VERSION "ZCU_CANFD2"

NS_ :

BS_ :

BU_ :  ETC IHU ZCUD ZCUP

BO_ 293 DhuZCUCANFD2Fr21 : 64 IHU
 SG_ DrvModReqForChampnMod : 7|3@0+ (1,0) [0|7] "" ZCUD
 SG_ DrvModReqForChampnMod_UB : 4|1@0+ (1,0) [0|1] "" ZCUD
 SG_ MusicInfoSeg11_UB : 0|1@0+ (1,0) [0|1] "" ZCUP
 SG_ MusicInfoSeg11SegFftLiShow1 : 15|4@0+ (1.0,0.0) [0.0|15.0] "Unitless" ZCUP
 SG_ MusicInfoSeg11SegFftLiShow10 : 43|4@0+ (1.0,0.0) [0.0|15.0] "Unitless" ZCUP
 SG_ MusicInfoSeg11SegFftLiShow11 : 55|4@0+ (1.0,0.0) [0.0|15.0] "Unitless" ZCUP
 SG_ MusicInfoSeg11SegFftLiShow12 : 51|4@0+ (1.0,0.0) [0.0|15.0] "Unitless" ZCUP
 SG_ MusicInfoSeg11SegFftLiShow13 : 63|4@0+ (1.0,0.0) [0.0|15.0] "Unitless" ZCUP
 SG_ MusicInfoSeg11SegFftLiShow14 : 59|4@0+ (1.0,0.0) [0.0|15.0] "Unitless" ZCUP
 SG_ MusicInfoSeg11SegFftLiShow2 : 11|4@0+ (1.0,0.0) [0.0|15.0] "Unitless" ZCUP
 SG_ MusicInfoSeg11SegFftLiShow3 : 23|4@0+ (1.0,0.0) [0.0|15.0] "Unitless" ZCUP
 SG_ MusicInfoSeg11SegFftLiShow4 : 19|4@0+ (1.0,0.0) [0.0|15.0] "Unitless" ZCUP
 SG_ MusicInfoSeg11SegFftLiShow5 : 31|4@0+ (1.0,0.0) [0.0|15.0] "Unitless" ZCUP
 SG_ MusicInfoSeg11SegFftLiShow6 : 27|4@0+ (1.0,0.0) [0.0|15.0] "Unitless" ZCUP
 SG_ MusicInfoSeg11SegFftLiShow7 : 39|4@0+ (1.0,0.0) [0.0|15.0] "Unitless" ZCUP
 SG_ MusicInfoSeg11SegFftLiShow8 : 35|4@0+ (1.0,0.0) [0.0|15.0] "Unitless" ZCUP
 SG_ MusicInfoSeg11SegFftLiShow9 : 47|4@0+ (1.0,0.0) [0.0|15.0] "Unitless" ZCUP
 SG_ MusicInfoSeg11TimeFlagMessage : 71|4@0+ (1.0,0.0) [0.0|15.0] "Unitless" ZCUP
 SG_ MusicInfoSeg11TimeFlagMusicplay : 67|4@0+ (1.0,0.0) [0.0|15.0] "Unitless" ZCUP
 SG_ MusicInfoSeg12_UB : 1|1@0+ (1,0) [0|1] "" ZCUP
 SG_ MusicInfoSeg12SegFftLiShow15 : 79|4@0+ (1.0,0.0) [0.0|15.0] "Unitless" ZCUP
 SG_ MusicInfoSeg12SegFftLiShow16 : 75|4@0+ (1.0,0.0) [0.0|15.0] "Unitless" ZCUP
 SG_ MusicInfoSeg12SegFftLiShow17 : 87|4@0+ (1.0,0.0) [0.0|15.0] "Unitless" ZCUP
 SG_ MusicInfoSeg12SegFftLiShow18 : 83|4@0+ (1.0,0.0) [0.0|15.0] "Unitless" ZCUP
 SG_ MusicInfoSeg12SegFftLiShow19 : 95|4@0+ (1.0,0.0) [0.0|15.0] "Unitless" ZCUP
 SG_ MusicInfoSeg12SegFftLiShow20 : 91|4@0+ (1.0,0.0) [0.0|15.0] "Unitless" ZCUP
 SG_ MusicInfoSeg12SegFftLiShow21 : 103|4@0+ (1.0,0.0) [0.0|15.0] "Unitless" ZCUP
 SG_ MusicInfoSeg12SegFftLiShow22 : 99|4@0+ (1.0,0.0) [0.0|15.0] "Unitless" ZCUP
 SG_ MusicInfoSeg12SegFftLiShow23 : 111|4@0+ (1.0,0.0) [0.0|15.0] "Unitless" ZCUP
 SG_ MusicInfoSeg12SegFftLiShow24 : 107|4@0+ (1.0,0.0) [0.0|15.0] "Unitless" ZCUP
 SG_ MusicInfoSeg12SegFftLiShow25 : 119|4@0+ (1.0,0.0) [0.0|15.0] "Unitless" ZCUP
 SG_ MusicInfoSeg12SegFftLiShow26 : 115|4@0+ (1.0,0.0) [0.0|15.0] "Unitless" ZCUP
 SG_ MusicInfoSeg12SegFftLiShow27 : 127|4@0+ (1.0,0.0) [0.0|15.0] "Unitless" ZCUP
 SG_ MusicInfoSeg12SegFftLiShow28 : 123|4@0+ (1.0,0.0) [0.0|15.0] "Unitless" ZCUP
 SG_ MusicInfoSeg12TimeFlagMessage : 135|4@0+ (1.0,0.0) [0.0|15.0] "Unitless" ZCUP
 SG_ MusicInfoSeg12TimeFlagMusicplay : 131|4@0+ (1.0,0.0) [0.0|15.0] "Unitless" ZCUP
 SG_ MusicInfoSeg13_UB : 297|1@0+ (1,0) [0|1] "" ZCUP
 SG_ MusicInfoSeg13DownSamplingAmplitude : 271|4@0+ (1.0,0.0) [0.0|15.0] "Unitless" ZCUP
 SG_ MusicInfoSeg13MaxFFT100ms3kAmplitude : 267|4@0+ (1.0,0.0) [0.0|15.0] "Unitless" ZCUP
 SG_ MusicInfoSeg13MaxFFT100ms3kFrequency : 279|8@0+ (1.0,0.0) [0.0|255.0] "Unitless" ZCUP
 SG_ MusicInfoSeg13SegFftLiShow29 : 287|4@0+ (1.0,0.0) [0.0|15.0] "Unitless" ZCUP
 SG_ MusicInfoSeg13SegFftLiShow30 : 283|4@0+ (1.0,0.0) [0.0|15.0] "Unitless" ZCUP
 SG_ MusicInfoSeg13SegFftLiShow31 : 295|4@0+ (1.0,0.0) [0.0|15.0] "Unitless" ZCUP
 SG_ MusicInfoSeg13StateFlagMusicPlay : 299|1@0+ (1,0) [0|1] "" ZCUP
 SG_ MusicInfoSeg13StateFlagNewMusic : 298|1@0+ (1,0) [0|1] "" ZCUP
 SG_ MusicInfoSeg13TimeFlagMessage : 291|4@0+ (1.0,0.0) [0.0|15.0] "Unitless" ZCUP
 SG_ MusicInfoSeg13TimeFlagMusicplay : 303|4@0+ (1.0,0.0) [0.0|15.0] "Unitless" ZCUP
 SG_ MusicInfoSeg21_UB : 2|1@0+ (1,0) [0|1] "" ZCUP
 SG_ MusicInfoSeg21SegFftLiShow1 : 143|4@0+ (1.0,0.0) [0.0|15.0] "Unitless" ZCUP
 SG_ MusicInfoSeg21SegFftLiShow10 : 171|4@0+ (1.0,0.0) [0.0|15.0] "Unitless" ZCUP
 SG_ MusicInfoSeg21SegFftLiShow11 : 183|4@0+ (1.0,0.0) [0.0|15.0] "Unitless" ZCUP
 SG_ MusicInfoSeg21SegFftLiShow12 : 179|4@0+ (1.0,0.0) [0.0|15.0] "Unitless" ZCUP
 SG_ MusicInfoSeg21SegFftLiShow13 : 191|4@0+ (1.0,0.0) [0.0|15.0] "Unitless" ZCUP
 SG_ MusicInfoSeg21SegFftLiShow14 : 187|4@0+ (1.0,0.0) [0.0|15.0] "Unitless" ZCUP
 SG_ MusicInfoSeg21SegFftLiShow2 : 139|4@0+ (1.0,0.0) [0.0|15.0] "Unitless" ZCUP
 SG_ MusicInfoSeg21SegFftLiShow3 : 151|4@0+ (1.0,0.0) [0.0|15.0] "Unitless" ZCUP
 SG_ MusicInfoSeg21SegFftLiShow4 : 147|4@0+ (1.0,0.0) [0.0|15.0] "Unitless" ZCUP
 SG_ MusicInfoSeg21SegFftLiShow5 : 159|4@0+ (1.0,0.0) [0.0|15.0] "Unitless" ZCUP
 SG_ MusicInfoSeg21SegFftLiShow6 : 155|4@0+ (1.0,0.0) [0.0|15.0] "Unitless" ZCUP
 SG_ MusicInfoSeg21SegFftLiShow7 : 167|4@0+ (1.0,0.0) [0.0|15.0] "Unitless" ZCUP
 SG_ MusicInfoSeg21SegFftLiShow8 : 163|4@0+ (1.0,0.0) [0.0|15.0] "Unitless" ZCUP
 SG_ MusicInfoSeg21SegFftLiShow9 : 175|4@0+ (1.0,0.0) [0.0|15.0] "Unitless" ZCUP
 SG_ MusicInfoSeg21TimeFlagMessage : 199|4@0+ (1.0,0.0) [0.0|15.0] "Unitless" ZCUP
 SG_ MusicInfoSeg21TimeFlagMusicplay : 195|4@0+ (1.0,0.0) [0.0|15.0] "Unitless" ZCUP
 SG_ MusicInfoSeg22_UB : 3|1@0+ (1,0) [0|1] "" ZCUP
 SG_ MusicInfoSeg22SegFftLiShow15 : 207|4@0+ (1.0,0.0) [0.0|15.0] "Unitless" ZCUP
 SG_ MusicInfoSeg22SegFftLiShow16 : 203|4@0+ (1.0,0.0) [0.0|15.0] "Unitless" ZCUP
 SG_ MusicInfoSeg22SegFftLiShow17 : 215|4@0+ (1.0,0.0) [0.0|15.0] "Unitless" ZCUP
 SG_ MusicInfoSeg22SegFftLiShow18 : 211|4@0+ (1.0,0.0) [0.0|15.0] "Unitless" ZCUP
 SG_ MusicInfoSeg22SegFftLiShow19 : 223|4@0+ (1.0,0.0) [0.0|15.0] "Unitless" ZCUP
 SG_ MusicInfoSeg22SegFftLiShow20 : 219|4@0+ (1.0,0.0) [0.0|15.0] "Unitless" ZCUP
 SG_ MusicInfoSeg22SegFftLiShow21 : 231|4@0+ (1.0,0.0) [0.0|15.0] "Unitless" ZCUP
 SG_ MusicInfoSeg22SegFftLiShow22 : 227|4@0+ (1.0,0.0) [0.0|15.0] "Unitless" ZCUP
 SG_ MusicInfoSeg22SegFftLiShow23 : 239|4@0+ (1.0,0.0) [0.0|15.0] "Unitless" ZCUP
 SG_ MusicInfoSeg22SegFftLiShow24 : 235|4@0+ (1.0,0.0) [0.0|15.0] "Unitless" ZCUP
 SG_ MusicInfoSeg22SegFftLiShow25 : 247|4@0+ (1.0,0.0) [0.0|15.0] "Unitless" ZCUP
 SG_ MusicInfoSeg22SegFftLiShow26 : 243|4@0+ (1.0,0.0) [0.0|15.0] "Unitless" ZCUP
 SG_ MusicInfoSeg22SegFftLiShow27 : 255|4@0+ (1.0,0.0) [0.0|15.0] "Unitless" ZCUP
 SG_ MusicInfoSeg22SegFftLiShow28 : 251|4@0+ (1.0,0.0) [0.0|15.0] "Unitless" ZCUP
 SG_ MusicInfoSeg22TimeFlagMessage : 263|4@0+ (1.0,0.0) [0.0|15.0] "Unitless" ZCUP
 SG_ MusicInfoSeg22TimeFlagMusicplay : 259|4@0+ (1.0,0.0) [0.0|15.0] "Unitless" ZCUP
 SG_ MusicInfoSeg23_UB : 296|1@0+ (1,0) [0|1] "" ZCUP
 SG_ MusicInfoSeg23DownSamplingAmplitude : 311|4@0+ (1.0,0.0) [0.0|15.0] "Unitless" ZCUP
 SG_ MusicInfoSeg23MaxFFT100ms3kAmplitude : 307|4@0+ (1.0,0.0) [0.0|15.0] "Unitless" ZCUP
 SG_ MusicInfoSeg23MaxFFT100ms3kFrequency : 319|8@0+ (1.0,0.0) [0.0|255.0] "Unitless" ZCUP
 SG_ MusicInfoSeg23SegFftLiShow29 : 327|4@0+ (1.0,0.0) [0.0|15.0] "Unitless" ZCUP
 SG_ MusicInfoSeg23SegFftLiShow30 : 323|4@0+ (1.0,0.0) [0.0|15.0] "Unitless" ZCUP
 SG_ MusicInfoSeg23SegFftLiShow31 : 335|4@0+ (1.0,0.0) [0.0|15.0] "Unitless" ZCUP
 SG_ MusicInfoSeg23StateFlagMusicPlay : 339|1@0+ (1,0) [0|1] "" ZCUP
 SG_ MusicInfoSeg23StateFlagNewMusic : 338|1@0+ (1,0) [0|1] "" ZCUP
 SG_ MusicInfoSeg23TimeFlagMessage : 331|4@0+ (1.0,0.0) [0.0|15.0] "Unitless" ZCUP
 SG_ MusicInfoSeg23TimeFlagMusicplay : 343|4@0+ (1.0,0.0) [0.0|15.0] "Unitless" ZCUP
 SG_ PrkgLiShowSwt : 337|2@0+ (1,0) [0|3] "" ZCUD
 SG_ PrkgLiShowSwt_UB : 351|1@0+ (1,0) [0|1] "" ZCUD

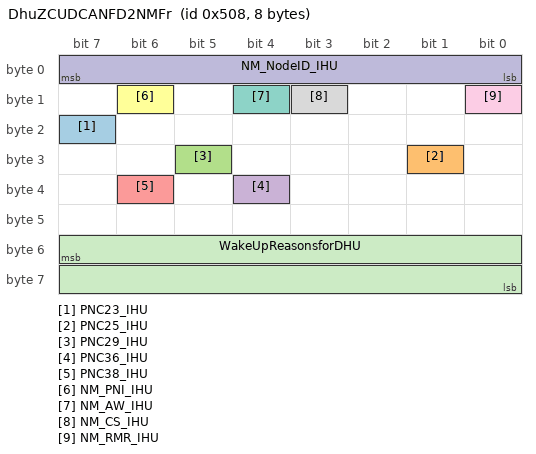
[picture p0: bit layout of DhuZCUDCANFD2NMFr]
BO_ 1288 DhuZCUDCANFD2NMFr : 8 IHU
 SG_ PNC23_IHU : 23|1@0+ (1,0) [0|0] "" Vector__XXX
 SG_ PNC25_IHU : 25|1@0+ (1,0) [0|0] "" Vector__XXX
 SG_ PNC29_IHU : 29|1@0+ (1,0) [0|0] "" Vector__XXX
 SG_ PNC36_IHU : 36|1@0+ (1,0) [0|0] "" Vector__XXX
 SG_ PNC38_IHU : 38|1@0+ (1,0) [0|0] "" Vector__XXX
 SG_ NM_PNI_IHU : 14|1@0+ (1,0) [0|0] "" Vector__XXX
 SG_ NM_AW_IHU : 12|1@0+ (1,0) [0|0] "" Vector__XXX
 SG_ NM_CS_IHU : 11|1@0+ (1,0) [0|0] "" Vector__XXX
 SG_ NM_RMR_IHU : 8|1@0+ (1,0) [0|0] "" Vector__XXX
 SG_ NM_NodeID_IHU : 7|8@0+ (1,0) [0|0] "" Vector__XXX

 SG_ WakeUpReasonsforDHU : 55|16@0+ (1,0) [0|65535] "" Vector__XXX

BO_ 1412 EtctoZcudXCPFr01 : 64 ETC

BO_ 1377 ETCZCUCANFD2DEVFr01 : 64 ETC
 SG_ ZCUDMdevelpsignalgroupReq_UB : 504|1@0+ (1,0) [0|1] "" ZCUD
 SG_ ZCUDMdevelpsignalgroupReqFunctiondevpsignalgroup1 : 7|8@0+ (1.0,0.0) [0.0|255.0] "Unitless" ZCUD
 SG_ ZCUDMdevelpsignalgroupReqFunctiondevpsignalgroup2 : 15|8@0+ (1.0,0.0) [0.0|255.0] "Unitless" ZCUD
 SG_ ZCUDMdevelpsignalgroupReqFunctiondevpsignalgroup3 : 23|8@0+ (1.0,0.0) [0.0|255.0] "Unitless" ZCUD
 SG_ ZCUDMdevelpsignalgroupReqFunctiondevpsignalgroup4 : 31|8@0+ (1.0,0.0) [0.0|255.0] "Unitless" ZCUD
 SG_ ZCUDMdevelpsignalgroupReqFunctiondevpsignalgroup5 : 39|8@0+ (1.0,0.0) [0.0|255.0] "Unitless" ZCUD
 SG_ ZCUDMdevelpsignalgroupReqFunctiondevpsignalgroup6 : 47|8@0+ (1.0,0.0) [0.0|255.0] "Unitless" ZCUD
 SG_ ZCUDMdevelpsignalgroupReqFunctiondevpsignalgroup7 : 55|8@0+ (1.0,0.0) [0.0|255.0] "Unitless" ZCUD
 SG_ ZCUDMdevelpsignalgroupReqFunctiondevpsignalgroup8 : 63|8@0+ (1.0,0.0) [0.0|255.0] "Unitless" ZCUD
 SG_ ZCUPdevelpsignalgroupReq_UB : 505|1@0+ (1,0) [0|1] "" ZCUP
 SG_ ZCUPdevelpsignalgroupReqFunctiondevpsignalgroup1 : 71|8@0+ (1.0,0.0) [0.0|255.0] "Unitless" ZCUP
 SG_ ZCUPdevelpsignalgroupReqFunctiondevpsignalgroup2 : 79|8@0+ (1.0,0.0) [0.0|255.0] "Unitless" ZCUP
 SG_ ZCUPdevelpsignalgroupReqFunctiondevpsignalgroup3 : 87|8@0+ (1.0,0.0) [0.0|255.0] "Unitless" ZCUP
 SG_ ZCUPdevelpsignalgroupReqFunctiondevpsignalgroup4 : 95|8@0+ (1.0,0.0) [0.0|255.0] "Unitless" ZCUP
 SG_ ZCUPdevelpsignalgroupReqFunctiondevpsignalgroup5 : 103|8@0+ (1.0,0.0) [0.0|255.0] "Unitless" ZCUP
 SG_ ZCUPdevelpsignalgroupReqFunctiondevpsignalgroup6 : 111|8@0+ (1.0,0.0) [0.0|255.0] "Unitless" ZCUP
 SG_ ZCUPdevelpsignalgroupReqFunctiondevpsignalgroup7 : 119|8@0+ (1.0,0.0) [0.0|255.0] "Unitless" ZCUP
 SG_ ZCUPdevelpsignalgroupReqFunctiondevpsignalgroup8 : 127|8@0+ (1.0,0.0) [0.0|255.0] "Unitless" ZCUP

BO_ 1715 ZcudHcmlToDhuZCUCANFD2DiagResFr : 64 ZCUD

BO_ 1716 ZcudHcmrToDhuZCUCANFD2DiagResFr : 64 ZCUD

BO_ 1557 ZcudPotToDhuZCUCANFD2DiagResFr : 64 ZCUD

BO_ 1552 ZcudRmlToDhuZCUCANFD2DiagResFr : 64 ZCUD

BO_ 1553 ZcudRmrToDhuZCUCANFD2DiagResFr : 64 ZCUD

BO_ 1585 ZcudSmblToDhuZCUCANFD2DiagResFr : 64 ZCUD

BO_ 1586 ZcudSmbrToDhuZCUCANFD2DiagResFr : 64 ZCUD

BO_ 1577 ZcudSmbToDhuZCUCANFD2DiagResFr : 64 ZCUD

BO_ 2041 ZcudSrsToDhuISO26021ZCUCanFD2ResFr : 8 ZCUD

BO_ 1593 ZcudSrsToDhuZCUCANFD2DiagResFr : 64 ZCUD

BO_ 1650 ZcudSwmToDhuZCUCANFD2DiagResFr : 64 ZCUD

BO_ 1537 ZcudToDhuZCUCANFD2DiagResFr : 64 ZCUD

BO_ 1408 ZcudtoETCXcpFr01 : 64 ZCUD

BO_ 1409 ZcudtoETCXcpFr02 : 64 ZCUD

BO_ 1410 ZcudtoETCXcpFr03 : 64 ZCUD

BO_ 1411 ZcudtoETCXcpFr04 : 64 ZCUD

BO_ 1378 ZCUDZCUCANFD2DEVFr01 : 64 ZCUD
 SG_ ZCUDMdevelpsignalgroupResp_UB : 504|1@0+ (1,0) [0|1] "" ETC
 SG_ ZCUDMdevelpsignalgroupRespFunctiondevpsignalgroup1 : 7|8@0+ (1.0,0.0) [0.0|255.0] "Unitless" ETC
 SG_ ZCUDMdevelpsignalgroupRespFunctiondevpsignalgroup2 : 15|8@0+ (1.0,0.0) [0.0|255.0] "Unitless" ETC
 SG_ ZCUDMdevelpsignalgroupRespFunctiondevpsignalgroup3 : 23|8@0+ (1.0,0.0) [0.0|255.0] "Unitless" ETC
 SG_ ZCUDMdevelpsignalgroupRespFunctiondevpsignalgroup4 : 31|8@0+ (1.0,0.0) [0.0|255.0] "Unitless" ETC
 SG_ ZCUDMdevelpsignalgroupRespFunctiondevpsignalgroup5 : 39|8@0+ (1.0,0.0) [0.0|255.0] "Unitless" ETC
 SG_ ZCUDMdevelpsignalgroupRespFunctiondevpsignalgroup6 : 47|8@0+ (1.0,0.0) [0.0|255.0] "Unitless" ETC
 SG_ ZCUDMdevelpsignalgroupRespFunctiondevpsignalgroup7 : 55|8@0+ (1.0,0.0) [0.0|255.0] "Unitless" ETC
 SG_ ZCUDMdevelpsignalgroupRespFunctiondevpsignalgroup8 : 63|8@0+ (1.0,0.0) [0.0|255.0] "Unitless" ETC
 SG_ ZCUDMDevpFrameForDebug_UB : 505|1@0+ (1,0) [0|1] "" ETC
 SG_ ZCUDMDevpFrameForDebugFunctiondevpsignalgroup1 : 71|8@0+ (1.0,0.0) [0.0|255.0] "Unitless" ETC
 SG_ ZCUDMDevpFrameForDebugFunctiondevpsignalgroup2 : 79|8@0+ (1.0,0.0) [0.0|255.0] "Unitless" ETC
 SG_ ZCUDMDevpFrameForDebugFunctiondevpsignalgroup3 : 87|8@0+ (1.0,0.0) [0.0|255.0] "Unitless" ETC
 SG_ ZCUDMDevpFrameForDebugFunctiondevpsignalgroup4 : 95|8@0+ (1.0,0.0) [0.0|255.0] "Unitless" ETC
 SG_ ZCUDMDevpFrameForDebugFunctiondevpsignalgroup5 : 103|8@0+ (1.0,0.0) [0.0|255.0] "Unitless" ETC
 SG_ ZCUDMDevpFrameForDebugFunctiondevpsignalgroup6 : 111|8@0+ (1.0,0.0) [0.0|255.0] "Unitless" ETC
 SG_ ZCUDMDevpFrameForDebugFunctiondevpsignalgroup7 : 119|8@0+ (1.0,0.0) [0.0|255.0] "Unitless" ETC
 SG_ ZCUDMDevpFrameForDebugFunctiondevpsignalgroup8 : 127|8@0+ (1.0,0.0) [0.0|255.0] "Unitless" ETC

BO_ 1169 ZCUDZCUCANFD2Fr01 : 64 ZCUD
 SG_ AccrpedlSts_UB : 13|1@0+ (1,0) [0|1] "" IHU
 SG_ AccrpedlStsChks : 23|8@0+ (1.0,0.0) [0.0|255.0] "Unitless" IHU
 SG_ AccrpedlStsCntr : 11|4@0+ (1.0,0.0) [0.0|15.0] "Unitless" IHU
 SG_ AccrpedlStsFltSts : 12|1@0+ (1,0) [0|1] "" IHU
 SG_ ActnOfLedHiBeam : 31|1@0+ (1,0) [0|1] "" IHU
 SG_ ActnOfLedHiBeam_UB : 30|1@0+ (1,0) [0|1] "" IHU
 SG_ ActnOfLedLoBeam_UB : 29|1@0+ (1,0) [0|1] "" IHU
 SG_ ActnOfLedLoBeamActnOfLedLoBeam : 28|1@0+ (1,0) [0|1] "" IHU
 SG_ ActnOfLedLoBeamChks : 39|8@0+ (1.0,0.0) [0.0|255.0] "Unitless" IHU
 SG_ ActnOfLedLoBeamCntr : 27|4@0+ (1.0,0.0) [0.0|15.0] "Unitless" IHU
 SG_ ActvnOfWiprRe : 63|1@0+ (1,0) [0|1] "" IHU
 SG_ ActvnOfWiprRe_UB : 62|1@0+ (1,0) [0|1] "" IHU
 SG_ AsySftyStandStillReq : 61|1@0+ (1,0) [0|1] "" IHU
 SG_ AsySftyStandStillReq_UB : 60|1@0+ (1,0) [0|1] "" IHU
 SG_ BattChrgnBalDurgDrvgRaw : 47|16@0+ (0.005,-100.0) [-100.0|100.0] "Ah" IHU
 SG_ BattChrgnBalDurgDrvgRaw_UB : 14|1@0+ (1,0) [0|1] "" IHU
 SG_ BattCircOpenU : 71|5@0+ (0.25,6.0) [6.0|13.75] "Volt" IHU
 SG_ BattCircOpenU_UB : 66|1@0+ (1,0) [0|1] "" IHU
 SG_ BattCpEstimdAtTNomRaw : 79|7@0+ (1.0,0.0) [0.0|100.0] "Ah" IHU
 SG_ BattCpEstimdAtTNomRaw_UB : 72|1@0+ (1,0) [0|1] "" IHU
 SG_ BattCpRel : 87|8@0+ (0.01,0.0) [0.0|2.5] "Cn" IHU
 SG_ BattCpRel_UB : 65|1@0+ (1,0) [0|1] "" IHU
 SG_ BattCycChrgCntrRaw : 95|14@0+ (0.05,0.0) [0.0|800.0] "Cn" IHU
 SG_ BattCycChrgCntrRaw_UB : 504|1@0+ (1,0) [0|1] "" IHU
 SG_ BattCycDchaCntrDurgConvceRaw : 111|14@0+ (0.05,0.0) [0.0|800.0] "Cn" IHU
 SG_ BattCycDchaCntrDurgConvceRaw_UB : 113|1@0+ (1,0) [0|1] "" IHU
 SG_ BattCycDchaCntrDurgDrvgRaw : 135|14@0+ (0.05,0.0) [0.0|800.0] "Cn" IHU
 SG_ BattCycDchaCntrDurgDrvgRaw_UB : 137|1@0+ (1,0) [0|1] "" IHU
 SG_ BattCycDchaCntrDurgQuiscPhaRaw : 159|14@0+ (0.015625,0.0) [0.0|255.0] "Cn" IHU
 SG_ BattCycDchaCntrDurgQuiscPhaRaw_UB : 161|1@0+ (1,0) [0|1] "" IHU
 SG_ BattIQuiscAvgRaw : 112|9@0+ (5.0,-2555.0) [-2500.0|0.0] "mA" IHU
 SG_ BattIQuiscAvgRaw_UB : 64|1@0+ (1,0) [0|1] "" IHU
 SG_ BattIQuiscFildLongRaw : 136|9@0+ (1.0,-511.0) [-511.0|0.0] "mA" IHU
 SG_ BattIQuiscFildLongRaw_UB : 97|1@0+ (1,0) [0|1] "" IHU
 SG_ BattIQuiscFildShoRaw : 160|9@0+ (1.0,-511.0) [-511.0|0.0] "mA" IHU
 SG_ BattIQuiscFildShoRaw_UB : 96|1@0+ (1,0) [0|1] "" IHU
 SG_ BattIRaw : 183|16@0+ (0.015625,-512.0) [-512.0|511.984375] "A" IHU
 SG_ BattIRaw_UB : 199|1@0+ (1,0) [0|1] "" IHU
 SG_ BattRAtTNomRaw : 207|8@0+ (0.1,0.0) [0.0|25.0] "mOhm" IHU
 SG_ BattRAtTNomRaw_UB : 198|1@0+ (1,0) [0|1] "" IHU
 SG_ BattRRaw : 215|8@0+ (0.1,0.0) [0.0|25.0] "mOhm" IHU
 SG_ BattRRaw_UB : 197|1@0+ (1,0) [0|1] "" IHU
 SG_ BattSnsrCalcnNotVldRaw : 59|1@0+ (1,0) [0|1] "" IHU
 SG_ BattSnsrCalcnNotVldRaw_UB : 58|1@0+ (1,0) [0|1] "" IHU
 SG_ BattSnsrHwFltRaw : 57|1@0+ (1,0) [0|1] "" IHU
 SG_ BattSnsrHwFltRaw_UB : 56|1@0+ (1,0) [0|1] "" IHU
 SG_ BattTiInSrvRaw : 223|12@0+ (1.0,0.0) [0.0|4095.0] "Days" IHU
 SG_ BattTiInSrvRaw_UB : 227|1@0+ (1,0) [0|1] "" IHU
 SG_ BattTRaw : 224|9@0+ (0.5,-128.0) [-70.0|125.0] "degC" IHU
 SG_ BattTRaw_UB : 226|1@0+ (1,0) [0|1] "" IHU
 SG_ CarModDispdWdDispd : 196|4@0+ (1,0) [0|15] "" IHU
 SG_ CarModDispdWdDispd_UB : 192|1@0+ (1,0) [0|1] "" IHU
 SG_ CarModDynoReq : 255|3@0+ (1,0) [0|7] "" IHU
 SG_ CarModDynoReq_UB : 241|1@0+ (1,0) [0|1] "" IHU
 SG_ CEMdevelpsignalgroupVMM1_UB : 240|1@0+ (1,0) [0|1] "" ETC,IHU
 SG_ CEMdevelpsignalgroupVMM1Functiondevpsignalgroup1 : 263|8@0+ (1.0,0.0) [0.0|255.0] "Unitless" ETC,IHU
 SG_ CEMdevelpsignalgroupVMM1Functiondevpsignalgroup2 : 271|8@0+ (1.0,0.0) [0.0|255.0] "Unitless" ETC,IHU
 SG_ CEMdevelpsignalgroupVMM1Functiondevpsignalgroup3 : 279|8@0+ (1.0,0.0) [0.0|255.0] "Unitless" ETC,IHU
 SG_ CEMdevelpsignalgroupVMM1Functiondevpsignalgroup4 : 287|8@0+ (1.0,0.0) [0.0|255.0] "Unitless" ETC,IHU
 SG_ CEMdevelpsignalgroupVMM1Functiondevpsignalgroup5 : 295|8@0+ (1.0,0.0) [0.0|255.0] "Unitless" ETC,IHU
 SG_ CEMdevelpsignalgroupVMM1Functiondevpsignalgroup6 : 303|8@0+ (1.0,0.0) [0.0|255.0] "Unitless" ETC,IHU
 SG_ CEMdevelpsignalgroupVMM1Functiondevpsignalgroup7 : 311|8@0+ (1.0,0.0) [0.0|255.0] "Unitless" ETC,IHU
 SG_ CEMdevelpsignalgroupVMM1Functiondevpsignalgroup8 : 319|8@0+ (1.0,0.0) [0.0|255.0] "Unitless" ETC,IHU
 SG_ CmptFrntWindDewT : 327|11@0+ (0.1,-40.0) [-40.0|164.70000000000002] "degC" IHU
 SG_ CmptFrntWindDewT_UB : 332|1@0+ (1,0) [0|1] "" IHU
 SG_ CmptFrntWindT : 330|11@0+ (0.1,-40.0) [-40.0|164.70000000000002] "degC" IHU
 SG_ CmptFrntWindT_UB : 331|1@0+ (1,0) [0|1] "" IHU
 SG_ CnvnAllwd : 351|1@0+ (1,0) [0|1] "" IHU
 SG_ CnvnAllwd_UB : 350|1@0+ (1,0) [0|1] "" IHU
 SG_ CnvnReq : 252|3@0+ (1,0) [0|7] "" IHU
 SG_ CnvnReq_UB : 349|1@0+ (1,0) [0|1] "" IHU
 SG_ DoorDrvrSwtIntrLockgReq : 249|2@0+ (1,0) [0|3] "" ETC,IHU
 SG_ DoorDrvrSwtIntrLockgReq_UB : 348|1@0+ (1,0) [0|1] "" ETC,IHU
 SG_ DrvrSteerWhlHldGroup_UB : 432|1@0+ (1,0) [0|1] "" IHU
 SG_ DrvrSteerWhlHldGroupDrvrSteerWhlHld : 435|2@0+ (1,0) [0|3] "" IHU
 SG_ DrvrSteerWhlHldGroupDrvrSteerWhlHldQly : 439|4@0+ (1.0,0.0) [0.0|15.0] "Unitless" IHU
 SG_ EgyLvlElecDrvInfo : 447|2@0+ (1.0,0.0) [0.0|3.0] "Unitless" IHU
 SG_ EgyLvlElecDrvInfo_UB : 445|1@0+ (1,0) [0|1] "" IHU
 SG_ EgyMeas : 444|13@0+ (0.01,0.0) [0.0|81.91] "Ah" IHU
 SG_ EgyMeas_UB : 503|1@0+ (1,0) [0|1] "" IHU
 SG_ EgyMeasIntl_UB : 502|1@0+ (1,0) [0|1] "" IHU
 SG_ EgyMeasIntlIntl1 : 463|8@0+ (1.0,0.0) [0.0|255.0] "Unitless" IHU
 SG_ EgyMeasIntlIntl2 : 471|8@0+ (1.0,0.0) [0.0|255.0] "Unitless" IHU
 SG_ EgyMeasIntlIntl3 : 479|8@0+ (1.0,0.0) [0.0|255.0] "Unitless" IHU
 SG_ EgyMeasIntlIntl4 : 487|8@0+ (1.0,0.0) [0.0|255.0] "Unitless" IHU
 SG_ EgyMeasSec : 495|8@0+ (0.5,0.0) [0.0|127.5] "Ah" IHU
 SG_ EgyMeasSec_UB : 501|1@0+ (1,0) [0|1] "" IHU
 SG_ ElecMot2ModReq : 499|4@0+ (1,0) [0|15] "" Vector__XXX
 SG_ ElecMot2ModReq_UB : 511|1@0+ (1,0) [0|1] "" Vector__XXX

BO_ 306 ZCUDZCUCANFD2Fr02 : 64 ZCUD
 SG_ ActnOfDaytiRunngLampPass : 7|1@0+ (1,0) [0|1] "" IHU,ZCUP
 SG_ ActnOfDaytiRunngLampPass_UB : 104|1@0+ (1,0) [0|1] "" IHU,ZCUP
 SG_ ActnOfDynRePos : 6|3@0+ (1.0,0.0) [0.0|7.0] "Unitless" IHU,ZCUP
 SG_ ActnOfDynRePos_UB : 105|1@0+ (1,0) [0|1] "" IHU,ZCUP
 SG_ ActnOfFrntFogLampPass : 3|1@0+ (1,0) [0|1] "" IHU,ZCUP
 SG_ ActnOfFrntFogLampPass_UB : 106|1@0+ (1,0) [0|1] "" IHU,ZCUP
 SG_ ActnOfFrntPosnLampPass : 2|1@0+ (1,0) [0|1] "" IHU,ZCUP
 SG_ ActnOfFrntPosnLampPass_UB : 107|1@0+ (1,0) [0|1] "" IHU,ZCUP
 SG_ ActnOfHiBeamPass : 1|1@0+ (1,0) [0|1] "" IHU,ZCUP
 SG_ ActnOfHiBeamPass_UB : 108|1@0+ (1,0) [0|1] "" IHU,ZCUP
 SG_ ActnOfLoBeamPass_UB : 208|1@0+ (1,0) [0|1] "" IHU,ZCUP
 SG_ ActnOfLoBeamPassChks : 239|8@0+ (1.0,0.0) [0.0|255.0] "Unitless" IHU,ZCUP
 SG_ ActnOfLoBeamPassCntr : 247|4@0+ (1.0,0.0) [0.0|15.0] "Unitless" IHU,ZCUP
 SG_ ActnOfLoBeamPassOnOff : 243|1@0+ (1,0) [0|1] "" IHU,ZCUP
 SG_ ActnOfReFogLampDrv : 15|1@0+ (1,0) [0|1] "" IHU,ZCUP
 SG_ ActnOfReFogLampDrv_UB : 110|1@0+ (1,0) [0|1] "" IHU,ZCUP
 SG_ ActnOfRePosnLampPass : 14|1@0+ (1,0) [0|1] "" IHU,ZCUP
 SG_ ActnOfRePosnLampPass_UB : 111|1@0+ (1,0) [0|1] "" IHU,ZCUP
 SG_ ActnOfReRegPlateLamp : 13|1@0+ (1,0) [0|1] "" IHU,ZCUP
 SG_ ActnOfReRegPlateLamp_UB : 112|1@0+ (1,0) [0|1] "" IHU,ZCUP
 SG_ ActnOfRvsgLampPass : 12|1@0+ (1,0) [0|1] "" IHU,ZCUP
 SG_ ActnOfRvsgLampPass_UB : 113|1@0+ (1,0) [0|1] "" IHU,ZCUP
 SG_ ActvnOfApproach : 11|1@0+ (1,0) [0|1] "" IHU,ZCUP
 SG_ ActvnOfApproach_UB : 114|1@0+ (1,0) [0|1] "" IHU,ZCUP
 SG_ ActvnOfCarLoctr : 10|1@0+ (1,0) [0|1] "" IHU,ZCUP
 SG_ ActvnOfCarLoctr_UB : 115|1@0+ (1,0) [0|1] "" IHU,ZCUP
 SG_ ActvnOfGoodByeLi : 9|1@0+ (1,0) [0|1] "" IHU,ZCUP
 SG_ ActvnOfGoodByeLi_UB : 116|1@0+ (1,0) [0|1] "" IHU,ZCUP
 SG_ ActvnOfHndlDoorLi1_UB : 117|1@0+ (1,0) [0|1] "" IHU,ZCUP
 SG_ ActvnOfHndlDoorLi1HndlDoorLiDrvr : 103|2@0+ (1,0) [0|3] "" IHU,ZCUP
 SG_ ActvnOfHndlDoorLi1HndlDoorLiDrvrRe : 101|2@0+ (1,0) [0|3] "" IHU,ZCUP
 SG_ ActvnOfHndlDoorLi1HndlDoorLiPass : 99|2@0+ (1,0) [0|3] "" IHU,ZCUP
 SG_ ActvnOfHndlDoorLi1HndlDoorLiPassRe : 97|2@0+ (1,0) [0|3] "" IHU,ZCUP
 SG_ ActvnOfHomeSafe : 8|1@0+ (1,0) [0|1] "" IHU,ZCUP
 SG_ ActvnOfHomeSafe_UB : 118|1@0+ (1,0) [0|1] "" IHU,ZCUP
 SG_ ActvnOfLiForComity : 23|1@0+ (1,0) [0|1] "" IHU,ZCUP
 SG_ ActvnOfLiForComity_UB : 119|1@0+ (1,0) [0|1] "" IHU,ZCUP
 SG_ ActvnOfLiForSpkr : 22|1@0+ (1,0) [0|1] "" IHU,ZCUP
 SG_ ActvnOfLiForSpkr_UB : 120|1@0+ (1,0) [0|1] "" IHU,ZCUP
 SG_ ActvnOfLiForWait : 21|1@0+ (1,0) [0|1] "" IHU,ZCUP
 SG_ ActvnOfLiForWait_UB : 121|1@0+ (1,0) [0|1] "" IHU,ZCUP
 SG_ ActvnOfPudLi : 20|1@0+ (1,0) [0|1] "" IHU,ZCUP
 SG_ ActvnOfPudLi_UB : 122|1@0+ (1,0) [0|1] "" IHU,ZCUP
 SG_ ActvnOfWaitMode : 19|1@0+ (1,0) [0|1] "" IHU,ZCUP
 SG_ ActvnOfWaitMode_UB : 123|1@0+ (1,0) [0|1] "" IHU,ZCUP
 SG_ BattFltStsPrim_UB : 402|1@0+ (1,0) [0|1] "" IHU,ZCUP
 SG_ BattFltStsPrimBattFltStsPrm : 415|4@0+ (1,0) [0|15] "" IHU,ZCUP
 SG_ BattFltStsPrimChks : 423|8@0+ (1.0,0.0) [0.0|255.0] "Unitless" IHU,ZCUP
 SG_ BattFltStsPrimCntr : 411|4@0+ (1.0,0.0) [0.0|15.0] "Unitless" IHU,ZCUP
 SG_ CarCfgInfoToWPC : 31|4@0+ (1.0,0.0) [0.0|15.0] "Unitless" IHU
 SG_ CarCfgInfoToWPC_UB : 125|1@0+ (1,0) [0|1] "" IHU
 SG_ ChdLockLeftSts : 215|2@0+ (1,0) [0|3] "" IHU
 SG_ ChdLockLeftSts_UB : 213|1@0+ (1,0) [0|1] "" IHU
 SG_ ChdLockRightStsToHmi : 202|2@0+ (1,0) [0|3] "" IHU
 SG_ ChdLockRightStsToHmi_UB : 200|1@0+ (1,0) [0|1] "" IHU
 SG_ ChdPrtnLeftStsToHmi : 212|2@0+ (1,0) [0|3] "" IHU
 SG_ ChdPrtnLeftStsToHmi_UB : 210|1@0+ (1,0) [0|1] "" IHU
 SG_ ChrgLidCombLockCmd : 27|3@0+ (1,0) [0|7] "" IHU,ZCUP
 SG_ ChrgLidCombLockCmd_UB : 126|1@0+ (1,0) [0|1] "" IHU,ZCUP
 SG_ ChrgnLtgSts : 143|2@0+ (1,0) [0|3] "" IHU
 SG_ ChrgnLtgSts_UB : 141|1@0+ (1,0) [0|1] "" IHU
 SG_ CinhDrvrReSts : 396|1@0+ (1,0) [0|1] "" ZCUP
 SG_ CinhDrvrReSts_UB : 395|1@0+ (1,0) [0|1] "" ZCUP
 SG_ CinhDrvrReSwt : 394|1@0+ (1,0) [0|1] "" ZCUP
 SG_ CinhDrvrReSwt_UB : 393|1@0+ (1,0) [0|1] "" ZCUP
 SG_ CinhDrvrSts : 407|1@0+ (1,0) [0|1] "" ZCUP
 SG_ CinhDrvrSts_UB : 392|1@0+ (1,0) [0|1] "" ZCUP
 SG_ CinhDrvrSwt : 406|1@0+ (1,0) [0|1] "" ZCUP
 SG_ CinhDrvrSwt_UB : 405|1@0+ (1,0) [0|1] "" ZCUP
 SG_ DchaChrgnTarValFb : 39|10@0+ (0.1,0.0) [0.0|100.0] "%" IHU
 SG_ DchaChrgnTarValFb_UB : 127|1@0+ (1,0) [0|1] "" IHU
 SG_ DigKeyPasEntryDiSts : 17|1@0+ (1,0) [0|1] "" IHU
 SG_ DigKeyPasEntryDiSts_UB : 128|1@0+ (1,0) [0|1] "" IHU
 SG_ DlyClsActv : 140|1@0+ (1,0) [0|1] "" IHU
 SG_ DlyClsActv_UB : 151|1@0+ (1,0) [0|1] "" IHU
 SG_ DoorLeReHndlCmd : 150|2@0+ (1,0) [0|3] "" ZCUP
 SG_ DoorLeReHndlCmd_UB : 148|1@0+ (1,0) [0|1] "" ZCUP
 SG_ DrvrGearLvrInfoIndcn : 158|3@0+ (1,0) [0|7] "" IHU
 SG_ DrvrGearLvrInfoIndcn_UB : 155|1@0+ (1,0) [0|1] "" IHU
 SG_ DrvrGearLvrLockIndcn : 45|4@0+ (1,0) [0|15] "" IHU
 SG_ DrvrGearLvrLockIndcn_UB : 129|1@0+ (1,0) [0|1] "" IHU
 SG_ DstTrvldFromSftyBkp : 255|21@0+ (1.0,0.0) [0.0|2000000.0] "km" IHU
 SG_ DstTrvldFromSftyBkp_UB : 240|1@0+ (1,0) [0|1] "" IHU
 SG_ DstTrvldVldFromSftyBkp : 242|1@0+ (1,0) [0|1] "" IHU
 SG_ DstTrvldVldFromSftyBkp_UB : 241|1@0+ (1,0) [0|1] "" IHU
 SG_ EmgyBrkLiIndcrTurn : 154|2@0+ (1,0) [0|3] "" IHU,ZCUP
 SG_ EmgyBrkLiIndcrTurn_UB : 152|1@0+ (1,0) [0|1] "" IHU,ZCUP
 SG_ ErsStrtApplSts : 41|2@0+ (1,0) [0|3] "" IHU
 SG_ ErsStrtApplSts_UB : 130|1@0+ (1,0) [0|1] "" IHU
 SG_ ExtrLiShowStoreStsFrntLe : 16|1@0+ (1,0) [0|1] "" IHU
 SG_ ExtrLiShowStoreStsFrntLe_UB : 131|1@0+ (1,0) [0|1] "" IHU
 SG_ ExtrLiShowStoreStsFrntRi : 24|1@0+ (1,0) [0|1] "" IHU
 SG_ ExtrLiShowStoreStsFrntRi_UB : 132|1@0+ (1,0) [0|1] "" IHU
 SG_ GlvBoxRelsReq : 55|1@0+ (1,0) [0|1] "" IHU,ZCUP
 SG_ GlvBoxRelsReq_UB : 133|1@0+ (1,0) [0|1] "" IHU,ZCUP
 SG_ HvBattHeatgReq : 54|2@0+ (1,0) [0|3] "" ZCUP
 SG_ HvBattHeatgReq_UB : 134|1@0+ (1,0) [0|1] "" ZCUP
 SG_ HvCooltWtrHeatrWtrTInIntk : 63|8@0+ (1.0,-40.0) [-40.0|215.0] "degC" IHU,ZCUP
 SG_ HvCooltWtrHeatrWtrTInIntk_UB : 135|1@0+ (1,0) [0|1] "" IHU,ZCUP
 SG_ HvCooltWtrHeatrWtrTInOutl : 71|8@0+ (1.0,-40.0) [-40.0|215.0] "degC" IHU,ZCUP
 SG_ HvCooltWtrHeatrWtrTInOutl_UB : 136|1@0+ (1,0) [0|1] "" IHU,ZCUP
 SG_ IndcrNoSeq : 167|1@0+ (1,0) [0|1] "" IHU,ZCUP
 SG_ IndcrNoSeq_UB : 166|1@0+ (1,0) [0|1] "" IHU,ZCUP
 SG_ KeyEnaSts_UB : 266|1@0+ (1,0) [0|1] "" IHU
 SG_ KeyEnaStsKey0 : 279|2@0+ (1,0) [0|3] "" IHU
 SG_ KeyEnaStsKey1 : 277|2@0+ (1,0) [0|3] "" IHU
 SG_ KeyEnaStsKey10 : 291|2@0+ (1,0) [0|3] "" IHU
 SG_ KeyEnaStsKey11 : 289|2@0+ (1,0) [0|3] "" IHU
 SG_ KeyEnaStsKey2 : 275|2@0+ (1,0) [0|3] "" IHU
 SG_ KeyEnaStsKey3 : 273|2@0+ (1,0) [0|3] "" IHU
 SG_ KeyEnaStsKey4 : 287|2@0+ (1,0) [0|3] "" IHU
 SG_ KeyEnaStsKey5 : 285|2@0+ (1,0) [0|3] "" IHU
 SG_ KeyEnaStsKey6 : 283|2@0+ (1,0) [0|3] "" IHU
 SG_ KeyEnaStsKey7 : 281|2@0+ (1,0) [0|3] "" IHU
 SG_ KeyEnaStsKey8 : 295|2@0+ (1,0) [0|3] "" IHU
 SG_ KeyEnaStsKey9 : 293|2@0+ (1,0) [0|3] "" IHU
 SG_ KeyScanActv : 404|1@0+ (1,0) [0|1] "" IHU
 SG_ KeyScanActv_UB : 403|1@0+ (1,0) [0|1] "" IHU
 SG_ MirrDefrstAtPassCmd : 52|1@0+ (1,0) [0|1] "" IHU,ZCUP
 SG_ MirrDefrstAtPassCmd_UB : 137|1@0+ (1,0) [0|1] "" IHU,ZCUP
 SG_ MirrDwnStsAtDrvr : 51|3@0+ (1,0) [0|7] "" IHU
 SG_ MirrDwnStsAtDrvr_UB : 138|1@0+ (1,0) [0|1] "" IHU
 SG_ MirrPosnAdjFromSetTarPosnPass_UB : 209|1@0+ (1,0) [0|1] "" ZCUP
 SG_ MirrPosnAdjFromSetTarPosnPassMirrPosnAdjCldLeRi : 223|8@0+ (1.0,0.0) [0.0|180.0] "Deg" ZCUP
 SG_ MirrPosnAdjFromSetTarPosnPassMirrPosnAdjCldUpDwn : 231|8@0+ (1.0,0.0) [0.0|180.0] "Deg" ZCUP
 SG_ PedProtnMsgReqForFlt : 79|2@0+ (1,0) [0|3] "" IHU
 SG_ PedProtnMsgReqForFlt_UB : 139|1@0+ (1,0) [0|1] "" IHU
 SG_ PedProtnMsgReqForImpct : 48|1@0+ (1,0) [0|1] "" IHU
 SG_ PedProtnMsgReqForImpct_UB : 88|1@0+ (1,0) [0|1] "" IHU
 SG_ PrpsnHvBattUsgOfChrgBlkd2 : 147|2@0+ (1,0) [0|3] "" Vector__XXX
 SG_ PrpsnHvBattUsgOfChrgBlkd2_UB : 145|1@0+ (1,0) [0|1] "" Vector__XXX
 SG_ PrpsnHvBattUsgOfHldBlkd2 : 353|2@0+ (1,0) [0|3] "" Vector__XXX
 SG_ PrpsnHvBattUsgOfHldBlkd2_UB : 354|1@0+ (1,0) [0|1] "" Vector__XXX
 SG_ RegenAutLvlNotAvlMsg : 77|1@0+ (1,0) [0|1] "" IHU
 SG_ RegenAutLvlNotAvlMsg_UB : 89|1@0+ (1,0) [0|1] "" IHU
 SG_ RestrntSysLampReq : 75|2@0+ (1,0) [0|3] "" IHU
 SG_ RestrntSysLampReq_UB : 90|1@0+ (1,0) [0|1] "" IHU
 SG_ RestrntSysMsgReq : 73|2@0+ (1,0) [0|3] "" IHU
 SG_ RestrntSysMsgReq_UB : 91|1@0+ (1,0) [0|1] "" IHU
 SG_ SeatHeatgLvlStsRowSecLe : 183|2@0+ (1,0) [0|3] "" IHU
 SG_ SeatHeatgLvlStsRowSecLe_UB : 191|1@0+ (1,0) [0|1] "" IHU
 SG_ SeatHeatgLvlStsRowSecRi : 181|2@0+ (1,0) [0|3] "" IHU
 SG_ SeatHeatgLvlStsRowSecRi_UB : 190|1@0+ (1,0) [0|1] "" IHU
 SG_ SeatHeatgLvlStsRowThrdLe : 367|2@0+ (1,0) [0|3] "" IHU
 SG_ SeatHeatgLvlStsRowThrdLe_UB : 375|1@0+ (1,0) [0|1] "" IHU
 SG_ SeatHeatgLvlStsRowThrdRi : 365|2@0+ (1,0) [0|3] "" IHU
 SG_ SeatHeatgLvlStsRowThrdRi_UB : 374|1@0+ (1,0) [0|1] "" IHU
 SG_ SeatRowSecLeSwtSts_UB : 264|1@0+ (1,0) [0|1] "" IHU
 SG_ SeatRowSecLeSwtStsPassSeatSwtAdjmtOfSpplFctHozlSts : 327|2@0+ (1,0) [0|3] "" IHU
 SG_ SeatRowSecLeSwtStsPassSeatSwtAdjmtOfSpplFctVerSts : 325|2@0+ (1,0) [0|3] "" IHU
 SG_ SeatRowSecLeSwtStsPassSeatSwtHdrstHozlSts : 323|2@0+ (1,0) [0|3] "" IHU
 SG_ SeatRowSecLeSwtStsPassSeatSwtHdrstVertSts : 321|2@0+ (1,0) [0|3] "" IHU
 SG_ SeatRowSecLeSwtStsPassSeatSwtHeiFrntSts : 335|2@0+ (1,0) [0|3] "" IHU
 SG_ SeatRowSecLeSwtStsPassSeatSwtHeiSts : 333|2@0+ (1,0) [0|3] "" IHU
 SG_ SeatRowSecLeSwtStsPassSeatSwtInclSts : 331|2@0+ (1,0) [0|3] "" IHU
 SG_ SeatRowSecLeSwtStsPassSeatSwtSelnOfSpplFctStsSts : 329|2@0+ (1,0) [0|3] "" IHU
 SG_ SeatRowSecLeSwtStsPassSeatSwtSldSts : 343|2@0+ (1,0) [0|3] "" IHU
 SG_ SeatRowSecRiSwtSts_UB : 355|1@0+ (1,0) [0|1] "" IHU
 SG_ SeatRowSecRiSwtStsPassSeatSwtAdjmtOfSpplFctHozlSts : 341|2@0+ (1,0) [0|3] "" IHU
 SG_ SeatRowSecRiSwtStsPassSeatSwtAdjmtOfSpplFctVerSts : 339|2@0+ (1,0) [0|3] "" IHU
 SG_ SeatRowSecRiSwtStsPassSeatSwtHdrstHozlSts : 337|2@0+ (1,0) [0|3] "" IHU
 SG_ SeatRowSecRiSwtStsPassSeatSwtHdrstVertSts : 351|2@0+ (1,0) [0|3] "" IHU
 SG_ SeatRowSecRiSwtStsPassSeatSwtHeiFrntSts : 349|2@0+ (1,0) [0|3] "" IHU
 SG_ SeatRowSecRiSwtStsPassSeatSwtHeiSts : 347|2@0+ (1,0) [0|3] "" IHU
 SG_ SeatRowSecRiSwtStsPassSeatSwtInclSts : 345|2@0+ (1,0) [0|3] "" IHU
 SG_ SeatRowSecRiSwtStsPassSeatSwtSelnOfSpplFctStsSts : 359|2@0+ (1,0) [0|3] "" IHU
 SG_ SeatRowSecRiSwtStsPassSeatSwtSldSts : 357|2@0+ (1,0) [0|3] "" IHU
 SG_ SeatRowThrdRiFoldRaiseWarn : 18|1@0+ (1,0) [0|1] "" IHU
 SG_ SeatRowThrdRiFoldRaiseWarn_UB : 124|1@0+ (1,0) [0|1] "" IHU
 SG_ SeatRowThrdRiFoldSts_UB : 383|1@0+ (1,0) [0|1] "" IHU
 SG_ SeatRowThrdRiFoldStsSeatFoldRaiseFlt : 368|1@0+ (1,0) [0|1] "" IHU
 SG_ SeatRowThrdRiFoldStsSeatFoldRaiseMovmt : 371|3@0+ (1,0) [0|7] "" IHU
 SG_ SeatVentnLvlStsRowSecLe : 179|2@0+ (1,0) [0|3] "" IHU
 SG_ SeatVentnLvlStsRowSecLe_UB : 189|1@0+ (1,0) [0|1] "" IHU
 SG_ SeatVentnLvlStsRowSecRi : 177|2@0+ (1,0) [0|3] "" IHU
 SG_ SeatVentnLvlStsRowSecRi_UB : 188|1@0+ (1,0) [0|1] "" IHU
 SG_ SeatVentnLvlStsRowThrdLe : 363|2@0+ (1,0) [0|3] "" IHU
 SG_ SeatVentnLvlStsRowThrdLe_UB : 373|1@0+ (1,0) [0|1] "" IHU
 SG_ SeatVentnLvlStsRowThrdRi : 361|2@0+ (1,0) [0|3] "" IHU
 SG_ SeatVentnLvlStsRowThrdRi_UB : 372|1@0+ (1,0) [0|1] "" IHU
 SG_ SecRowLeHeatgAutoSts : 382|2@0+ (1,0) [0|3] "" IHU
 SG_ SecRowLeHeatgAutoSts_UB : 380|1@0+ (1,0) [0|1] "" IHU
 SG_ SecRowLeVentnAutoSts : 389|2@0+ (1,0) [0|3] "" IHU
 SG_ SecRowLeVentnAutoSts_UB : 387|1@0+ (1,0) [0|1] "" IHU
 SG_ SecRowRiHeatgAutoSts : 391|2@0+ (1,0) [0|3] "" IHU
 SG_ SecRowRiHeatgAutoSts_UB : 376|1@0+ (1,0) [0|1] "" IHU
 SG_ SecRowRiVentnAutoSts : 379|2@0+ (1,0) [0|3] "" IHU
 SG_ SecRowRiVentnAutoSts_UB : 377|1@0+ (1,0) [0|1] "" IHU
 SG_ SnowFlg : 159|1@0+ (1,0) [0|1] "" IHU
 SG_ SnowFlg_UB : 144|1@0+ (1,0) [0|1] "" IHU
 SG_ SteerServoSts : 76|1@0+ (1,0) [0|1] "" IHU
 SG_ SteerServoSts_UB : 92|1@0+ (1,0) [0|1] "" IHU
 SG_ TCSTNowSts : 175|8@0+ (1.0,-50.0) [-50.0|205.0] "degC" Vector__XXX
 SG_ TCSTNowSts_UB : 162|1@0+ (1,0) [0|1] "" Vector__XXX
 SG_ ThrdRowLeHeatgAutoSts : 386|2@0+ (1,0) [0|3] "" IHU
 SG_ ThrdRowLeHeatgAutoSts_UB : 384|1@0+ (1,0) [0|1] "" IHU
 SG_ ThrdRowRiHeatgAutoSts : 399|2@0+ (1,0) [0|3] "" IHU
 SG_ ThrdRowRiHeatgAutoSts_UB : 397|1@0+ (1,0) [0|1] "" IHU
 SG_ TopPosHmiFeedBack : 186|3@0+ (1,0) [0|7] "" IHU
 SG_ TopPosHmiFeedBack_UB : 187|1@0+ (1,0) [0|1] "" IHU
 SG_ TopPosHmiFeedBack2 : 199|7@0+ (1.0,0.0) [0.0|101.0] "%" IHU
 SG_ TopPosHmiFeedBack2_UB : 192|1@0+ (1,0) [0|1] "" IHU
 SG_ TrOpenerSts : 207|4@0+ (1,0) [0|15] "" IHU
 SG_ TrOpenerSts_UB : 203|1@0+ (1,0) [0|1] "" IHU
 SG_ TrOpenPosn : 87|7@0+ (1.0,0.0) [0.0|101.0] "%" IHU
 SG_ TrOpenPosn_UB : 80|1@0+ (1,0) [0|1] "" IHU
 SG_ VehActvMsgToDrvr : 95|2@0+ (1,0) [0|3] "" IHU
 SG_ VehActvMsgToDrvr_UB : 93|1@0+ (1,0) [0|1] "" IHU
 SG_ VehEgyCoornDataReq : 161|1@0+ (1,0) [0|1] "" IHU
 SG_ VehEgyCoornDataReq_UB : 160|1@0+ (1,0) [0|1] "" IHU

BO_ 369 ZCUDZCUCANFD2Fr03 : 64 ZCUD
 SG_ AcEgyDistbn : 7|10@0+ (20.0,0.0) [0.0|20460.0] "W" IHU
 SG_ AcEgyDistbn_UB : 323|1@0+ (1,0) [0|1] "" IHU
 SG_ AudWarn : 11|1@0+ (1,0) [0|1] "" IHU
 SG_ AudWarn_UB : 381|1@0+ (1,0) [0|1] "" IHU
 SG_ AutoShowModPrpsnEna : 31|1@0+ (1,0) [0|1] "" IHU
 SG_ AutoShowModPrpsnEna_UB : 380|1@0+ (1,0) [0|1] "" IHU
 SG_ BltLockStAtPassMid_UB : 52|1@0+ (1,0) [0|1] "" IHU
 SG_ BltLockStAtPassMidBltLockEquid : 55|1@0+ (1,0) [0|1] "" IHU
 SG_ BltLockStAtPassMidBltLockSt1 : 54|1@0+ (1,0) [0|1] "" IHU
 SG_ BltLockStAtPassMidBltLockSts : 53|1@0+ (1,0) [0|1] "" IHU
 SG_ BltLockStAtRowFrthLe_UB : 48|1@0+ (1,0) [0|1] "" IHU
 SG_ BltLockStAtRowFrthLeBltLockEquid : 51|1@0+ (1,0) [0|1] "" IHU
 SG_ BltLockStAtRowFrthLeBltLockSt1 : 50|1@0+ (1,0) [0|1] "" IHU
 SG_ BltLockStAtRowFrthLeBltLockSts : 49|1@0+ (1,0) [0|1] "" IHU
 SG_ BltLockStAtRowFrthMid_UB : 60|1@0+ (1,0) [0|1] "" IHU
 SG_ BltLockStAtRowFrthMidBltLockEquid : 63|1@0+ (1,0) [0|1] "" IHU
 SG_ BltLockStAtRowFrthMidBltLockSt1 : 62|1@0+ (1,0) [0|1] "" IHU
 SG_ BltLockStAtRowFrthMidBltLockSts : 61|1@0+ (1,0) [0|1] "" IHU
 SG_ BltLockStAtRowFrthRi_UB : 56|1@0+ (1,0) [0|1] "" IHU
 SG_ BltLockStAtRowFrthRiBltLockEquid : 59|1@0+ (1,0) [0|1] "" IHU
 SG_ BltLockStAtRowFrthRiBltLockSt1 : 58|1@0+ (1,0) [0|1] "" IHU
 SG_ BltLockStAtRowFrthRiBltLockSts : 57|1@0+ (1,0) [0|1] "" IHU
 SG_ BltLockStAtRowThrdMid_UB : 414|1@0+ (1,0) [0|1] "" IHU
 SG_ BltLockStAtRowThrdMidBltLockEquid : 407|1@0+ (1,0) [0|1] "" IHU
 SG_ BltLockStAtRowThrdMidBltLockSt1 : 406|1@0+ (1,0) [0|1] "" IHU
 SG_ BltLockStAtRowThrdMidBltLockSts : 405|1@0+ (1,0) [0|1] "" IHU
 SG_ BtnLockStsAndKeyId_UB : 115|1@0+ (1,0) [0|1] "" ETC
 SG_ BtnLockStsAndKeyIdBtnSts : 164|1@0+ (1,0) [0|1] "" ETC
 SG_ BtnLockStsAndKeyIdKeyId : 163|4@0+ (1,0) [0|15] "" ETC
 SG_ BtnUnlckStsAndKeyId_UB : 117|1@0+ (1,0) [0|1] "" ETC
 SG_ BtnUnlckStsAndKeyIdBtnSts : 446|1@0+ (1,0) [0|1] "" ETC
 SG_ BtnUnlckStsAndKeyIdKeyId : 445|4@0+ (1,0) [0|15] "" ETC
 SG_ CchForFuEco_UB : 379|1@0+ (1,0) [0|1] "" IHU
 SG_ CchForFuEcoBarForFuEco : 247|10@0+ (0.1,0.0) [0.0|102.30000000000001] "%" IHU
 SG_ CchForFuEcoGrdForFuEco : 249|10@0+ (0.1,0.0) [0.0|102.30000000000001] "Unitless" IHU
 SG_ CchForPwrEco_UB : 378|1@0+ (1,0) [0|1] "" IHU
 SG_ CchForPwrEcoBarForPwrEco : 271|10@0+ (0.1,0.0) [0.0|102.30000000000001] "%" IHU
 SG_ CchForPwrEcoGrdForPwrEco : 273|10@0+ (0.1,0.0) [0.0|102.30000000000001] "Unitless" IHU
 SG_ CmptmtFrntWindDewT : 10|11@0+ (0.1,-40.0) [-40.0|164.70000000000002] "degC" IHU,ZCUP
 SG_ CmptmtFrntWindDewT_UB : 400|1@0+ (1,0) [0|1] "" IHU,ZCUP
 SG_ CoolgLoadGroup_UB : 166|1@0+ (1,0) [0|1] "" IHU,ZCUP
 SG_ CoolgLoadGroupCoolgLimd : 159|1@0+ (1,0) [0|1] "" IHU,ZCUP
 SG_ CoolgLoadGroupCoolgLoad2 : 158|7@0+ (1.0,0.0) [0.0|100.0] "%" IHU,ZCUP
 SG_ DigKeyApproachReq_UB : 322|1@0+ (1,0) [0|1] "" ETC,IHU
 SG_ DigKeyApproachReqDigKeyApproaReq : 239|4@0+ (1,0) [0|15] "" ETC,IHU
 SG_ DigKeyApproachReqKeyId3 : 235|4@0+ (1,0) [0|15] "" ETC,IHU
 SG_ DoorHandleSensorSts : 47|8@0+ (1.0,0.0) [0.0|255.0] "Unitless" IHU,ZCUP
 SG_ DoorHandleSensorSts_UB : 401|1@0+ (1,0) [0|1] "" IHU,ZCUP
 SG_ DoorLockUnlockCmdNFC_UB : 447|1@0+ (1,0) [0|1] "" ETC
 SG_ DoorLockUnlockCmdNFCKeyId3 : 439|4@0+ (1,0) [0|15] "" ETC
 SG_ DoorLockUnlockCmdNFCKeyPrsntSts1 : 426|2@0+ (1,0) [0|3] "" ETC
 SG_ DoorLockUnlockCmdNFCPsdNotPsd : 424|1@0+ (1,0) [0|1] "" ETC
 SG_ DoorPassHndlCmd : 30|2@0+ (1,0) [0|3] "" IHU,ZCUP
 SG_ DoorPassHndlCmd_UB : 408|1@0+ (1,0) [0|1] "" IHU,ZCUP
 SG_ DoorRiReHndlCmd : 28|2@0+ (1,0) [0|3] "" IHU,ZCUP
 SG_ DoorRiReHndlCmd_UB : 409|1@0+ (1,0) [0|1] "" IHU,ZCUP
 SG_ DrvrSeatPosPerc_UB : 410|1@0+ (1,0) [0|1] "" IHU
 SG_ DrvrSeatPosPercSeatPosFrntHeiPerc : 295|10@0+ (0.1,0.0) [0.0|100.0] "%" IHU
 SG_ DrvrSeatPosPercSeatPosFrntHeiQF : 301|2@0+ (1,0) [0|3] "" IHU
 SG_ DrvrSeatPosPercSeatPosHeiPerc : 297|10@0+ (0.1,0.0) [0.0|100.0] "%" IHU
 SG_ DrvrSeatPosPercSeatPosHeiQF : 299|2@0+ (1,0) [0|3] "" IHU
 SG_ DrvrSeatPosPercSeatPosSldPerc : 319|10@0+ (0.1,0.0) [0.0|100.0] "%" IHU
 SG_ DrvrSeatPosPercSeatPosSldQF : 325|2@0+ (1,0) [0|3] "" IHU
 SG_ DstToEmptyIndcdDstToEmpty1 : 26|11@0+ (1.0,0.0) [0.0|2047.0] "KiloMtr" Vector__XXX
 SG_ DstToEmptyIndcdDstToEmpty1_UB : 411|1@0+ (1,0) [0|1] "" Vector__XXX
 SG_ EgyAvgCnsDstSg : 74|1@0+ (1,0) [0|1] "" IHU
 SG_ EgyAvgCnsDstSg_UB : 412|1@0+ (1,0) [0|1] "" IHU
 SG_ FuCnsAvgIndcdFuCnsIndcdVal1 : 71|13@0+ (0.1,0.0) [0.0|819.1] "LPer100kilometer_1" Vector__XXX
 SG_ FuCnsAvgIndcdFuCnsIndcdVal1_UB : 415|1@0+ (1,0) [0|1] "" Vector__XXX
 SG_ FuCnsAvgIndcdFuCnsIndcdVal2 : 95|13@0+ (0.1,0.0) [0.0|819.1] "LPer100kilometer_1" Vector__XXX
 SG_ FuCnsAvgIndcdFuCnsIndcdVal2_UB : 416|1@0+ (1,0) [0|1] "" Vector__XXX
 SG_ FuCnsAvgIndcdFuCnsIndcdVal3 : 140|13@0+ (0.1,0.0) [0.0|819.1] "LPer100kilometer_1" Vector__XXX
 SG_ FuCnsAvgIndcdFuCnsIndcdVal3_UB : 417|1@0+ (1,0) [0|1] "" Vector__XXX
 SG_ FuCnsIndcdVal1 : 471|13@0+ (0.1,0.0) [0.0|819.1] "LPer100kilometer_1" Vector__XXX
 SG_ FuCnsIndcdVal1_UB : 418|1@0+ (1,0) [0|1] "" Vector__XXX
 SG_ GearIndcnRec_UB : 419|1@0+ (1,0) [0|1] "" IHU
 SG_ GearIndcnRecGearIndcn : 335|4@0+ (1,0) [0|15] "" IHU
 SG_ GearIndcnRecGearShiftIndcn : 321|2@0+ (1,0) [0|3] "" IHU
 SG_ GearIndcnRecGearTarIndcn : 331|4@0+ (1,0) [0|15] "" IHU
 SG_ HvConvPwrAct : 73|10@0+ (20.0,0.0) [0.0|20460.0] "W" IHU
 SG_ HvConvPwrAct_UB : 420|1@0+ (1,0) [0|1] "" IHU
 SG_ ImobRemMgrChk_UB : 421|1@0+ (1,0) [0|1] "" IHU
 SG_ ImobRemMgrChkImobDataRemMgrChk0 : 343|8@0+ (1.0,0.0) [0.0|255.0] "Unitless" IHU
 SG_ ImobRemMgrChkImobDataRemMgrChk1 : 351|8@0+ (1.0,0.0) [0.0|255.0] "Unitless" IHU
 SG_ ImobRemMgrChkImobDataRemMgrChk2 : 359|8@0+ (1.0,0.0) [0.0|255.0] "Unitless" IHU
 SG_ ImobRemMgrChkImobDataRemMgrChk3 : 367|8@0+ (1.0,0.0) [0.0|255.0] "Unitless" IHU
 SG_ ImobRemMgrChkImobDataRemMgrChk4 : 375|8@0+ (1.0,0.0) [0.0|255.0] "Unitless" IHU
 SG_ ImobRemMgrChkSts : 383|2@0+ (1,0) [0|3] "" IHU
 SG_ ImobVehRemMgrSts1_UB : 422|1@0+ (1,0) [0|1] "" IHU
 SG_ ImobVehRemMgrSts1ImobVehRemMgrSts : 377|2@0+ (1,0) [0|3] "" IHU
 SG_ ImobVehRemMgrSts1SpdLimRemMgrSts : 391|8@0+ (1.0,0.0) [0.0|255.0] "Unitless" IHU
 SG_ LnchModIndcnMsg : 395|4@0+ (1,0) [0|15] "" IHU
 SG_ LnchModIndcnMsg_UB : 413|1@0+ (1,0) [0|1] "" IHU
 SG_ LockgFbAcoustReq : 474|3@0+ (1,0) [0|7] "" ETC
 SG_ LockgFbAcoustReq_UB : 456|1@0+ (1,0) [0|1] "" ETC
 SG_ LockgFbToExtLi : 404|3@0+ (1,0) [0|7] "" ETC
 SG_ LockgFbToExtLi_UB : 441|1@0+ (1,0) [0|1] "" ETC
 SG_ MobDevVentReq : 167|1@0+ (1,0) [0|1] "" IHU,ZCUP
 SG_ MobDevVentReq_UB : 423|1@0+ (1,0) [0|1] "" IHU,ZCUP
 SG_ OpenClsCmftReq_UB : 440|1@0+ (1,0) [0|1] "" ETC,IHU
 SG_ OpenClsCmftReqOpenClsCmftReq : 399|2@0+ (1,0) [0|3] "" ETC,IHU
 SG_ OpenClsCmftReqOpenClsCmftTrigSrc : 397|2@0+ (1,0) [0|3] "" ETC,IHU
 SG_ PassMidSeatSts : 459|2@0+ (1,0) [0|3] "" IHU
 SG_ PassMidSeatSts_UB : 457|1@0+ (1,0) [0|1] "" IHU
 SG_ PwrCnsAvgIndcdPwrCns1 : 97|11@0+ (0.1,-102.3) [-102.3|102.30000000000003] "Unitless" IHU
 SG_ PwrCnsAvgIndcdPwrCns1_UB : 427|1@0+ (1,0) [0|1] "" IHU
 SG_ PwrCnsAvgIndcdPwrCns2 : 135|11@0+ (0.1,-102.3) [-102.3|102.30000000000003] "Unitless" IHU
 SG_ PwrCnsAvgIndcdPwrCns2_UB : 428|1@0+ (1,0) [0|1] "" IHU
 SG_ PwrCnsAvgIndcdPwrCns3 : 114|11@0+ (0.1,-102.3) [-102.3|102.30000000000003] "Unitless" IHU
 SG_ PwrCnsAvgIndcdPwrCns3_UB : 429|1@0+ (1,0) [0|1] "" IHU
 SG_ PwrCnsIndcdPwrCnsIn1 : 215|11@0+ (0.1,-100.0) [-100.0|100.0] "KwHper100Kilometer_1" IHU
 SG_ PwrCnsIndcdPwrCnsIn1_UB : 430|1@0+ (1,0) [0|1] "" IHU
 SG_ RainDetected : 98|1@0+ (1,0) [0|1] "" IHU,ZCUP
 SG_ RainDetected_UB : 431|1@0+ (1,0) [0|1] "" IHU,ZCUP
 SG_ RemAllowStrt : 118|1@0+ (1,0) [0|1] "" IHU
 SG_ RemAllowStrt_UB : 432|1@0+ (1,0) [0|1] "" IHU
 SG_ SeatOccptAtRowFrthLe : 455|2@0+ (1,0) [0|3] "" IHU
 SG_ SeatOccptAtRowFrthLe_UB : 463|1@0+ (1,0) [0|1] "" IHU
 SG_ SeatOccptAtRowFrthMid : 453|2@0+ (1,0) [0|3] "" IHU
 SG_ SeatOccptAtRowFrthMid_UB : 462|1@0+ (1,0) [0|1] "" IHU
 SG_ SeatOccptAtRowFrthRi : 451|2@0+ (1,0) [0|3] "" IHU
 SG_ SeatOccptAtRowFrthRi_UB : 461|1@0+ (1,0) [0|1] "" IHU
 SG_ SeatOccptAtRowThrdMid : 449|2@0+ (1,0) [0|3] "" IHU
 SG_ SeatOccptAtRowThrdMid_UB : 460|1@0+ (1,0) [0|1] "" IHU
 SG_ ShortDropWinLeReDoor2 : 169|2@0+ (1,0) [0|3] "" ZCUP
 SG_ ShortDropWinLeReDoor2_UB : 116|1@0+ (1,0) [0|1] "" ZCUP
 SG_ ShortDropWinPassDoor2 : 183|2@0+ (1,0) [0|3] "" ZCUP
 SG_ ShortDropWinPassDoor2_UB : 181|1@0+ (1,0) [0|1] "" ZCUP
 SG_ ShortDropWinRiReDoor2 : 180|2@0+ (1,0) [0|3] "" ZCUP
 SG_ ShortDropWinRiReDoor2_UB : 178|1@0+ (1,0) [0|1] "" ZCUP
 SG_ SunCurtPosnSts : 175|5@0+ (1,0) [0|31] "" IHU,ZCUP
 SG_ SunCurtPosnSts_UB : 170|1@0+ (1,0) [0|1] "" IHU,ZCUP
 SG_ TankFlapLockgCmd : 220|3@0+ (1,0) [0|7] "" IHU,ZCUP
 SG_ TankFlapLockgCmd_UB : 433|1@0+ (1,0) [0|1] "" IHU,ZCUP
 SG_ ThmEgyDistbn : 217|10@0+ (20.0,0.0) [0.0|20460.0] "W" IHU
 SG_ ThmEgyDistbn_UB : 434|1@0+ (1,0) [0|1] "" IHU
 SG_ TotDrvPwrAct : 199|11@0+ (1.0,-1000.0) [-1000.0|1047.0] "kW" IHU
 SG_ TotDrvPwrAct_UB : 165|1@0+ (1,0) [0|1] "" IHU
 SG_ TrHndlOutdOpenSts : 13|1@0+ (1,0) [0|1] "" ETC
 SG_ TrHndlOutdOpenSts_UB : 12|1@0+ (1,0) [0|1] "" ETC
 SG_ TrsmFltIndcn : 204|5@0+ (1,0) [0|31] "" IHU
 SG_ TrsmFltIndcn_UB : 435|1@0+ (1,0) [0|1] "" IHU

BO_ 666 ZCUDZCUCANFD2Fr04 : 64 ZCUD
 SG_ AcHiSideP : 7|13@0+ (1.0,0.0) [0.0|5000.0] "KiloPa" Vector__XXX
 SG_ AcHiSideP_UB : 488|1@0+ (1,0) [0|1] "" Vector__XXX
 SG_ ActvnOfWshrFrntSafe : 10|2@0+ (1,0) [0|3] "" IHU,ZCUP
 SG_ ActvnOfWshrFrntSafe_UB : 482|1@0+ (1,0) [0|1] "" IHU,ZCUP
 SG_ ActvOfHorn : 8|1@0+ (1,0) [0|1] "" IHU
 SG_ ActvOfHorn_UB : 487|1@0+ (1,0) [0|1] "" IHU
 SG_ AirPtcPCBTempActl : 23|8@0+ (1.0,-40.0) [-40.0|215.0] "degC" IHU
 SG_ AirPtcPCBTempActl_UB : 486|1@0+ (1,0) [0|1] "" IHU
 SG_ AirTFromHeatgEstimd : 31|13@0- (0.1,0.0) [-256.0|255.9] "degC" IHU,ZCUP
 SG_ AirTFromHeatgEstimd_UB : 485|1@0+ (1,0) [0|1] "" IHU,ZCUP
 SG_ BattCpEstimdRaw : 47|7@0+ (1.0,0.0) [0.0|100.0] "Ah" IHU
 SG_ BattCpEstimdRaw_UB : 484|1@0+ (1,0) [0|1] "" IHU
 SG_ ChrgEquipIDc : 438|15@0+ (0.1,-1638.0) [-1638.0|1638.7000000000003] "A" IHU
 SG_ ChrgEquipIDc_UB : 439|1@0+ (1,0) [0|1] "" IHU
 SG_ CmprReqCmprSpdReq : 391|8@0+ (50.0,0.0) [0.0|12700.0] "rpm" IHU
 SG_ CmprReqCmprSpdReq_UB : 393|1@0+ (1,0) [0|1] "" IHU
 SG_ CooltFlowInCmptmtCirc : 57|10@0+ (0.05,0.0) [0.0|51.150000000000006] "L / min" IHU,ZCUP
 SG_ CooltFlowInCmptmtCirc_UB : 473|1@0+ (1,0) [0|1] "" IHU,ZCUP
 SG_ CooltHeatrTIntk : 79|8@0+ (1.0,-40.0) [-40.0|210.0] "degC" IHU,ZCUP
 SG_ CooltHeatrTIntk_UB : 474|1@0+ (1,0) [0|1] "" IHU,ZCUP
 SG_ CooltHeatrTOutl : 87|8@0+ (1.0,-40.0) [-40.0|210.0] "degC" IHU,ZCUP
 SG_ CooltHeatrTOutl_UB : 475|1@0+ (1,0) [0|1] "" IHU,ZCUP
 SG_ DCDCConsDyvCyc : 95|32@0+ (0.1,0.0) [0.0|800000.0] "Kilojoule_1" IHU
 SG_ DCDCConsDyvCyc_UB : 476|1@0+ (1,0) [0|1] "" IHU
 SG_ DChrgStrtEngRes : 149|4@0+ (1,0) [0|15] "" IHU
 SG_ DChrgStrtEngRes_UB : 477|1@0+ (1,0) [0|1] "" IHU
 SG_ DispIdlChrgPwr : 143|10@0+ (0.5,0.0) [0.0|511.0] "kW" Vector__XXX
 SG_ DispIdlChrgPwr_UB : 480|1@0+ (1,0) [0|1] "" Vector__XXX
 SG_ EcmRoilgCntr : 455|8@0+ (1.0,0.0) [0.0|255.0] "Unitless" IHU,ZCUP
 SG_ EcmRoilgCntr_UB : 491|1@0+ (1,0) [0|1] "" IHU,ZCUP
 SG_ EldtPmpPwrCns : 407|12@0+ (1.0,0.0) [0.0|4095.0] "W" IHU
 SG_ EldtPmpPwrCns_UB : 472|1@0+ (1,0) [0|1] "" IHU
 SG_ EngCooltInhbFlow : 479|1@0+ (1,0) [0|1] "" IHU,ZCUP
 SG_ EngCooltInhbFlow_UB : 478|1@0+ (1,0) [0|1] "" IHU,ZCUP
 SG_ EngCooltLoFlowReq : 469|6@0+ (0.5,0.0) [0.0|20.0] "L / min" IHU,ZCUP
 SG_ EngCooltLoFlowReq_UB : 492|1@0+ (1,0) [0|1] "" IHU,ZCUP
 SG_ EngCooltPmpPwrCns : 127|11@0+ (1.0,0.0) [0.0|2047.0] "W" IHU
 SG_ EngCooltPmpPwrCns_UB : 381|1@0+ (1,0) [0|1] "" IHU
 SG_ FanPwrCns : 55|11@0+ (1.0,0.0) [0.0|2047.0] "W" IHU
 SG_ FanPwrCns_UB : 129|1@0+ (1,0) [0|1] "" IHU
 SG_ FuelConsDrvCyc : 145|10@0+ (0.1,0.0) [0.0|102.30000000000001] "Litre" Vector__XXX
 SG_ FuelConsDrvCyc_UB : 483|1@0+ (1,0) [0|1] "" Vector__XXX
 SG_ HvahFltIndcnReq : 505|1@0+ (1,0) [0|1] "" IHU,ZCUP
 SG_ HvahFltIndcnReq_UB : 504|1@0+ (1,0) [0|1] "" IHU,ZCUP
 SG_ HvEgyCnsAllwdForClima : 167|8@0+ (50.0,0.0) [0.0|12750.0] "Wh" IHU,ZCUP
 SG_ HvEgyCnsAllwdForClima_UB : 379|1@0+ (1,0) [0|1] "" IHU,ZCUP
 SG_ HvEgyLoadFctReq : 495|1@0+ (1,0) [0|1] "" IHU
 SG_ HvEgyLoadFctReq_UB : 494|1@0+ (1,0) [0|1] "" IHU
 SG_ HvPwrAvlForClimaEstimd : 375|10@0+ (20.0,0.0) [0.0|20460.0] "W" IHU,ZCUP
 SG_ HvPwrAvlForClimaEstimd_UB : 380|1@0+ (1,0) [0|1] "" IHU,ZCUP
 SG_ HvPwrEgyPrio : 60|3@0+ (1,0) [0|7] "" IHU,ZCUP
 SG_ HvPwrEgyPrio_UB : 40|1@0+ (1,0) [0|1] "" IHU,ZCUP
 SG_ HvWtrHeatrPwrCnsAllwd : 463|8@0+ (40.0,0.0) [0.0|10200.0] "W" IHU
 SG_ HvWtrHeatrPwrCnsAllwd_UB : 128|1@0+ (1,0) [0|1] "" IHU
 SG_ HwRowRearLeLegRstHeiMotCtrl : 207|2@0+ (1,0) [0|3] "" IHU
 SG_ HwRowRearLeLegRstHeiMotCtrl_UB : 215|1@0+ (1,0) [0|1] "" IHU
 SG_ HwRowRearLeLegRstLenMotCtrl : 205|2@0+ (1,0) [0|3] "" IHU
 SG_ HwRowRearLeLegRstLenMotCtrl_UB : 214|1@0+ (1,0) [0|1] "" IHU
 SG_ HwRowRearRiLegRstHeiMotCtrl : 203|2@0+ (1,0) [0|3] "" IHU
 SG_ HwRowRearRiLegRstHeiMotCtrl_UB : 213|1@0+ (1,0) [0|1] "" IHU
 SG_ HwRowRearRiLegRstLenMotCtrl : 201|2@0+ (1,0) [0|3] "" IHU
 SG_ HwRowRearRiLegRstLenMotCtrl_UB : 212|1@0+ (1,0) [0|1] "" IHU
 SG_ HwRowSecLeInclMotCtrl : 223|2@0+ (1,0) [0|3] "" IHU
 SG_ HwRowSecLeInclMotCtrl_UB : 211|1@0+ (1,0) [0|1] "" IHU
 SG_ HwRowSecLeSldMotCtrl : 221|2@0+ (1,0) [0|3] "" IHU
 SG_ HwRowSecLeSldMotCtrl_UB : 210|1@0+ (1,0) [0|1] "" IHU
 SG_ HwRowSecRiInclMotCtrl : 219|2@0+ (1,0) [0|3] "" IHU
 SG_ HwRowSecRiInclMotCtrl_UB : 209|1@0+ (1,0) [0|1] "" IHU
 SG_ HwRowSecRiSldMotCtrl : 217|2@0+ (1,0) [0|3] "" IHU
 SG_ HwRowSecRiSldMotCtrl_UB : 208|1@0+ (1,0) [0|1] "" IHU
 SG_ HwRowThrdLeInclMotCtrl : 231|2@0+ (1,0) [0|3] "" IHU
 SG_ HwRowThrdLeInclMotCtrl_UB : 229|1@0+ (1,0) [0|1] "" IHU
 SG_ HwRowThrdRiInclMotCtrl : 227|2@0+ (1,0) [0|3] "" IHU
 SG_ HwRowThrdRiInclMotCtrl_UB : 228|1@0+ (1,0) [0|1] "" IHU
 SG_ MirrActvBtn : 225|1@0+ (1,0) [0|1] "" IHU
 SG_ MirrActvBtn_UB : 224|1@0+ (1,0) [0|1] "" IHU
 SG_ MirrCmdAtDrvr_UB : 232|1@0+ (1,0) [0|1] "" IHU
 SG_ MirrCmdAtDrvrMirrDwnCmd : 239|2@0+ (1,0) [0|3] "" IHU
 SG_ MirrCmdAtDrvrMirrFoldCmd : 237|2@0+ (1,0) [0|3] "" IHU
 SG_ MirrCmdAtDrvrMirrPosAdjCmd : 235|3@0+ (1,0) [0|7] "" IHU
 SG_ MirrDefrstAtDrvSts : 377|1@0+ (1,0) [0|1] "" IHU
 SG_ MirrDefrstAtDrvSts_UB : 376|1@0+ (1,0) [0|1] "" IHU
 SG_ MirrDirReq : 259|3@0+ (1,0) [0|7] "" IHU
 SG_ MirrDirReq_UB : 256|1@0+ (1,0) [0|1] "" IHU
 SG_ MirrPosnAdjFromSetTarPosnDrvr_UB : 263|1@0+ (1,0) [0|1] "" IHU
 SG_ MirrPosnAdjFromSetTarPosnDrvrMirrPosnAdjCldLeRi : 247|8@0+ (1.0,0.0) [0.0|180.0] "Deg" IHU
 SG_ MirrPosnAdjFromSetTarPosnDrvrMirrPosnAdjCldUpDwn : 255|8@0+ (1.0,0.0) [0.0|180.0] "Deg" IHU
 SG_ MirrSelnReq : 261|2@0+ (1,0) [0|3] "" IHU
 SG_ MirrSelnReq_UB : 262|1@0+ (1,0) [0|1] "" IHU
 SG_ MotGenDrvCyc : 175|32@0+ (0.1,0.0) [0.0|800000.0] "Kilojoule_1" IHU
 SG_ MotGenDrvCyc_UB : 378|1@0+ (1,0) [0|1] "" IHU
 SG_ RngExtd : 503|14@0+ (0.1,0.0) [0.0|1638.3000000000002] "km" IHU
 SG_ RngExtd_UB : 489|1@0+ (1,0) [0|1] "" IHU
 SG_ RoadSlopeInst : 335|15@0+ (0.01,-100.0) [-100.0|100.0] "%" Vector__XXX
 SG_ RoadSlopeInst_UB : 336|1@0+ (1,0) [0|1] "" Vector__XXX
 SG_ TOCCooltFlowReq : 353|10@0+ (0.02,0.0) [0.0|20.46] "L / min" Vector__XXX
 SG_ TOCCooltFlowReq_UB : 356|1@0+ (1,0) [0|1] "" Vector__XXX
 SG_ TrlrModPrpsnSts : 471|2@0+ (1,0) [0|3] "" IHU
 SG_ TrlrModPrpsnSts_UB : 493|1@0+ (1,0) [0|1] "" IHU

BO_ 336 ZCUDZCUCANFD2Fr05 : 64 ZCUD
 SG_ ActvnOfHzrd : 7|8@0+ (1.0,0.0) [0.0|100.0] "%" IHU
 SG_ ActvnOfHzrd_UB : 25|1@0+ (1,0) [0|1] "" IHU
 SG_ BookChrgnTarValFb : 63|10@0+ (0.1,0.0) [0.0|100.0] "%" IHU
 SG_ BookChrgnTarValFb_UB : 69|1@0+ (1,0) [0|1] "" IHU
 SG_ ChrgLidRearLockCmd : 23|3@0+ (1,0) [0|7] "" IHU,ZCUP
 SG_ ChrgLidRearLockCmd_UB : 36|1@0+ (1,0) [0|1] "" IHU,ZCUP
 SG_ ChrgnOrDisChrgnStsFb : 55|5@0+ (1,0) [0|31] "" IHU
 SG_ ChrgnOrDisChrgnStsFb_UB : 24|1@0+ (1,0) [0|1] "" IHU
 SG_ DispOfPrpsnMod : 11|4@0+ (1,0) [0|15] "" IHU
 SG_ DispOfPrpsnMod_UB : 35|1@0+ (1,0) [0|1] "" IHU
 SG_ DstEstimdToEmptyForDrvgElec : 79|10@0+ (1.0,0.0) [0.0|1023.0] "KiloMtr" IHU
 SG_ DstEstimdToEmptyForDrvgElec_UB : 14|1@0+ (1,0) [0|1] "" IHU
 SG_ DstFromDestinationFb : 31|3@0+ (1,0) [0|7] "" IHU
 SG_ DstFromDestinationFb_UB : 33|1@0+ (1,0) [0|1] "" IHU
 SG_ DstToEmptyIndcdDstToEmpty2 : 82|11@0+ (1.0,0.0) [0.0|2047.0] "KiloMtr" IHU
 SG_ DstToEmptyIndcdDstToEmpty2_UB : 83|1@0+ (1,0) [0|1] "" IHU
 SG_ KeyLostWarnIndcn : 13|2@0+ (1,0) [0|3] "" IHU
 SG_ KeyLostWarnIndcn_UB : 32|1@0+ (1,0) [0|1] "" IHU
 SG_ KeyRmnIndcn : 17|1@0+ (1,0) [0|1] "" IHU
 SG_ KeyRmnIndcn_UB : 47|1@0+ (1,0) [0|1] "" IHU
 SG_ LockgFbAudioReq : 28|3@0+ (1,0) [0|7] "" IHU
 SG_ LockgFbAudioReq_UB : 46|1@0+ (1,0) [0|1] "" IHU
 SG_ MemBtnPsd_UB : 84|1@0+ (1,0) [0|1] "" IHU
 SG_ MemBtnPsdMemBtn1 : 43|1@0+ (1,0) [0|1] "" IHU
 SG_ MemBtnPsdMemBtn2 : 42|1@0+ (1,0) [0|1] "" IHU
 SG_ MemBtnPsdMemBtn3 : 41|1@0+ (1,0) [0|1] "" IHU
 SG_ MemBtnPsdMemButM : 40|1@0+ (1,0) [0|1] "" IHU
 SG_ RowSecLeSeatInAutMovmt : 20|1@0+ (1,0) [0|1] "" IHU
 SG_ RowSecLeSeatInAutMovmt_UB : 19|1@0+ (1,0) [0|1] "" IHU
 SG_ RowSecRiSeatInAutMovmt : 18|1@0+ (1,0) [0|1] "" IHU
 SG_ RowSecRiSeatInAutMovmt_UB : 15|1@0+ (1,0) [0|1] "" IHU
 SG_ SecRowSeatHeatgActlPwrCnsLe : 103|8@0+ (1.0,0.0) [0.0|255.0] "Unitless" ZCUP
 SG_ SecRowSeatHeatgActlPwrCnsLe_UB : 231|1@0+ (1,0) [0|1] "" ZCUP
 SG_ SecRowSeatHeatgActlPwrCnsRi : 111|8@0+ (1.0,0.0) [0.0|255.0] "Unitless" ZCUP
 SG_ SecRowSeatHeatgActlPwrCnsRi_UB : 230|1@0+ (1,0) [0|1] "" ZCUP
 SG_ SecRowSeatHeatgDesPwrCnsLe : 135|8@0+ (1.0,0.0) [0.0|255.0] "Unitless" ZCUP
 SG_ SecRowSeatHeatgDesPwrCnsLe_UB : 229|1@0+ (1,0) [0|1] "" ZCUP
 SG_ SecRowSeatHeatgDesPwrCnsRi : 143|8@0+ (1.0,0.0) [0.0|255.0] "Unitless" ZCUP
 SG_ SecRowSeatHeatgDesPwrCnsRi_UB : 228|1@0+ (1,0) [0|1] "" ZCUP
 SG_ SecRowSeatVentnActlPwrCnsLe : 119|8@0+ (1.0,0.0) [0.0|255.0] "Unitless" ZCUP
 SG_ SecRowSeatVentnActlPwrCnsLe_UB : 227|1@0+ (1,0) [0|1] "" ZCUP
 SG_ SecRowSeatVentnActlPwrCnsRi : 127|8@0+ (1.0,0.0) [0.0|255.0] "Unitless" ZCUP
 SG_ SecRowSeatVentnActlPwrCnsRi_UB : 226|1@0+ (1,0) [0|1] "" ZCUP
 SG_ SecRowSeatVentnDesPwrCnsLe : 151|8@0+ (1.0,0.0) [0.0|255.0] "Unitless" ZCUP
 SG_ SecRowSeatVentnDesPwrCnsLe_UB : 225|1@0+ (1,0) [0|1] "" ZCUP
 SG_ SecRowSeatVentnDesPwrCnsRi : 159|8@0+ (1.0,0.0) [0.0|255.0] "Unitless" ZCUP
 SG_ SecRowSeatVentnDesPwrCnsRi_UB : 224|1@0+ (1,0) [0|1] "" ZCUP
 SG_ ThrdRowSeatHeatgActlPwrCnsLe : 167|8@0+ (1.0,0.0) [0.0|255.0] "Unitless" ZCUP
 SG_ ThrdRowSeatHeatgActlPwrCnsLe_UB : 239|1@0+ (1,0) [0|1] "" ZCUP
 SG_ ThrdRowSeatHeatgActlPwrCnsRi : 175|8@0+ (1.0,0.0) [0.0|255.0] "Unitless" ZCUP
 SG_ ThrdRowSeatHeatgActlPwrCnsRi_UB : 238|1@0+ (1,0) [0|1] "" ZCUP
 SG_ ThrdRowSeatHeatgDesPwrCnsLe : 183|8@0+ (1.0,0.0) [0.0|255.0] "Unitless" ZCUP
 SG_ ThrdRowSeatHeatgDesPwrCnsLe_UB : 237|1@0+ (1,0) [0|1] "" ZCUP
 SG_ ThrdRowSeatHeatgDesPwrCnsRi : 191|8@0+ (1.0,0.0) [0.0|255.0] "Unitless" ZCUP
 SG_ ThrdRowSeatHeatgDesPwrCnsRi_UB : 236|1@0+ (1,0) [0|1] "" ZCUP
 SG_ ThrdRowSeatVentnActlPwrCnsLe : 199|8@0+ (1.0,0.0) [0.0|255.0] "Unitless" ZCUP
 SG_ ThrdRowSeatVentnActlPwrCnsLe_UB : 235|1@0+ (1,0) [0|1] "" ZCUP
 SG_ ThrdRowSeatVentnActlPwrCnsRi : 207|8@0+ (1.0,0.0) [0.0|255.0] "Unitless" ZCUP
 SG_ ThrdRowSeatVentnActlPwrCnsRi_UB : 234|1@0+ (1,0) [0|1] "" ZCUP
 SG_ ThrdRowSeatVentnDesPwrCnsLe : 215|8@0+ (1.0,0.0) [0.0|255.0] "Unitless" ZCUP
 SG_ ThrdRowSeatVentnDesPwrCnsLe_UB : 233|1@0+ (1,0) [0|1] "" ZCUP
 SG_ ThrdRowSeatVentnDesPwrCnsRi : 223|8@0+ (1.0,0.0) [0.0|255.0] "Unitless" ZCUP
 SG_ ThrdRowSeatVentnDesPwrCnsRi_UB : 232|1@0+ (1,0) [0|1] "" ZCUP
 SG_ WadeProtnIndcn : 39|3@0+ (1,0) [0|7] "" Vector__XXX
 SG_ WadeProtnIndcn_UB : 44|1@0+ (1,0) [0|1] "" Vector__XXX

CM_ SG_ 293 DrvModReqForChampnMod "Drive Mode for champion mode";
CM_ SG_ 293 MusicInfoSeg11SegFftLiShow1 "amplitude-frequency results of 1st segment";
CM_ SG_ 293 MusicInfoSeg11SegFftLiShow10 "amplitude-frequency results of 11st segment";
CM_ SG_ 293 MusicInfoSeg11SegFftLiShow11 "amplitude-frequency results of 11st segment";
CM_ SG_ 293 MusicInfoSeg11SegFftLiShow12 "amplitude-frequency results of 12st segment";
CM_ SG_ 293 MusicInfoSeg11SegFftLiShow13 "amplitude-frequency results of 13st segment";
CM_ SG_ 293 MusicInfoSeg11SegFftLiShow14 "amplitude-frequency results of 14st segment";
CM_ SG_ 293 MusicInfoSeg11SegFftLiShow2 "amplitude-frequency results of 2st segment";
CM_ SG_ 293 MusicInfoSeg11SegFftLiShow3 "amplitude-frequency results of 3st segment";
CM_ SG_ 293 MusicInfoSeg11SegFftLiShow4 "amplitude-frequency results of 4st segment";
CM_ SG_ 293 MusicInfoSeg11SegFftLiShow5 "amplitude-frequency results of 5st segment";
CM_ SG_ 293 MusicInfoSeg11SegFftLiShow6 "amplitude-frequency results of 6st segment";
CM_ SG_ 293 MusicInfoSeg11SegFftLiShow7 "amplitude-frequency results of 7st segment";
CM_ SG_ 293 MusicInfoSeg11SegFftLiShow8 "amplitude-frequency results of 8st segment";
CM_ SG_ 293 MusicInfoSeg11SegFftLiShow9 "amplitude-frequency results of 9st segment";
CM_ SG_ 293 MusicInfoSeg11TimeFlagMessage "data transmission time stamp";
CM_ SG_ 293 MusicInfoSeg11TimeFlagMusicplay "current music playback time stamp";
CM_ SG_ 293 MusicInfoSeg12SegFftLiShow15 "amplitude-frequency results of 15th segment";
CM_ SG_ 293 MusicInfoSeg12SegFftLiShow16 "amplitude-frequency results of 16th segment";
CM_ SG_ 293 MusicInfoSeg12SegFftLiShow17 "amplitude-frequency results of 17th segment";
CM_ SG_ 293 MusicInfoSeg12SegFftLiShow18 "amplitude-frequency results of 18th segment";
CM_ SG_ 293 MusicInfoSeg12SegFftLiShow19 "amplitude-frequency results of 19th segment";
CM_ SG_ 293 MusicInfoSeg12SegFftLiShow20 "amplitude-frequency results of 20th segment";
CM_ SG_ 293 MusicInfoSeg12SegFftLiShow21 "amplitude-frequency results of 21th segment";
CM_ SG_ 293 MusicInfoSeg12SegFftLiShow22 "amplitude-frequency results of 22th segment";
CM_ SG_ 293 MusicInfoSeg12SegFftLiShow23 "amplitude-frequency results of 23th segment";
CM_ SG_ 293 MusicInfoSeg12SegFftLiShow24 "amplitude-frequency results of 24th segment";
CM_ SG_ 293 MusicInfoSeg12SegFftLiShow25 "amplitude-frequency results of 25th segment";
CM_ SG_ 293 MusicInfoSeg12SegFftLiShow26 "amplitude-frequency results of 26th segment";
CM_ SG_ 293 MusicInfoSeg12SegFftLiShow27 "amplitude-frequency results of 27th segment";
CM_ SG_ 293 MusicInfoSeg12SegFftLiShow28 "amplitude-frequency results of 28th segment";
CM_ SG_ 293 MusicInfoSeg12TimeFlagMessage "data transmission time stamp";
CM_ SG_ 293 MusicInfoSeg12TimeFlagMusicplay "current music playback time stamp";
CM_ SG_ 293 MusicInfoSeg13DownSamplingAmplitude "The down-sampling amplitude data ";
CM_ SG_ 293 MusicInfoSeg13MaxFFT100ms3kAmplitude "The amplitude of max amplitude-frequency point among
100Hz-2.65kHz";
CM_ SG_ 293 MusicInfoSeg13MaxFFT100ms3kFrequency "The frequency of max amplitude-frequency point among
100Hz-2.65kHz";
CM_ SG_ 293 MusicInfoSeg13SegFftLiShow29 "amplitude-frequency results of 29th segment";
CM_ SG_ 293 MusicInfoSeg13SegFftLiShow30 "amplitude-frequency results of 30th segment";
CM_ SG_ 293 MusicInfoSeg13SegFftLiShow31 "amplitude-frequency results of 31th segment";
CM_ SG_ 293 MusicInfoSeg13StateFlagMusicPlay "Music Play Flag";
CM_ SG_ 293 MusicInfoSeg13StateFlagNewMusic "New Music Flag";
CM_ SG_ 293 MusicInfoSeg13TimeFlagMessage "data transmission time stamp";
CM_ SG_ 293 MusicInfoSeg13TimeFlagMusicplay "current music playback time stamp";
CM_ SG_ 293 MusicInfoSeg21SegFftLiShow1 "amplitude-frequency results of 1th segment";
CM_ SG_ 293 MusicInfoSeg21SegFftLiShow10 "amplitude-frequency results of 10th segment";
CM_ SG_ 293 MusicInfoSeg21SegFftLiShow11 "amplitude-frequency results of 11th segment";
CM_ SG_ 293 MusicInfoSeg21SegFftLiShow12 "amplitude-frequency results of 12th segment";
CM_ SG_ 293 MusicInfoSeg21SegFftLiShow13 "amplitude-frequency results of 13th segment";
CM_ SG_ 293 MusicInfoSeg21SegFftLiShow14 "amplitude-frequency results of 14th segment";
CM_ SG_ 293 MusicInfoSeg21SegFftLiShow2 "amplitude-frequency results of 2th segment";
CM_ SG_ 293 MusicInfoSeg21SegFftLiShow3 "amplitude-frequency results of 3th segment";
CM_ SG_ 293 MusicInfoSeg21SegFftLiShow4 "amplitude-frequency results of 4th segment";
CM_ SG_ 293 MusicInfoSeg21SegFftLiShow5 "amplitude-frequency results of 5th segment";
CM_ SG_ 293 MusicInfoSeg21SegFftLiShow6 "amplitude-frequency results of 6th segment";
CM_ SG_ 293 MusicInfoSeg21SegFftLiShow7 "amplitude-frequency results of 7th segment";
CM_ SG_ 293 MusicInfoSeg21SegFftLiShow8 "amplitude-frequency results of 8th segment";
CM_ SG_ 293 MusicInfoSeg21SegFftLiShow9 "amplitude-frequency results of 9th segment";
CM_ SG_ 293 MusicInfoSeg21TimeFlagMessage "data transmission time stamp";
CM_ SG_ 293 MusicInfoSeg21TimeFlagMusicplay "current music playback time stamp";
CM_ SG_ 293 MusicInfoSeg22SegFftLiShow15 "amplitude-frequency results of 15th segment";
CM_ SG_ 293 MusicInfoSeg22SegFftLiShow16 "amplitude-frequency results of 16th segment";
CM_ SG_ 293 MusicInfoSeg22SegFftLiShow17 "amplitude-frequency results of 17th segment";
CM_ SG_ 293 MusicInfoSeg22SegFftLiShow18 "amplitude-frequency results of 18th segment";
CM_ SG_ 293 MusicInfoSeg22SegFftLiShow19 "amplitude-frequency results of 19th segment";
CM_ SG_ 293 MusicInfoSeg22SegFftLiShow20 "amplitude-frequency results of 20th segment";
CM_ SG_ 293 MusicInfoSeg22SegFftLiShow21 "amplitude-frequency results of 21th segment";
CM_ SG_ 293 MusicInfoSeg22SegFftLiShow22 "amplitude-frequency results of 22th segment";
CM_ SG_ 293 MusicInfoSeg22SegFftLiShow23 "amplitude-frequency results of 23th segment";
CM_ SG_ 293 MusicInfoSeg22SegFftLiShow24 "amplitude-frequency results of 24th segment";
CM_ SG_ 293 MusicInfoSeg22SegFftLiShow25 "amplitude-frequency results of 25th segment";
CM_ SG_ 293 MusicInfoSeg22SegFftLiShow26 "amplitude-frequency results of 26th segment";
CM_ SG_ 293 MusicInfoSeg22SegFftLiShow27 "amplitude-frequency results of 27th segment";
CM_ SG_ 293 MusicInfoSeg22SegFftLiShow28 "amplitude-frequency results of 28th segment";
CM_ SG_ 293 MusicInfoSeg22TimeFlagMessage "data transmission time stamp";
CM_ SG_ 293 MusicInfoSeg22TimeFlagMusicplay "current music playback time stamp";
CM_ SG_ 293 MusicInfoSeg23DownSamplingAmplitude "The down-sampling amplitude data ";
CM_ SG_ 293 MusicInfoSeg23MaxFFT100ms3kAmplitude "The amplitude of max amplitude-frequency point among
100Hz-2.65kHz";
CM_ SG_ 293 MusicInfoSeg23MaxFFT100ms3kFrequency "The frequency of max amplitude-frequency point among
100Hz-2.65kHz";
CM_ SG_ 293 MusicInfoSeg23SegFftLiShow29 "amplitude-frequency results of 29th segment";
CM_ SG_ 293 MusicInfoSeg23SegFftLiShow30 "amplitude-frequency results of 30th segment";
CM_ SG_ 293 MusicInfoSeg23SegFftLiShow31 "amplitude-frequency results of 31th segment";
CM_ SG_ 293 MusicInfoSeg23StateFlagMusicPlay "Music Play Flag";
CM_ SG_ 293 MusicInfoSeg23StateFlagNewMusic "New Music Flag";
CM_ SG_ 293 MusicInfoSeg23TimeFlagMessage "data transmission time stamp";
CM_ SG_ 293 MusicInfoSeg23TimeFlagMusicplay "current music playback time stamp";
CM_ SG_ 293 PrkgLiShowSwt "Parking light show switch";
CM_ SG_ 1288 WakeUpReasonsforDHU "WakeUpReasons";
CM_ SG_ 1377 ZCUDMdevelpsignalgroupReqFunctiondevpsignalgroup1 "develop signal group";
CM_ SG_ 1377 ZCUDMdevelpsignalgroupReqFunctiondevpsignalgroup2 "develop signal group";
CM_ SG_ 1377 ZCUDMdevelpsignalgroupReqFunctiondevpsignalgroup3 "develop signal group";
CM_ SG_ 1377 ZCUDMdevelpsignalgroupReqFunctiondevpsignalgroup4 "develop signal group";
CM_ SG_ 1377 ZCUDMdevelpsignalgroupReqFunctiondevpsignalgroup5 "develop signal group";
CM_ SG_ 1377 ZCUDMdevelpsignalgroupReqFunctiondevpsignalgroup6 "develop signal group";
CM_ SG_ 1377 ZCUDMdevelpsignalgroupReqFunctiondevpsignalgroup7 "develop signal group";
CM_ SG_ 1377 ZCUDMdevelpsignalgroupReqFunctiondevpsignalgroup8 "develop signal group";
CM_ SG_ 1377 ZCUPdevelpsignalgroupReqFunctiondevpsignalgroup1 "develop signal group";
CM_ SG_ 1377 ZCUPdevelpsignalgroupReqFunctiondevpsignalgroup2 "develop signal group";
CM_ SG_ 1377 ZCUPdevelpsignalgroupReqFunctiondevpsignalgroup3 "develop signal group";
CM_ SG_ 1377 ZCUPdevelpsignalgroupReqFunctiondevpsignalgroup4 "develop signal group";
CM_ SG_ 1377 ZCUPdevelpsignalgroupReqFunctiondevpsignalgroup5 "develop signal group";
CM_ SG_ 1377 ZCUPdevelpsignalgroupReqFunctiondevpsignalgroup6 "develop signal group";
CM_ SG_ 1377 ZCUPdevelpsignalgroupReqFunctiondevpsignalgroup7 "develop signal group";
CM_ SG_ 1377 ZCUPdevelpsignalgroupReqFunctiondevpsignalgroup8 "develop signal group";
CM_ SG_ 1378 ZCUDMdevelpsignalgroupRespFunctiondevpsignalgroup1 "develop signal group";
CM_ SG_ 1378 ZCUDMdevelpsignalgroupRespFunctiondevpsignalgroup2 "develop signal group";
CM_ SG_ 1378 ZCUDMdevelpsignalgroupRespFunctiondevpsignalgroup3 "develop signal group";
CM_ SG_ 1378 ZCUDMdevelpsignalgroupRespFunctiondevpsignalgroup4 "develop signal group";
CM_ SG_ 1378 ZCUDMdevelpsignalgroupRespFunctiondevpsignalgroup5 "develop signal group";
CM_ SG_ 1378 ZCUDMdevelpsignalgroupRespFunctiondevpsignalgroup6 "develop signal group";
CM_ SG_ 1378 ZCUDMdevelpsignalgroupRespFunctiondevpsignalgroup7 "develop signal group";
CM_ SG_ 1378 ZCUDMdevelpsignalgroupRespFunctiondevpsignalgroup8 "develop signal group";
CM_ SG_ 1378 ZCUDMDevpFrameForDebugFunctiondevpsignalgroup1 "develop signal group";
CM_ SG_ 1378 ZCUDMDevpFrameForDebugFunctiondevpsignalgroup2 "develop signal group";
CM_ SG_ 1378 ZCUDMDevpFrameForDebugFunctiondevpsignalgroup3 "develop signal group";
CM_ SG_ 1378 ZCUDMDevpFrameForDebugFunctiondevpsignalgroup4 "develop signal group";
CM_ SG_ 1378 ZCUDMDevpFrameForDebugFunctiondevpsignalgroup5 "develop signal group";
CM_ SG_ 1378 ZCUDMDevpFrameForDebugFunctiondevpsignalgroup6 "develop signal group";
CM_ SG_ 1378 ZCUDMDevpFrameForDebugFunctiondevpsignalgroup7 "develop signal group";
CM_ SG_ 1378 ZCUDMDevpFrameForDebugFunctiondevpsignalgroup8 "develop signal group";
CM_ SG_ 1169 AccrpedlStsChks " It should provide acceleration pedal Status signal ( AccrpedlSts ) to predict whether the accelerator pedal  has fault or not.1-Fault; 0-NoFault";
CM_ SG_ 1169 AccrpedlStsCntr " It should provide acceleration pedal Status signal ( AccrpedlSts ) to predict whether the accelerator pedal  has fault or not.1-Fault; 0-NoFault";
CM_ SG_ 1169 AccrpedlStsFltSts " It should provide acceleration pedal Status signal ( AccrpedlSts ) to predict whether the accelerator pedal  has fault or not.1-Fault; 0-NoFault";
CM_ SG_ 1169 ActnOfLedHiBeam "Activate LED High Beam.";
CM_ SG_ 1169 ActnOfLedLoBeamActnOfLedLoBeam "Activation of Low Beam function to HCM";
CM_ SG_ 1169 ActnOfLedLoBeamChks "Low Beam Check Sum ASIL B";
CM_ SG_ 1169 ActnOfLedLoBeamCntr "Low Beam Counter ASIL B";
CM_ SG_ 1169 ActvnOfWiprRe "Activate rear wiper";
CM_ SG_ 1169 AsySftyStandStillReq "Let the relative subsystem to know, the vehicle is stopped by AEB, and now the vehicle need to keep standstill.";
CM_ SG_ 1169 BattChrgnBalDurgDrvgRaw "Accumulated battery charging during driving";
CM_ SG_ 1169 BattCircOpenU "Battery open circuit voltage";
CM_ SG_ 1169 BattCpEstimdAtTNomRaw "Estimated Battery Capacity At Nominal Temperature";
CM_ SG_ 1169 BattCpRel "Relative battery capacity";
CM_ SG_ 1169 BattCycChrgCntrRaw "Cumulative Battery Charge When Engine Running Normalized to capacity at nominal temperature";
CM_ SG_ 1169 BattCycDchaCntrDurgConvceRaw "Cumulative Battery Discharge During Engine Off Normalized to capacity at nominal temperature";
CM_ SG_ 1169 BattCycDchaCntrDurgDrvgRaw "Cumulative Battery Discharge During Engine On Normalized to capacity at nominal temperature";
CM_ SG_ 1169 BattCycDchaCntrDurgQuiscPhaRaw "Cumulative Battery Discharge During Ignition Off Normalized to capacity at nominal temperature";
CM_ SG_ 1169 BattIQuiscAvgRaw "Presents the average level of quiescent current in BattSnsrSt";
CM_ SG_ 1169 BattIQuiscFildLongRaw "Average Quiescent Current During Sleep Quick Indication 10h";
CM_ SG_ 1169 BattIQuiscFildShoRaw "Average Quiescent Current During Sleep Quick Indication 20 Minuters";
CM_ SG_ 1169 BattIRaw "Battery Current From BMS";
CM_ SG_ 1169 BattRAtTNomRaw "Internal resistance of battery at Nominal Temperature";
CM_ SG_ 1169 BattRRaw "Internal resistance of battery with consideration to Present Temperature and SOC";
CM_ SG_ 1169 BattSnsrCalcnNotVldRaw "BMS consistency fault";
CM_ SG_ 1169 BattSnsrHwFltRaw "Battery sensor HW fault";
CM_ SG_ 1169 BattTiInSrvRaw "Battery time in service from BMS";
CM_ SG_ 1169 BattTRaw "Battery temperature from BMS";
CM_ SG_ 1169 CarModDispdWdDispd "Enum that specifies what CarMode is to be displayed in DIM.";
CM_ SG_ 1169 CarModDynoReq "Initiates message display for entering CarMode Dyno";
CM_ SG_ 1169 CEMdevelpsignalgroupVMM1Functiondevpsignalgroup1 "VMM internal signal group1.";
CM_ SG_ 1169 CEMdevelpsignalgroupVMM1Functiondevpsignalgroup2 "VMM internal signal group2.";
CM_ SG_ 1169 CEMdevelpsignalgroupVMM1Functiondevpsignalgroup3 "VMM internal signal group3.";
CM_ SG_ 1169 CEMdevelpsignalgroupVMM1Functiondevpsignalgroup4 "VMM internal signal group4.";
CM_ SG_ 1169 CEMdevelpsignalgroupVMM1Functiondevpsignalgroup5 "VMM internal signal group5.";
CM_ SG_ 1169 CEMdevelpsignalgroupVMM1Functiondevpsignalgroup6 "VMM internal signal group6.";
CM_ SG_ 1169 CEMdevelpsignalgroupVMM1Functiondevpsignalgroup7 "VMM internal signal group7.";
CM_ SG_ 1169 CEMdevelpsignalgroupVMM1Functiondevpsignalgroup8 "VMM internal signal group8.";
CM_ SG_ 1169 CmptFrntWindDewT "compartment front windscreen dew temperature.";
CM_ SG_ 1169 CmptFrntWindT "compartment front windsreeen temperature signal.";
CM_ SG_ 1169 CnvnAllwd "Intelligent charging allow status. 0 = NOK Or 1 = OK";
CM_ SG_ 1169 CnvnReq "Intelligent charge request";
CM_ SG_ 1169 DoorDrvrSwtIntrLockgReq "DoorDrvrSwtIntrLockgReq - Driver Door Interior Locking Switch Request
Central locking-unlocking request from driver door interior central locking-unlocking switch
Idle - No Request
Unlck - Unlock request
Lock - Lock request";
CM_ SG_ 1169 DrvrSteerWhlHldGroupDrvrSteerWhlHld "Hands on steering wheel information. Signal indicating whether the driver has his hands on the steering wheel or not.";
CM_ SG_ 1169 DrvrSteerWhlHldGroupDrvrSteerWhlHldQly "Hands on steering wheel information. Confidence value for the DrvrSteerWhlHld estimation calculation, specifically indicating the confidence for the hands off state.";
CM_ SG_ 1169 EgyLvlElecDrvInfo "Trigger for displaying energy level related messages.";
CM_ SG_ 1169 EgyMeas "Accumulated battery energy";
CM_ SG_ 1169 EgyMeasIntlIntl1 "Intervals 0 to 50mA";
CM_ SG_ 1169 EgyMeasIntlIntl2 "Intervals 50 to 1500mA";
CM_ SG_ 1169 EgyMeasIntlIntl3 "Intervals 1500 to 4000mA";
CM_ SG_ 1169 EgyMeasIntlIntl4 "Intervals larger than 4000mA";
CM_ SG_ 1169 EgyMeasSec "Secondary accumulated battery energy";
CM_ SG_ 1169 ElecMot2ModReq "Generator motor operation mode request
1: standby
2: torque control
3: speed control
4: UDC control
5: Speed Control Dead Zone";
CM_ SG_ 306 ActnOfDaytiRunngLampPass "Activate DRL Lamp of passenger side";
CM_ SG_ 306 ActnOfDynRePos "different value for dynamic rear position";
CM_ SG_ 306 ActnOfFrntFogLampPass "Activate front fog Lamp of passenger side";
CM_ SG_ 306 ActnOfFrntPosnLampPass "Activate front position Lamp of passenger side";
CM_ SG_ 306 ActnOfHiBeamPass "Activate high beam of passenger side";
CM_ SG_ 306 ActnOfLoBeamPassChks "Low Beam Check Sum ASIL B";
CM_ SG_ 306 ActnOfLoBeamPassCntr "Low Beam Counter ASIL B";
CM_ SG_ 306 ActnOfLoBeamPassOnOff "Activation of Low Beam function";
CM_ SG_ 306 ActnOfReFogLampDrv "Activate rear fog Lamp of driver side";
CM_ SG_ 306 ActnOfRePosnLampPass "Activate rear position Lamp of passenger side";
CM_ SG_ 306 ActnOfReRegPlateLamp "Requests activation of registration plate light.";
CM_ SG_ 306 ActnOfRvsgLampPass "Activate reverse Lamp of passenger side";
CM_ SG_ 306 ActvnOfApproach "to indicate approach light function for dynmaic animation";
CM_ SG_ 306 ActvnOfCarLoctr "to indicate car locate function for dynmaic animation";
CM_ SG_ 306 ActvnOfGoodByeLi "Activation Request for Goodbye Light";
CM_ SG_ 306 ActvnOfHndlDoorLi1HndlDoorLiDrvr "ActvnOfHndlDoorLi1";
CM_ SG_ 306 ActvnOfHndlDoorLi1HndlDoorLiDrvrRe "ActvnOfHndlDoorLi1";
CM_ SG_ 306 ActvnOfHndlDoorLi1HndlDoorLiPass "ActvnOfHndlDoorLi1";
CM_ SG_ 306 ActvnOfHndlDoorLi1HndlDoorLiPassRe "ActvnOfHndlDoorLi1";
CM_ SG_ 306 ActvnOfHomeSafe "Activate home safe light function";
CM_ SG_ 306 ActvnOfLiForComity "signal send to actuator to activate dynamic light for comity function";
CM_ SG_ 306 ActvnOfLiForSpkr "signal send to actuator to activate dynamic light for showing speaker";
CM_ SG_ 306 ActvnOfLiForWait "signal send to actuator to activate dynamic light for wait function";
CM_ SG_ 306 ActvnOfPudLi "Activate Puddle light";
CM_ SG_ 306 ActvnOfWaitMode "Activate signal to actuator to implement wait mode animation";
CM_ SG_ 306 BattFltStsPrimBattFltStsPrm "Battery fault status primary.";
CM_ SG_ 306 BattFltStsPrimChks "CheckSum";
CM_ SG_ 306 BattFltStsPrimCntr "Counter";
CM_ SG_ 306 CarCfgInfoToWPC "inform WPC the car configuration informtion";
CM_ SG_ 306 ChdLockLeftSts "CdhLockgProtnStsAtLeRe - Child Lock Protection Status at Left Rear Door
Indicates child lock status for left rear door
On - Child lock is active
Off - Child lock is not active";
CM_ SG_ 306 ChdLockRightStsToHmi "Signal sent from the Driver door module to the Driver information module to inform if the electric child lock  is ative or not for right rear door";
CM_ SG_ 306 ChdPrtnLeftStsToHmi "Signal sent from the Driver door module to the Driver information module to inform if the electric child lock  is ative or not";
CM_ SG_ 306 ChrgLidCombLockCmd "Combo Charge Lid Lock Command";
CM_ SG_ 306 ChrgnLtgSts "AC/DC charging status";
CM_ SG_ 306 CinhDrvrReSts "Driver rear Door cinch Status";
CM_ SG_ 306 CinhDrvrReSwt "Driver rear door Cinch switch status";
CM_ SG_ 306 CinhDrvrSts "CinhDrvrSts - Driver Door cinch Status";
CM_ SG_ 306 CinhDrvrSwt "driver door Cinch switch status";
CM_ SG_ 306 DchaChrgnTarValFb "Feedback the corresponding signal when receivesDchaChrgnTarVal from TCAM";
CM_ SG_ 306 DigKeyPasEntryDiSts "Digital Key Passive entry disable status";
CM_ SG_ 306 DlyClsActv "Signal informing Remote Control that a Delay Close of the tailgate is active";
CM_ SG_ 306 DoorLeReHndlCmd "Shall send command to operate the deployable left rear door handle according to
DoorLeReHndlCmd
- Idle
- Deploy
- Retract";
CM_ SG_ 306 DrvrGearLvrInfoIndcn "Indicates to the driver why the gear lever information is change.";
CM_ SG_ 306 DrvrGearLvrLockIndcn "Indicates to the driver why the gear lever is locked. Valid for Shift By Wire systems. Does not include error information.";
CM_ SG_ 306 DstTrvldFromSftyBkp "Saved backupvalue";
CM_ SG_ 306 DstTrvldVldFromSftyBkp "Indication if the transmitted backupvalue is valid or not";
CM_ SG_ 306 EmgyBrkLiIndcrTurn "Activation of both rear direction indicators for EBL.";
CM_ SG_ 306 ErsStrtApplSts "The primary state of the ERS application";
CM_ SG_ 306 ExtrLiShowStoreStsFrntLe "ExtrLiShowStoreStsFrntLe";
CM_ SG_ 306 ExtrLiShowStoreStsFrntRi "ExtrLiShowStoreStsFrntRi";
CM_ SG_ 306 GlvBoxRelsReq "GlvBoxRelsReq - Glove Box Release Request

Request signal to release (open) glove box. Actuated by motor in glove box, hardwired to CEM.

On - Glove box release requested
Off - Glove box release not requested";
CM_ SG_ 306 HvBattHeatgReq "Hv Battery request level for heating.";
CM_ SG_ 306 HvCooltWtrHeatrWtrTInIntk "Coolant temperature in heater inlet.";
CM_ SG_ 306 HvCooltWtrHeatrWtrTInOutl "Coolant temperature in heater outlet.";
CM_ SG_ 306 IndcrNoSeq "to indicate if HWL or DI with sequence";
CM_ SG_ 306 KeyEnaStsKey0 "KeyEnaSts is a record with status for each of the possible keys (0-11)
Each key can be either: 
Idle (not connected to the vehicle)
Disabled (connected to vehicle but all functionality disabled)
Enabled (Connected and OK for all functionality)
Limited (Connected and OK but with restrictions - restricted/limited key)";
CM_ SG_ 306 KeyEnaStsKey1 "KeyEnaSts is a record with status for each of the possible keys (0-11)
Each key can be either: 
Idle (not connected to the vehicle)
Disabled (connected to vehicle but all functionality disabled)
Enabled (Connected and OK for all functionality)
Limited (Connected and OK but with restrictions - restricted/limited key)";
CM_ SG_ 306 KeyEnaStsKey10 "KeyEnaSts is a record with status for each of the possible keys (0-11)
Each key can be either: 
Idle (not connected to the vehicle)
Disabled (connected to vehicle but all functionality disabled)
Enabled (Connected and OK for all functionality)
Limited (Connected and OK but with restrictions - restricted/limited key)";
CM_ SG_ 306 KeyEnaStsKey11 "KeyEnaSts is a record with status for each of the possible keys (0-11)
Each key can be either: 
Idle (not connected to the vehicle)
Disabled (connected to vehicle but all functionality disabled)
Enabled (Connected and OK for all functionality)
Limited (Connected and OK but with restrictions - restricted/limited key)";
CM_ SG_ 306 KeyEnaStsKey2 "KeyEnaSts is a record with status for each of the possible keys (0-11)
Each key can be either: 
Idle (not connected to the vehicle)
Disabled (connected to vehicle but all functionality disabled)
Enabled (Connected and OK for all functionality)
Limited (Connected and OK but with restrictions - restricted/limited key)";
CM_ SG_ 306 KeyEnaStsKey3 "KeyEnaSts is a record with status for each of the possible keys (0-11)
Each key can be either: 
Idle (not connected to the vehicle)
Disabled (connected to vehicle but all functionality disabled)
Enabled (Connected and OK for all functionality)
Limited (Connected and OK but with restrictions - restricted/limited key)";
CM_ SG_ 306 KeyEnaStsKey4 "KeyEnaSts is a record with status for each of the possible keys (0-11)
Each key can be either: 
Idle (not connected to the vehicle)
Disabled (connected to vehicle but all functionality disabled)
Enabled (Connected and OK for all functionality)
Limited (Connected and OK but with restrictions - restricted/limited key)";
CM_ SG_ 306 KeyEnaStsKey5 "KeyEnaSts is a record with status for each of the possible keys (0-11)
Each key can be either: 
Idle (not connected to the vehicle)
Disabled (connected to vehicle but all functionality disabled)
Enabled (Connected and OK for all functionality)
Limited (Connected and OK but with restrictions - restricted/limited key)";
CM_ SG_ 306 KeyEnaStsKey6 "KeyEnaSts is a record with status for each of the possible keys (0-11)
Each key can be either: 
Idle (not connected to the vehicle)
Disabled (connected to vehicle but all functionality disabled)
Enabled (Connected and OK for all functionality)
Limited (Connected and OK but with restrictions - restricted/limited key)";
CM_ SG_ 306 KeyEnaStsKey7 "KeyEnaSts is a record with status for each of the possible keys (0-11)
Each key can be either: 
Idle (not connected to the vehicle)
Disabled (connected to vehicle but all functionality disabled)
Enabled (Connected and OK for all functionality)
Limited (Connected and OK but with restrictions - restricted/limited key)";
CM_ SG_ 306 KeyEnaStsKey8 "KeyEnaSts is a record with status for each of the possible keys (0-11)
Each key can be either: 
Idle (not connected to the vehicle)
Disabled (connected to vehicle but all functionality disabled)
Enabled (Connected and OK for all functionality)
Limited (Connected and OK but with restrictions - restricted/limited key)";
CM_ SG_ 306 KeyEnaStsKey9 "KeyEnaSts is a record with status for each of the possible keys (0-11)
Each key can be either: 
Idle (not connected to the vehicle)
Disabled (connected to vehicle but all functionality disabled)
Enabled (Connected and OK for all functionality)
Limited (Connected and OK but with restrictions - restricted/limited key)";
CM_ SG_ 306 KeyScanActv "Signal to inform about if a key search is in progress.
TRUE - Key search ongoing
FALSE - No key search";
CM_ SG_ 306 MirrDefrstAtPassCmd "Activation signal exterior rear view mirror electrical defroster passenger side.";
CM_ SG_ 306 MirrDwnStsAtDrvr "Reports the status of the mirror dipping mode. Driver side.";
CM_ SG_ 306 MirrPosnAdjFromSetTarPosnPassMirrPosnAdjCldLeRi "Passenger Mirror Position adjustment from Setting target postion Lef-Right.";
CM_ SG_ 306 MirrPosnAdjFromSetTarPosnPassMirrPosnAdjCldUpDwn "Passenger Mirror Position adjustment from Setting target postion Up-Down.";
CM_ SG_ 306 PedProtnMsgReqForFlt "Indication request for pedestrian protection faults.";
CM_ SG_ 306 PedProtnMsgReqForImpct "Text message request to inform about triggering of the pedestrian protection system.";
CM_ SG_ 306 PrpsnHvBattUsgOfChrgBlkd2 "Charge mode is blocked/unavailable";
CM_ SG_ 306 PrpsnHvBattUsgOfHldBlkd2 "Hold mode is blocked/unavailable";
CM_ SG_ 306 RegenAutLvlNotAvlMsg "Regeneration level Auto not avaliable indication";
CM_ SG_ 306 RestrntSysLampReq "Indication request for SRS faults.";
CM_ SG_ 306 RestrntSysMsgReq "Text message request for SRS faults.";
CM_ SG_ 306 SeatHeatgLvlStsRowSecLe "Seat heating level for second row left seat.";
CM_ SG_ 306 SeatHeatgLvlStsRowSecRi "Seat heating level for second row left seat.";
CM_ SG_ 306 SeatHeatgLvlStsRowThrdLe "Seat heating level for third row left seat.";
CM_ SG_ 306 SeatHeatgLvlStsRowThrdRi "Seat heating level for third row left seat.";
CM_ SG_ 306 SeatRowSecLeSwtStsPassSeatSwtAdjmtOfSpplFctHozlSts "Multifunction Horizontal Switch Status";
CM_ SG_ 306 SeatRowSecLeSwtStsPassSeatSwtAdjmtOfSpplFctVerSts "Multifunction Vertical Switch Status";
CM_ SG_ 306 SeatRowSecLeSwtStsPassSeatSwtHdrstHozlSts "Headrest Horizontal Switch Status";
CM_ SG_ 306 SeatRowSecLeSwtStsPassSeatSwtHdrstVertSts "Headrest Vertical Switch Status";
CM_ SG_ 306 SeatRowSecLeSwtStsPassSeatSwtHeiFrntSts "Tilt Switch Status";
CM_ SG_ 306 SeatRowSecLeSwtStsPassSeatSwtHeiSts "Height Switch Status";
CM_ SG_ 306 SeatRowSecLeSwtStsPassSeatSwtInclSts "Backrest Switch Status";
CM_ SG_ 306 SeatRowSecLeSwtStsPassSeatSwtSelnOfSpplFctStsSts "Multifunction Selector Switch Status";
CM_ SG_ 306 SeatRowSecLeSwtStsPassSeatSwtSldSts "Slide Switch Status";
CM_ SG_ 306 SeatRowSecRiSwtStsPassSeatSwtAdjmtOfSpplFctHozlSts "Multifunction Horizontal Switch Status";
CM_ SG_ 306 SeatRowSecRiSwtStsPassSeatSwtAdjmtOfSpplFctVerSts "Multifunction Vertical Switch Status";
CM_ SG_ 306 SeatRowSecRiSwtStsPassSeatSwtHdrstHozlSts "Headrest Horizontal Switch Status";
CM_ SG_ 306 SeatRowSecRiSwtStsPassSeatSwtHdrstVertSts "Headrest Vertical Switch Status";
CM_ SG_ 306 SeatRowSecRiSwtStsPassSeatSwtHeiFrntSts "Tilt Switch Status";
CM_ SG_ 306 SeatRowSecRiSwtStsPassSeatSwtHeiSts "Height Switch Status";
CM_ SG_ 306 SeatRowSecRiSwtStsPassSeatSwtInclSts "Backrest Switch Status";
CM_ SG_ 306 SeatRowSecRiSwtStsPassSeatSwtSelnOfSpplFctStsSts "Multifunction Selector Switch Status";
CM_ SG_ 306 SeatRowSecRiSwtStsPassSeatSwtSldSts "Slide Switch Status";
CM_ SG_ 306 SeatRowThrdRiFoldRaiseWarn "Warning signal for the Third Row Right Seat Fold or Raise";
CM_ SG_ 306 SeatRowThrdRiFoldStsSeatFoldRaiseFlt "Fault Status for the Third Row Right Seat Fold or Raise movement";
CM_ SG_ 306 SeatRowThrdRiFoldStsSeatFoldRaiseMovmt "Status for the Third Row Right Seat Fold or Raise movement";
CM_ SG_ 306 SeatVentnLvlStsRowSecLe "Seat ventilation level for second row left seat.";
CM_ SG_ 306 SeatVentnLvlStsRowSecRi "Seat ventilation level for second row right seat.";
CM_ SG_ 306 SeatVentnLvlStsRowThrdLe "Seat ventilation level for third row left seat.";
CM_ SG_ 306 SeatVentnLvlStsRowThrdRi "Seat ventilation level for third row right seat.";
CM_ SG_ 306 SecRowLeHeatgAutoSts "Automatic status feedback signal for seats heating of second row left.";
CM_ SG_ 306 SecRowLeVentnAutoSts "Automatic status feedback signal for seats ventilation of second row left.";
CM_ SG_ 306 SecRowRiHeatgAutoSts "Automatic status feedback signal for seats heating of second row right.";
CM_ SG_ 306 SecRowRiVentnAutoSts "Automatic status feedback signal for seats ventilation of second row right.";
CM_ SG_ 306 SnowFlg "0x0=off
0x1=on";
CM_ SG_ 306 SteerServoSts "Status of lateral control request";
CM_ SG_ 306 TCSTNowSts "TCSTNowSts";
CM_ SG_ 306 ThrdRowLeHeatgAutoSts "Automatic status feedback signal for seats heating of third row left.";
CM_ SG_ 306 ThrdRowRiHeatgAutoSts "Automatic status feedback signal for seats heating of third row right.";
CM_ SG_ 306 TopPosHmiFeedBack "The signal is uded to inform about the latest successful top position set according: 0(unknown), 1(fail), 2(0 to 20perc), 3(21 to 40 perc), 4(41 to 60perc), 5(61 to 80perc), 6(81 to 100perc)";
CM_ SG_ 306 TopPosHmiFeedBack2 " used to inform about the last successful top position set ";
CM_ SG_ 306 TrOpenerSts "To inform about POT status. moving, opened, closed...";
CM_ SG_ 306 TrOpenPosn "Indicates the actual open state of the tailgate:";
CM_ SG_ 306 VehActvMsgToDrvr "Containing messages to inform the driver that the vehicle is active.";
CM_ SG_ 306 VehEgyCoornDataReq "Req the ADAS Map to sent the horizon data";
CM_ SG_ 369 AcEgyDistbn "Actual AC energy distribution";
CM_ SG_ 369 AudWarn "specifies if there should audio warning when Driver attempts to leave the car when gear not in P";
CM_ SG_ 369 AutoShowModPrpsnEna "show car mode propultion enable conditon";
CM_ SG_ 369 BltLockStAtPassMidBltLockEquid "Belt lock state at 1st row middle passenger seat position. Signal gives out if the belt lock sensor is equipped or not.";
CM_ SG_ 369 BltLockStAtPassMidBltLockSt1 "Belt lock state at 1st row middle passenger seat position. Signal gives out if the belt lock is locked or unlocked. ";
CM_ SG_ 369 BltLockStAtPassMidBltLockSts "Belt lock state at 1st row middle passenger seat position. Signal gives out if the belt lock is faulty or not.";
CM_ SG_ 369 BltLockStAtRowFrthLeBltLockEquid "Signal gives out if belt lock detection sensor is equipped at the 4th row outer left seat.";
CM_ SG_ 369 BltLockStAtRowFrthLeBltLockSt1 "Belt lock state at 4th row outer left seat posiiton. Signal gives out if the belt lock is locked or unlocked. ";
CM_ SG_ 369 BltLockStAtRowFrthLeBltLockSts "Belt lock fault status at the 4th row outer left seat. Signal gives out if belt lock is faulty or not.";
CM_ SG_ 369 BltLockStAtRowFrthMidBltLockEquid "Signal gives out if belt lock detection sensor is equipped at the 4th row middle seat.";
CM_ SG_ 369 BltLockStAtRowFrthMidBltLockSt1 "Belt lock state at 4th row middle seat posiiton. Signal gives out if the belt lock is locked or unlocked.";
CM_ SG_ 369 BltLockStAtRowFrthMidBltLockSts "Belt lock fault status at the 4th row  middle seat. Signal gives out if belt lock is faulty or not.";
CM_ SG_ 369 BltLockStAtRowFrthRiBltLockEquid "Signal gives out if belt lock detection sensor is equipped at the 4th row outer right seat.";
CM_ SG_ 369 BltLockStAtRowFrthRiBltLockSt1 "Belt lock state at 4th row outer right seat posiiton. Signal gives out if the belt lock is locked or unlocked.";
CM_ SG_ 369 BltLockStAtRowFrthRiBltLockSts "Belt lock fault status at the 4th row outer right seat. Signal gives out if belt lock is faulty or not.";
CM_ SG_ 369 BltLockStAtRowThrdMidBltLockEquid "State of belt lock at seating position at middle third row If the belt lock is equipped";
CM_ SG_ 369 BltLockStAtRowThrdMidBltLockSt1 "State of belt lock at seating position at middle third row Belt lock state,  locked/unlocked";
CM_ SG_ 369 BltLockStAtRowThrdMidBltLockSts "State of belt lock at seating position at middle third row Belt lock status, OK/NOK";
CM_ SG_ 369 BtnLockStsAndKeyIdBtnSts "Lock button on the remote (pressed - not pressed) together with information about KeyID of the key used";
CM_ SG_ 369 BtnLockStsAndKeyIdKeyId "Lock button on the remote (pressed - not pressed) together with information about KeyID of the key used";
CM_ SG_ 369 BtnUnlckStsAndKeyIdBtnSts "Unlock button on the remote (pressed - not pressed) together with information about KeyID of the key used";
CM_ SG_ 369 BtnUnlckStsAndKeyIdKeyId "Unlock button on the remote (pressed - not pressed) together with information about KeyID of the key used";
CM_ SG_ 369 CchForFuEcoBarForFuEco "Eco Coach data, both calculated instantaneous and grade eco coach data.";
CM_ SG_ 369 CchForFuEcoGrdForFuEco "Eco Coach data, both calculated instantaneous and grade eco coach data.";
CM_ SG_ 369 CchForPwrEcoBarForPwrEco "Eco Coach data, both calculated instantaneous and grade eco coach data.";
CM_ SG_ 369 CchForPwrEcoGrdForPwrEco "Eco Coach data, both calculated instantaneous and grade eco coach data.";
CM_ SG_ 369 CmptmtFrntWindDewT "compartment front windsreen dew temperature value for climate control.";
CM_ SG_ 369 CoolgLoadGroupCoolgLimd "Reduced or limited capacity";
CM_ SG_ 369 CoolgLoadGroupCoolgLoad2 " Present cooling load";
CM_ SG_ 369 DigKeyApproachReqDigKeyApproaReq "approach request";
CM_ SG_ 369 DigKeyApproachReqKeyId3 "key id";
CM_ SG_ 369 DoorHandleSensorSts "Door handle sensor status";
CM_ SG_ 369 DoorLockUnlockCmdNFCKeyId3 "key id";
CM_ SG_ 369 DoorLockUnlockCmdNFCKeyPrsntSts1 "key present status";
CM_ SG_ 369 DoorLockUnlockCmdNFCPsdNotPsd "NFC status";
CM_ SG_ 369 DoorPassHndlCmd "Shall send command to operate the deployable passenger door handle according to
DoorPassHndlCmd
- Idle
- Deploy
- Retract";
CM_ SG_ 369 DoorRiReHndlCmd "Shall send command to operate the deployable right rear door handle according to
DoorRiReHndlCmd
- Idle
- Deploy
- Retract";
CM_ SG_ 369 DrvrSeatPosPercSeatPosFrntHeiPerc "Front Height Position Percentage";
CM_ SG_ 369 DrvrSeatPosPercSeatPosFrntHeiQF "Front Height Position Quality Factor";
CM_ SG_ 369 DrvrSeatPosPercSeatPosHeiPerc "Height Position Percentage";
CM_ SG_ 369 DrvrSeatPosPercSeatPosHeiQF "Height Position Quality Factor";
CM_ SG_ 369 DrvrSeatPosPercSeatPosSldPerc "Length Position Percentage";
CM_ SG_ 369 DrvrSeatPosPercSeatPosSldQF "Length Position Quality Factor";
CM_ SG_ 369 DstToEmptyIndcdDstToEmpty1 "Indicated distance to Empty (D.T.E.) with indicated unit Distance To Empty";
CM_ SG_ 369 EgyAvgCnsDstSg "average energy consumption of distance single";
CM_ SG_ 369 FuCnsAvgIndcdFuCnsIndcdVal1 "Average Fuel Consumption signal1";
CM_ SG_ 369 FuCnsAvgIndcdFuCnsIndcdVal2 "Average Fuel Consumption signal2";
CM_ SG_ 369 FuCnsAvgIndcdFuCnsIndcdVal3 "Average Fuel Consumption signa for Trip Statistics";
CM_ SG_ 369 FuCnsIndcdVal1 "Instantaneous Fuel Consumption (IFC) with indicated unit IFC value";
CM_ SG_ 369 GearIndcnRecGearIndcn "Record contains two signals. 1. Actual gear displayed for the driver 2. Recommended shift up or down to obtain maximal fuel economy and driveability.";
CM_ SG_ 369 GearIndcnRecGearShiftIndcn "Record contains two signals. 1. Actual gear displayed for the driver 2. Recommended shift up or down to obtain maximal fuel economy and driveability.";
CM_ SG_ 369 GearIndcnRecGearTarIndcn "Record contains two signals. 1. Actual gear displayed for the driver 2. Recommended shift up or down to obtain maximal fuel economy and driveability.";
CM_ SG_ 369 HvConvPwrAct "Actual power consumption of the low-voltage system";
CM_ SG_ 369 ImobRemMgrChkImobDataRemMgrChk0 "Flag to TEM that RVI challenge is available and 5 bytes challenge Challenge byte 0";
CM_ SG_ 369 ImobRemMgrChkImobDataRemMgrChk1 "Flag to TEM that RVI challenge is available and 5 bytes challenge Challenge Byte 1";
CM_ SG_ 369 ImobRemMgrChkImobDataRemMgrChk2 "Flag to TEM that RVI challenge is available and 5 bytes challenge Challenge byte 2";
CM_ SG_ 369 ImobRemMgrChkImobDataRemMgrChk3 "Flag to TEM that RVI challenge is available and 5 bytes challenge Challenge byte 3";
CM_ SG_ 369 ImobRemMgrChkImobDataRemMgrChk4 "Flag to TEM that RVI challenge is available and 5 bytes challenge Challenge byte 4";
CM_ SG_ 369 ImobRemMgrChkSts "Flag to TEM that RVI challenge is available and 5 bytes challenge Challenge available";
CM_ SG_ 369 ImobVehRemMgrSts1ImobVehRemMgrSts "RVI status from CEM to TEM Status for RVI manager";
CM_ SG_ 369 ImobVehRemMgrSts1SpdLimRemMgrSts "RVI status from CEM to TEM Remote vehicle slow down";
CM_ SG_ 369 LnchModIndcnMsg "Indication message to HMI when there has some faults which inhibite active launch mode";
CM_ SG_ 369 LockgFbAcoustReq "LockgFbAcoustReq - Locking Feedback Acoustic Request.

Request from central locking to perform audible locking feedback.

LockActvnLock - Audible locking feedback request
Any other value - No request.";
CM_ SG_ 369 LockgFbToExtLi "LockgFbToExtLi - Lockging Feedback to Exterior Light

Request signal from central locking to exterior light, to perform flashing of turn indicators as locking or unlocking customer feedback.

LockActvnUnlck - Unlocking feedback request
LockActvnLock - Locking feedback request
Any other value - No request";
CM_ SG_ 369 MobDevVentReq "Ventilation Request by Mobile Device";
CM_ SG_ 369 OpenClsCmftReqOpenClsCmftReq "OpenClsCmftReqAndTrigSrc - Comfort Open Close Request and Trig Source.

Request from central locking to perform comfort open and close (and stop), i.e. opening and closing of side door windows and sun roof etc. Contains type of request and trig source:

Type of Request:
NoCmftReq - No Request
OpenCmft - Comfort Open request
ClsCmfg - Comfort Close request
StopCmft - Stop ongoing open/close.

Trig Source:
NoTrigSrc - No Trig Source
SwtInt - Interior central locking switches
KeyRem - Remote key
Keyls - Keyless (capacitive door handles)";
CM_ SG_ 369 OpenClsCmftReqOpenClsCmftTrigSrc "OpenClsCmftReqAndTrigSrc - Comfort Open Close Request and Trig Source.

Request from central locking to perform comfort open and close (and stop), i.e. opening and closing of side door windows and sun roof etc. Contains type of request and trig source:

Type of Request:
NoCmftReq - No Request
OpenCmft - Comfort Open request
ClsCmfg - Comfort Close request
StopCmft - Stop ongoing open/close.

Trig Source:
NoTrigSrc - No Trig Source
SwtInt - Interior central locking switches
KeyRem - Remote key
Keyls - Keyless (capacitive door handles)";
CM_ SG_ 369 PassMidSeatSts "Occupation status based on occupant detection sensor at front row middle seat. ";
CM_ SG_ 369 PwrCnsAvgIndcdPwrCns1 "The average power consumption of Trip1";
CM_ SG_ 369 PwrCnsAvgIndcdPwrCns2 "The average power consumption of Trip2";
CM_ SG_ 369 PwrCnsAvgIndcdPwrCns3 "The average power consumption per unit distance on the energy consumption curve";
CM_ SG_ 369 PwrCnsIndcdPwrCnsIn1 "Instantaneous Electrical Consumption";
CM_ SG_ 369 RainDetected "Informs the system if rain is detected.";
CM_ SG_ 369 RemAllowStrt "Signal indicate validity of remote allow start";
CM_ SG_ 369 SeatOccptAtRowFrthLe "Occupation status based on occupant detection sensor at the 4th row outer left seat. ";
CM_ SG_ 369 SeatOccptAtRowFrthMid "Occupation status based on occupant detection sensor at the 4th middle seat. ";
CM_ SG_ 369 SeatOccptAtRowFrthRi "Occupation status based on occupant detection sensor at the 4th row outer right seat. ";
CM_ SG_ 369 SeatOccptAtRowThrdMid "Occupant presence status at 3rd row ,  right position.";
CM_ SG_ 369 ShortDropWinLeReDoor2 "Left Rear window short drop2 request to open/close frameless doors";
CM_ SG_ 369 ShortDropWinPassDoor2 "Passenger window short drop request to open/close frameless doors";
CM_ SG_ 369 ShortDropWinRiReDoor2 "Right rear window short drop2 request to open/close frameless doors";
CM_ SG_ 369 SunCurtPosnSts "Interface Reporting Sun Curtain Position Status.";
CM_ SG_ 369 TankFlapLockgCmd "TankFlapLockgCmd - Tank Flap Lock Command

Locking command for tank flap lock actuator.

LockActvnOff - Idle Command
LockActvnUnlck - Unlock tank flap
LockActvnLock - Lock tank flap
LockActvnSafe - No command
LockActvnUnlckByCrash - No command";
CM_ SG_ 369 ThmEgyDistbn "Actual  thermal distribution";
CM_ SG_ 369 TotDrvPwrAct "Actual total driving power of power source";
CM_ SG_ 369 TrHndlOutdOpenSts "TrHndlOutOpenSts - Tailgate/Bootlid outer door handle open switch status

Status signal for the tailgate/bootlid outer door handle soft touch switch.

Psd - Pressed
NotPsd - Not Pressed";
CM_ SG_ 369 TrsmFltIndcn "TCM uses signal Transmission Fault Indication to request text message ilumination to driver. Signal is transmitted to both ECM and DIM.Signal consits of 32 slots. One slot is one unique text message. Default value is 0 (No request)";
CM_ SG_ 666 AcHiSideP "Ac pressure in high side measured by sensors.";
CM_ SG_ 666 ActvnOfWshrFrntSafe "Activate front washer";
CM_ SG_ 666 ActvOfHorn "Activate and deactive the Vehicle Horn";
CM_ SG_ 666 AirPtcPCBTempActl "Air PTC actual PCB temperature.";
CM_ SG_ 666 AirTFromHeatgEstimd "Estimated air temperature from heater.";
CM_ SG_ 666 BattCpEstimdRaw "Estimated battery capacity";
CM_ SG_ 666 ChrgEquipIDc "The actual output current from DC charging equipment .";
CM_ SG_ 666 CmprReqCmprSpdReq "AC compressor rotational speed request.";
CM_ SG_ 666 CooltFlowInCmptmtCirc "Informs of coolant flow in the heat exchange. Created for the short coolant circuit in hybrid cars.";
CM_ SG_ 666 CooltHeatrTIntk "Coolant temperature at  intake of heater.";
CM_ SG_ 666 CooltHeatrTOutl "Coolant temperature at outlet of heater.";
CM_ SG_ 666 DCDCConsDyvCyc "Accumulated energy consumption of DCDC at the high voltage end during the driving cycle";
CM_ SG_ 666 DChrgStrtEngRes "Status of the Discharge Start of engine";
CM_ SG_ 666 DispIdlChrgPwr "Charging power idle charging";
CM_ SG_ 666 EcmRoilgCntr "Reserved roiling counter for ECM.";
CM_ SG_ 666 EldtPmpPwrCns "Coolant pump power consumption in ELDT cooling circuit.";
CM_ SG_ 666 EngCooltInhbFlow "Inhibitation of non-crucial coolant flow requests. Sent out to inform that the eninge is in heat up phase and that all additional coolant flow will postphone the time when the engine has reached normal operating temperature.";
CM_ SG_ 666 EngCooltLoFlowReq "Coolant flow request to the auxillary waterpump. (l/min)";
CM_ SG_ 666 EngCooltPmpPwrCns "Actual electrical power consumed by engine water pump.";
CM_ SG_ 666 FanPwrCns "Actual electrical power consumed by the engine cooling fan.";
CM_ SG_ 666 FuelConsDrvCyc "Cumulative fuel consumption during PEM activation";
CM_ SG_ 666 HvahFltIndcnReq "HVAH high voltage fault indication request.";
CM_ SG_ 666 HvEgyCnsAllwdForClima "How much available energy is available for compartment climatisation. Estimated available energy from wall socket or Hv battery.";
CM_ SG_ 666 HvEgyLoadFctReq "Information that Hv system is active. Usage mode state shall not be abandoned.";
CM_ SG_ 666 HvPwrAvlForClimaEstimd "An estimation of how much HV-power that is available for climatization.";
CM_ SG_ 666 HvPwrEgyPrio "Information about which session is prioritized (charging, cooling, climatization etc).";
CM_ SG_ 666 HvWtrHeatrPwrCnsAllwd "Power consumption allowed for HVCH";
CM_ SG_ 666 HwRowRearLeLegRstHeiMotCtrl "Signal to control rear row left leg rest height adjustment motor, in a system with only one rear row.";
CM_ SG_ 666 HwRowRearLeLegRstLenMotCtrl "Signal to control rear row left leg rest motor, in a system with only one rear row.";
CM_ SG_ 666 HwRowRearRiLegRstHeiMotCtrl "Signal to control rear row right leg rest heigth adjustment motor, in a system with only one rear row.";
CM_ SG_ 666 HwRowRearRiLegRstLenMotCtrl "Signal to control rear row right leg rest motor, in a system with only one rear row.";
CM_ SG_ 666 HwRowSecLeInclMotCtrl "control second row left inclination motor";
CM_ SG_ 666 HwRowSecLeSldMotCtrl "control second row left slide motor";
CM_ SG_ 666 HwRowSecRiInclMotCtrl "control second row right inclination motor";
CM_ SG_ 666 HwRowSecRiSldMotCtrl "control second row right slide motor";
CM_ SG_ 666 HwRowThrdLeInclMotCtrl "control third row left inclination motor";
CM_ SG_ 666 HwRowThrdRiInclMotCtrl "control third row right inclination motor";
CM_ SG_ 666 MirrActvBtn "The button to active mirror adjustment function on DIM";
CM_ SG_ 666 MirrCmdAtDrvrMirrDwnCmd "Mirror Down/Dip Command";
CM_ SG_ 666 MirrCmdAtDrvrMirrFoldCmd "Mirror Fold Command";
CM_ SG_ 666 MirrCmdAtDrvrMirrPosAdjCmd "Mirror Position Adjust Command";
CM_ SG_ 666 MirrDefrstAtDrvSts "Status signal exterior rear view mirror electrical defroster driver side.";
CM_ SG_ 666 MirrDirReq "Signal from the Driver door switchpack to the Driver Door module containing information of the position of the  mirror manoeuvring joystick
";
CM_ SG_ 666 MirrPosnAdjFromSetTarPosnDrvrMirrPosnAdjCldLeRi "Driver Mirror Position adjustment from Setting target postion Lef-Right.";
CM_ SG_ 666 MirrPosnAdjFromSetTarPosnDrvrMirrPosnAdjCldUpDwn "Driver Mirror Position adjustment from Setting target postion Up-Down.";
CM_ SG_ 666 MirrSelnReq "Signal indicating what wing mirror has been selected to be adjusted (none, left, right or both)";
CM_ SG_ 666 MotGenDrvCyc "Cumulative energy generation of all motors in this driving cycle";
CM_ SG_ 666 RngExtd "Extended range, km";
CM_ SG_ 666 RoadSlopeInst "Real-time road slope information";
CM_ SG_ 666 TOCCooltFlowReq "coolant flow requirement for TOC";
CM_ SG_ 666 TrlrModPrpsnSts "Trailer mode status signal TrlrModPrpsnSts.
";
CM_ SG_ 336 ActvnOfHzrd "CEM internal signal. PWM signal to control Hazard button symbol illumination.";
CM_ SG_ 336 BookChrgnTarValFb "Feedback the corresponding signal when receives BookChrgnTarVal from TCAM";
CM_ SG_ 336 ChrgLidRearLockCmd "ChrgLidRearLockCmd - Rear Charge Lid Lock Command

Locking command for tank flap lock actuator.

LockActvnOff - Idle Command
LockActvnUnlck - Unlock tank flap
LockActvnLock - Lock tank flap
LockActvnSafe - No command
LockActvnUnlckByCrash - No command";
CM_ SG_ 336 ChrgnOrDisChrgnStsFb "Propulsion subsystem feedback charging and discharging status";
CM_ SG_ 336 DispOfPrpsnMod "Description: Actual powertrain propulsion mode of the hybrid propulsion system. Usage: For hybrid power flow status display in HMI.";
CM_ SG_ 336 DstEstimdToEmptyForDrvgElec "Estimated remaining driving range in electric only driving for current HV battery energy content.";
CM_ SG_ 336 DstFromDestinationFb "Feedback the corresponding signal when receives DstFromDestination from HMI subsystem";
CM_ SG_ 336 DstToEmptyIndcdDstToEmpty2 "Indicates the standard fuel range of the vehicle";
CM_ SG_ 336 KeyLostWarnIndcn "Key lost warning indication for DIM to show a message and for IHU to play a sound.";
CM_ SG_ 336 KeyRmnIndcn "Key reminder indication for IHU to play a sound.";
CM_ SG_ 336 LockgFbAudioReq "Locking feedback to Audio ";
CM_ SG_ 336 MemBtnPsdMemBtn1 "Driver Memory Button 2";
CM_ SG_ 336 MemBtnPsdMemBtn2 "Driver Memory Button 2";
CM_ SG_ 336 MemBtnPsdMemBtn3 "Driver Memory Button 3";
CM_ SG_ 336 MemBtnPsdMemButM "Driver Memory Button";
CM_ SG_ 336 RowSecLeSeatInAutMovmt "Row Second Left Seat In Automatic Movement";
CM_ SG_ 336 RowSecRiSeatInAutMovmt "Row Second Right Seat In Automatic Movement";
CM_ SG_ 336 SecRowSeatHeatgActlPwrCnsLe "Actual power consumption for second row left seat heating.";
CM_ SG_ 336 SecRowSeatHeatgActlPwrCnsRi "Actual power consumption for second row right seat heating.";
CM_ SG_ 336 SecRowSeatHeatgDesPwrCnsLe "Desired power consumption for second row left seat heating.";
CM_ SG_ 336 SecRowSeatHeatgDesPwrCnsRi "Desired power consumption for second row right seat heating.";
CM_ SG_ 336 SecRowSeatVentnActlPwrCnsLe "Second row left seat ventilation actual power consumption.";
CM_ SG_ 336 SecRowSeatVentnActlPwrCnsRi "Second row right seat ventilation actual power consumption.";
CM_ SG_ 336 SecRowSeatVentnDesPwrCnsLe "Second row left ventilation desired power consumption.";
CM_ SG_ 336 SecRowSeatVentnDesPwrCnsRi "Second row right ventilation desired power consumption.";
CM_ SG_ 336 ThrdRowSeatHeatgActlPwrCnsLe "Actual power consumption for third row left seat heating.";
CM_ SG_ 336 ThrdRowSeatHeatgActlPwrCnsRi "Actual power consumption for third row right seat heating.";
CM_ SG_ 336 ThrdRowSeatHeatgDesPwrCnsLe "Desired power consumption for third row left seat heating.";
CM_ SG_ 336 ThrdRowSeatHeatgDesPwrCnsRi "Desired power consumption for third row right seat heating.";
CM_ SG_ 336 ThrdRowSeatVentnActlPwrCnsLe "Third row left seat ventilation actual power consumption.";
CM_ SG_ 336 ThrdRowSeatVentnActlPwrCnsRi "Third row right seat ventilation actual power consumption.";
CM_ SG_ 336 ThrdRowSeatVentnDesPwrCnsLe "Third row left ventilation desired power consumption.";
CM_ SG_ 336 ThrdRowSeatVentnDesPwrCnsRi "Third row right ventilation desired power consumption.";
CM_ SG_ 336 WadeProtnIndcn "Wade Protection Indication";
BA_DEF_ BO_ "CANFD_BRS" ENUM "0","1";
BA_DEF_ BO_ "GenMsgCycleTime" INT 0 65536;
BA_DEF_ BO_ "GenMsgDelayTime" INT 0 65536;
BA_DEF_ BO_ "GenMsgSendType" ENUM "cyclic", "spontaneous", "not-used", "not-used", "not-used", "cyclicAndSpontaneous", "not-used", "cyclicIfActive", "NoMsgSendType";
BA_DEF_ BO_ "GenMsgStartDelayTime" INT 0 65536;
BA_DEF_ BO_ "VFrameFormat" ENUM "StandardCAN","ExtendedCAN","reserved","J1939PG","reserved","reserved","reserved","reserved","reserved","reserved","reserved","reserved","reserved","reserved","StandardCAN_FD","ExtendedCAN_FD";
BA_DEF_ SG_ "GenSigSendType" ENUM "Cyclic","OnWrite","OnWriteWithRepetition","OnChange","OnChangeWithRepetition","IfActive","IfActiveWithRepetition","NoSigSendType";
BA_DEF_ SG_ "GenSigStartValue" HEX 0 80000000;
BA_DEF_ BO_ "GenMsgILSupport" ENUM "No","Yes";
BA_DEF_ BO_ "NmAsrMessage" ENUM "No","Yes";
BA_DEF_ SG_ "GenSigFuncType" ENUM "NoFunction","n/a","n/a","n/a","n/a","n/a","n/a","n/a","n/a","n/a","n/a","n/a","n/a","n/a","n/a","CHK","CNTR","n/a","n/a","n/a","CNTR_AR_01","CRC_AR_01_BOTH","CRC_AR_01_ALT","CRC_AR_01_LOW","CRC_AR_01_NIBBLE","CNTR_AR_04","CRC_AR_04A","CNTR_AR_05","CRC_AR_05";
BA_DEF_ SG_ "GenSigDataID" STRING;
BA_DEF_DEF_ "CANFD_BRS" "1";
BA_DEF_DEF_ "GenSigStartValue" 0;
BA_DEF_DEF_ "VFrameFormat" "J1939PG";
BA_DEF_DEF_ "GenSigSendType" "NoSigSendType";
BA_DEF_DEF_ "GenMsgCycleTime" 0;
BA_DEF_DEF_ "GenMsgDelayTime" 0;
BA_DEF_DEF_ "GenMsgStartDelayTime" 0;
BA_DEF_DEF_ "GenMsgSendType" "NoMsgSendType";
BA_DEF_DEF_ "GenMsgILSupport" "Yes";
BA_DEF_DEF_ "NmAsrMessage" "No";
BA_DEF_DEF_ "GenSigFuncType" "NoFunction";
BA_DEF_DEF_ "GenSigDataID" "";

BA_ "GenMsgCycleTime" BO_ 293 40.000;
BA_ "GenMsgSendType" BO_ 293 0;
BA_ "VFrameFormat" BO_ 293 14;

BA_ "GenMsgDelayTime" BO_ 1288 20.000;
BA_ "GenMsgSendType" BO_ 1288 1;
BA_ "VFrameFormat" BO_ 1288 0;

BA_ "GenMsgDelayTime" BO_ 1377 90.000;
BA_ "GenMsgSendType" BO_ 1377 1;
BA_ "VFrameFormat" BO_ 1377 14;

BA_ "GenMsgDelayTime" BO_ 1412 50.000;
BA_ "GenMsgSendType" BO_ 1412 1;
BA_ "VFrameFormat" BO_ 1412 14;

BA_ "GenMsgDelayTime" BO_ 1378 100.000;
BA_ "GenMsgSendType" BO_ 1378 1;
BA_ "VFrameFormat" BO_ 1378 14;

BA_ "GenMsgCycleTime" BO_ 1169 1000.000;
BA_ "GenMsgSendType" BO_ 1169 0;
BA_ "VFrameFormat" BO_ 1169 14;

BA_ "GenMsgCycleTime" BO_ 306 50.000;
BA_ "GenMsgSendType" BO_ 306 0;
BA_ "VFrameFormat" BO_ 306 14;

BA_ "GenMsgCycleTime" BO_ 369 80.000;
BA_ "GenMsgSendType" BO_ 369 0;
BA_ "VFrameFormat" BO_ 369 14;

BA_ "GenMsgCycleTime" BO_ 666 400.000;
BA_ "GenMsgSendType" BO_ 666 0;
BA_ "VFrameFormat" BO_ 666 14;

BA_ "GenMsgCycleTime" BO_ 336 60.000;
BA_ "GenMsgSendType" BO_ 336 0;
BA_ "VFrameFormat" BO_ 336 14;

BA_ "GenMsgDelayTime" BO_ 1715 5.000;
BA_ "GenMsgSendType" BO_ 1715 1;
BA_ "VFrameFormat" BO_ 1715 14;

BA_ "GenMsgDelayTime" BO_ 1716 5.000;
BA_ "GenMsgSendType" BO_ 1716 1;
BA_ "VFrameFormat" BO_ 1716 14;

BA_ "GenMsgDelayTime" BO_ 1557 5.000;
BA_ "GenMsgSendType" BO_ 1557 1;
BA_ "VFrameFormat" BO_ 1557 14;

BA_ "GenMsgDelayTime" BO_ 1552 5.000;
BA_ "GenMsgSendType" BO_ 1552 1;
BA_ "VFrameFormat" BO_ 1552 14;

BA_ "GenMsgDelayTime" BO_ 1553 5.000;
BA_ "GenMsgSendType" BO_ 1553 1;
BA_ "VFrameFormat" BO_ 1553 14;

BA_ "GenMsgDelayTime" BO_ 1577 5.000;
BA_ "GenMsgSendType" BO_ 1577 1;
BA_ "VFrameFormat" BO_ 1577 14;

BA_ "GenMsgDelayTime" BO_ 1585 5.000;
BA_ "GenMsgSendType" BO_ 1585 1;
BA_ "VFrameFormat" BO_ 1585 14;

BA_ "GenMsgDelayTime" BO_ 1586 5.000;
BA_ "GenMsgSendType" BO_ 1586 1;
BA_ "VFrameFormat" BO_ 1586 14;

BA_ "GenMsgDelayTime" BO_ 2041 5.000;
BA_ "GenMsgSendType" BO_ 2041 1;
BA_ "VFrameFormat" BO_ 2041 0;

BA_ "GenMsgDelayTime" BO_ 1593 5.000;
BA_ "GenMsgSendType" BO_ 1593 1;
BA_ "VFrameFormat" BO_ 1593 14;

BA_ "GenMsgDelayTime" BO_ 1650 5.000;
BA_ "GenMsgSendType" BO_ 1650 1;
BA_ "VFrameFormat" BO_ 1650 14;

BA_ "GenMsgDelayTime" BO_ 1537 5.000;
BA_ "GenMsgSendType" BO_ 1537 1;
BA_ "VFrameFormat" BO_ 1537 14;

BA_ "GenMsgDelayTime" BO_ 1408 50.000;
BA_ "GenMsgSendType" BO_ 1408 1;
BA_ "VFrameFormat" BO_ 1408 14;

BA_ "GenMsgDelayTime" BO_ 1409 50.000;
BA_ "GenMsgSendType" BO_ 1409 1;
BA_ "VFrameFormat" BO_ 1409 14;

BA_ "GenMsgDelayTime" BO_ 1410 50.000;
BA_ "GenMsgSendType" BO_ 1410 1;
BA_ "VFrameFormat" BO_ 1410 14;

BA_ "GenMsgDelayTime" BO_ 1411 50.000;
BA_ "GenMsgSendType" BO_ 1411 1;
BA_ "VFrameFormat" BO_ 1411 14;
BA_ "GenMsgILSupport" BO_ 1288 0;
BA_ "NmAsrMessage" BO_ 1288 1;
BA_ "GenSigSendType" SG_ 369 AcEgyDistbn 0;
BA_ "GenSigSendType" SG_ 1169 AccrpedlStsChks 0;
BA_ "GenSigSendType" SG_ 1169 AccrpedlStsCntr 0;
BA_ "GenSigSendType" SG_ 1169 AccrpedlStsFltSts 0;
BA_ "GenSigSendType" SG_ 306 ActnOfDaytiRunngLampPass 0;
BA_ "GenSigSendType" SG_ 306 ActnOfDynRePos 0;
BA_ "GenSigSendType" SG_ 306 ActnOfFrntFogLampPass 0;
BA_ "GenSigSendType" SG_ 306 ActnOfFrntPosnLampPass 0;
BA_ "GenSigSendType" SG_ 306 ActnOfHiBeamPass 0;
BA_ "GenSigSendType" SG_ 1169 ActnOfLedHiBeam 0;
BA_ "GenSigSendType" SG_ 1169 ActnOfLedLoBeamActnOfLedLoBeam 0;
BA_ "GenSigDataID" SG_ 1169 ActnOfLedLoBeamChks "0x441";
BA_ "GenSigFuncType" SG_ 1169 ActnOfLedLoBeamChks 15;
BA_ "GenSigSendType" SG_ 1169 ActnOfLedLoBeamChks 0;
BA_ "GenSigFuncType" SG_ 1169 ActnOfLedLoBeamCntr 16;
BA_ "GenSigSendType" SG_ 1169 ActnOfLedLoBeamCntr 0;
BA_ "GenSigDataID" SG_ 306 ActnOfLoBeamPassChks "0x1FA2";
BA_ "GenSigFuncType" SG_ 306 ActnOfLoBeamPassChks 15;
BA_ "GenSigSendType" SG_ 306 ActnOfLoBeamPassChks 0;
BA_ "GenSigFuncType" SG_ 306 ActnOfLoBeamPassCntr 16;
BA_ "GenSigSendType" SG_ 306 ActnOfLoBeamPassCntr 0;
BA_ "GenSigSendType" SG_ 306 ActnOfLoBeamPassOnOff 0;
BA_ "GenSigSendType" SG_ 306 ActnOfReFogLampDrv 0;
BA_ "GenSigSendType" SG_ 306 ActnOfRePosnLampPass 0;
BA_ "GenSigSendType" SG_ 306 ActnOfReRegPlateLamp 0;
BA_ "GenSigSendType" SG_ 306 ActnOfRvsgLampPass 0;
BA_ "GenSigSendType" SG_ 666 ActvOfHorn 0;
BA_ "GenSigSendType" SG_ 306 ActvnOfApproach 0;
BA_ "GenSigSendType" SG_ 306 ActvnOfCarLoctr 0;
BA_ "GenSigSendType" SG_ 306 ActvnOfGoodByeLi 0;
BA_ "GenSigSendType" SG_ 306 ActvnOfHndlDoorLi1HndlDoorLiDrvr 0;
BA_ "GenSigSendType" SG_ 306 ActvnOfHndlDoorLi1HndlDoorLiDrvrRe 0;
BA_ "GenSigSendType" SG_ 306 ActvnOfHndlDoorLi1HndlDoorLiPass 0;
BA_ "GenSigSendType" SG_ 306 ActvnOfHndlDoorLi1HndlDoorLiPassRe 0;
BA_ "GenSigSendType" SG_ 306 ActvnOfHomeSafe 0;
BA_ "GenSigSendType" SG_ 336 ActvnOfHzrd 0;
BA_ "GenSigSendType" SG_ 306 ActvnOfLiForComity 0;
BA_ "GenSigSendType" SG_ 306 ActvnOfLiForSpkr 0;
BA_ "GenSigSendType" SG_ 306 ActvnOfLiForWait 0;
BA_ "GenSigSendType" SG_ 306 ActvnOfPudLi 0;
BA_ "GenSigSendType" SG_ 306 ActvnOfWaitMode 0;
BA_ "GenSigSendType" SG_ 1169 ActvnOfWiprRe 0;
BA_ "GenSigSendType" SG_ 666 ActvnOfWshrFrntSafe 0;
BA_ "GenSigStartValue" SG_ 666 AirPtcPCBTempActl 40;
BA_ "GenSigSendType" SG_ 666 AirTFromHeatgEstimd 0;
BA_ "GenSigSendType" SG_ 1169 AsySftyStandStillReq 0;
BA_ "GenSigSendType" SG_ 369 AudWarn 0;
BA_ "GenSigSendType" SG_ 369 AutoShowModPrpsnEna 0;
BA_ "GenSigSendType" SG_ 1169 BattChrgnBalDurgDrvgRaw 0;
BA_ "GenSigStartValue" SG_ 1169 BattChrgnBalDurgDrvgRaw 20000;
BA_ "GenSigSendType" SG_ 1169 BattCircOpenU 0;
BA_ "GenSigSendType" SG_ 1169 BattCpEstimdAtTNomRaw 0;
BA_ "GenSigSendType" SG_ 666 BattCpEstimdRaw 0;
BA_ "GenSigStartValue" SG_ 666 BattCpEstimdRaw 80;
BA_ "GenSigSendType" SG_ 1169 BattCpRel 0;
BA_ "GenSigSendType" SG_ 1169 BattCycChrgCntrRaw 0;
BA_ "GenSigSendType" SG_ 1169 BattCycDchaCntrDurgConvceRaw 0;
BA_ "GenSigSendType" SG_ 1169 BattCycDchaCntrDurgDrvgRaw 0;
BA_ "GenSigSendType" SG_ 1169 BattCycDchaCntrDurgQuiscPhaRaw 0;
BA_ "GenSigSendType" SG_ 306 BattFltStsPrimBattFltStsPrm 0;
BA_ "GenSigDataID" SG_ 306 BattFltStsPrimChks "0x1784";
BA_ "GenSigFuncType" SG_ 306 BattFltStsPrimChks 15;
BA_ "GenSigSendType" SG_ 306 BattFltStsPrimChks 0;
BA_ "GenSigFuncType" SG_ 306 BattFltStsPrimCntr 16;
BA_ "GenSigSendType" SG_ 306 BattFltStsPrimCntr 0;
BA_ "GenSigSendType" SG_ 1169 BattIQuiscAvgRaw 0;
BA_ "GenSigStartValue" SG_ 1169 BattIQuiscAvgRaw 511;
BA_ "GenSigSendType" SG_ 1169 BattIQuiscFildLongRaw 0;
BA_ "GenSigStartValue" SG_ 1169 BattIQuiscFildLongRaw 511;
BA_ "GenSigSendType" SG_ 1169 BattIQuiscFildShoRaw 0;
BA_ "GenSigStartValue" SG_ 1169 BattIQuiscFildShoRaw 511;
BA_ "GenSigSendType" SG_ 1169 BattIRaw 0;
BA_ "GenSigStartValue" SG_ 1169 BattIRaw 32768;
BA_ "GenSigSendType" SG_ 1169 BattRAtTNomRaw 0;
BA_ "GenSigSendType" SG_ 1169 BattRRaw 0;
BA_ "GenSigSendType" SG_ 1169 BattSnsrCalcnNotVldRaw 0;
BA_ "GenSigSendType" SG_ 1169 BattSnsrHwFltRaw 0;
BA_ "GenSigSendType" SG_ 1169 BattTRaw 0;
BA_ "GenSigStartValue" SG_ 1169 BattTRaw 256;
BA_ "GenSigSendType" SG_ 1169 BattTiInSrvRaw 0;
BA_ "GenSigSendType" SG_ 369 BltLockStAtPassMidBltLockEquid 0;
BA_ "GenSigStartValue" SG_ 369 BltLockStAtPassMidBltLockEquid 1;
BA_ "GenSigSendType" SG_ 369 BltLockStAtPassMidBltLockSt1 0;
BA_ "GenSigSendType" SG_ 369 BltLockStAtPassMidBltLockSts 0;
BA_ "GenSigStartValue" SG_ 369 BltLockStAtPassMidBltLockSts 1;
BA_ "GenSigSendType" SG_ 369 BltLockStAtRowFrthLeBltLockEquid 0;
BA_ "GenSigStartValue" SG_ 369 BltLockStAtRowFrthLeBltLockEquid 1;
BA_ "GenSigSendType" SG_ 369 BltLockStAtRowFrthLeBltLockSt1 0;
BA_ "GenSigSendType" SG_ 369 BltLockStAtRowFrthLeBltLockSts 0;
BA_ "GenSigStartValue" SG_ 369 BltLockStAtRowFrthLeBltLockSts 1;
BA_ "GenSigSendType" SG_ 369 BltLockStAtRowFrthMidBltLockEquid 0;
BA_ "GenSigStartValue" SG_ 369 BltLockStAtRowFrthMidBltLockEquid 1;
BA_ "GenSigSendType" SG_ 369 BltLockStAtRowFrthMidBltLockSt1 0;
BA_ "GenSigSendType" SG_ 369 BltLockStAtRowFrthMidBltLockSts 0;
BA_ "GenSigStartValue" SG_ 369 BltLockStAtRowFrthMidBltLockSts 1;
BA_ "GenSigSendType" SG_ 369 BltLockStAtRowFrthRiBltLockEquid 0;
BA_ "GenSigStartValue" SG_ 369 BltLockStAtRowFrthRiBltLockEquid 1;
BA_ "GenSigSendType" SG_ 369 BltLockStAtRowFrthRiBltLockSt1 0;
BA_ "GenSigSendType" SG_ 369 BltLockStAtRowFrthRiBltLockSts 0;
BA_ "GenSigStartValue" SG_ 369 BltLockStAtRowFrthRiBltLockSts 1;
BA_ "GenSigSendType" SG_ 369 BltLockStAtRowThrdMidBltLockEquid 0;
BA_ "GenSigStartValue" SG_ 369 BltLockStAtRowThrdMidBltLockEquid 1;
BA_ "GenSigSendType" SG_ 369 BltLockStAtRowThrdMidBltLockSt1 0;
BA_ "GenSigSendType" SG_ 369 BltLockStAtRowThrdMidBltLockSts 0;
BA_ "GenSigStartValue" SG_ 369 BltLockStAtRowThrdMidBltLockSts 1;
BA_ "GenSigSendType" SG_ 336 BookChrgnTarValFb 0;
BA_ "GenSigStartValue" SG_ 336 BookChrgnTarValFb 1000;
BA_ "GenSigSendType" SG_ 369 BtnLockStsAndKeyIdBtnSts 0;
BA_ "GenSigSendType" SG_ 369 BtnLockStsAndKeyIdKeyId 0;
BA_ "GenSigSendType" SG_ 369 BtnUnlckStsAndKeyIdBtnSts 0;
BA_ "GenSigSendType" SG_ 369 BtnUnlckStsAndKeyIdKeyId 0;
BA_ "GenSigSendType" SG_ 1169 CEMdevelpsignalgroupVMM1Functiondevpsignalgroup1 0;
BA_ "GenSigSendType" SG_ 1169 CEMdevelpsignalgroupVMM1Functiondevpsignalgroup2 0;
BA_ "GenSigSendType" SG_ 1169 CEMdevelpsignalgroupVMM1Functiondevpsignalgroup3 0;
BA_ "GenSigSendType" SG_ 1169 CEMdevelpsignalgroupVMM1Functiondevpsignalgroup4 0;
BA_ "GenSigSendType" SG_ 1169 CEMdevelpsignalgroupVMM1Functiondevpsignalgroup5 0;
BA_ "GenSigSendType" SG_ 1169 CEMdevelpsignalgroupVMM1Functiondevpsignalgroup6 0;
BA_ "GenSigSendType" SG_ 1169 CEMdevelpsignalgroupVMM1Functiondevpsignalgroup7 0;
BA_ "GenSigSendType" SG_ 1169 CEMdevelpsignalgroupVMM1Functiondevpsignalgroup8 0;
BA_ "GenSigSendType" SG_ 306 CarCfgInfoToWPC 0;
BA_ "GenSigSendType" SG_ 1169 CarModDispdWdDispd 0;
BA_ "GenSigSendType" SG_ 1169 CarModDynoReq 0;
BA_ "GenSigStartValue" SG_ 1169 CarModDynoReq 4;
BA_ "GenSigSendType" SG_ 306 ChdLockLeftSts 0;
BA_ "GenSigSendType" SG_ 306 ChdLockRightStsToHmi 0;
BA_ "GenSigSendType" SG_ 306 ChdPrtnLeftStsToHmi 0;
BA_ "GenSigSendType" SG_ 666 ChrgEquipIDc 0;
BA_ "GenSigStartValue" SG_ 666 ChrgEquipIDc 16380;
BA_ "GenSigSendType" SG_ 306 ChrgLidCombLockCmd 0;
BA_ "GenSigSendType" SG_ 336 ChrgLidRearLockCmd 0;
BA_ "GenSigSendType" SG_ 306 ChrgnLtgSts 0;
BA_ "GenSigSendType" SG_ 336 ChrgnOrDisChrgnStsFb 0;
BA_ "GenSigSendType" SG_ 306 CinhDrvrReSts 0;
BA_ "GenSigSendType" SG_ 306 CinhDrvrReSwt 0;
BA_ "GenSigSendType" SG_ 306 CinhDrvrSts 0;
BA_ "GenSigSendType" SG_ 306 CinhDrvrSwt 0;
BA_ "GenSigSendType" SG_ 666 CmprReqCmprSpdReq 0;
BA_ "GenSigSendType" SG_ 1169 CmptFrntWindDewT 0;
BA_ "GenSigStartValue" SG_ 1169 CmptFrntWindDewT 600;
BA_ "GenSigSendType" SG_ 1169 CmptFrntWindT 0;
BA_ "GenSigStartValue" SG_ 1169 CmptFrntWindT 650;
BA_ "GenSigSendType" SG_ 369 CmptmtFrntWindDewT 0;
BA_ "GenSigStartValue" SG_ 369 CmptmtFrntWindDewT 600;
BA_ "GenSigSendType" SG_ 1169 CnvnAllwd 0;
BA_ "GenSigSendType" SG_ 1169 CnvnReq 0;
BA_ "GenSigSendType" SG_ 369 CoolgLoadGroupCoolgLimd 0;
BA_ "GenSigSendType" SG_ 369 CoolgLoadGroupCoolgLoad2 0;
BA_ "GenSigSendType" SG_ 666 CooltFlowInCmptmtCirc 0;
BA_ "GenSigSendType" SG_ 666 CooltHeatrTIntk 0;
BA_ "GenSigStartValue" SG_ 666 CooltHeatrTIntk 40;
BA_ "GenSigSendType" SG_ 666 CooltHeatrTOutl 0;
BA_ "GenSigStartValue" SG_ 666 CooltHeatrTOutl 40;
BA_ "GenSigSendType" SG_ 666 DCDCConsDyvCyc 0;
BA_ "GenSigSendType" SG_ 666 DChrgStrtEngRes 0;
BA_ "GenSigSendType" SG_ 306 DchaChrgnTarValFb 0;
BA_ "GenSigStartValue" SG_ 306 DchaChrgnTarValFb 200;
BA_ "GenSigSendType" SG_ 369 DigKeyApproachReqDigKeyApproaReq 0;
BA_ "GenSigSendType" SG_ 369 DigKeyApproachReqKeyId3 0;
BA_ "GenSigSendType" SG_ 306 DigKeyPasEntryDiSts 0;
BA_ "GenSigSendType" SG_ 306 DlyClsActv 0;
BA_ "GenSigSendType" SG_ 1169 DoorDrvrSwtIntrLockgReq 0;
BA_ "GenSigSendType" SG_ 369 DoorHandleSensorSts 0;
BA_ "GenSigSendType" SG_ 306 DoorLeReHndlCmd 0;
BA_ "GenSigSendType" SG_ 369 DoorLockUnlockCmdNFCKeyId3 0;
BA_ "GenSigSendType" SG_ 369 DoorLockUnlockCmdNFCKeyPrsntSts1 0;
BA_ "GenSigSendType" SG_ 369 DoorLockUnlockCmdNFCPsdNotPsd 0;
BA_ "GenSigSendType" SG_ 369 DoorPassHndlCmd 0;
BA_ "GenSigSendType" SG_ 369 DoorRiReHndlCmd 0;
BA_ "GenSigSendType" SG_ 293 DrvModReqForChampnMod 0;
BA_ "GenSigSendType" SG_ 306 DrvrGearLvrInfoIndcn 0;
BA_ "GenSigSendType" SG_ 306 DrvrGearLvrLockIndcn 0;
BA_ "GenSigSendType" SG_ 369 DrvrSeatPosPercSeatPosFrntHeiPerc 0;
BA_ "GenSigStartValue" SG_ 369 DrvrSeatPosPercSeatPosFrntHeiPerc 1000;
BA_ "GenSigSendType" SG_ 369 DrvrSeatPosPercSeatPosFrntHeiQF 0;
BA_ "GenSigStartValue" SG_ 369 DrvrSeatPosPercSeatPosFrntHeiQF 1;
BA_ "GenSigSendType" SG_ 369 DrvrSeatPosPercSeatPosHeiPerc 0;
BA_ "GenSigStartValue" SG_ 369 DrvrSeatPosPercSeatPosHeiPerc 1000;
BA_ "GenSigSendType" SG_ 369 DrvrSeatPosPercSeatPosHeiQF 0;
BA_ "GenSigStartValue" SG_ 369 DrvrSeatPosPercSeatPosHeiQF 1;
BA_ "GenSigSendType" SG_ 369 DrvrSeatPosPercSeatPosSldPerc 0;
BA_ "GenSigStartValue" SG_ 369 DrvrSeatPosPercSeatPosSldPerc 1000;
BA_ "GenSigSendType" SG_ 369 DrvrSeatPosPercSeatPosSldQF 0;
BA_ "GenSigStartValue" SG_ 369 DrvrSeatPosPercSeatPosSldQF 1;
BA_ "GenSigSendType" SG_ 1169 DrvrSteerWhlHldGroupDrvrSteerWhlHld 0;
BA_ "GenSigSendType" SG_ 1169 DrvrSteerWhlHldGroupDrvrSteerWhlHldQly 0;
BA_ "GenSigSendType" SG_ 336 DstEstimdToEmptyForDrvgElec 0;
BA_ "GenSigSendType" SG_ 336 DstFromDestinationFb 0;
BA_ "GenSigSendType" SG_ 336 DstToEmptyIndcdDstToEmpty2 0;
BA_ "GenSigSendType" SG_ 306 DstTrvldFromSftyBkp 0;
BA_ "GenSigSendType" SG_ 306 DstTrvldVldFromSftyBkp 0;
BA_ "GenSigSendType" SG_ 666 EcmRoilgCntr 0;
BA_ "GenSigSendType" SG_ 369 EgyAvgCnsDstSg 0;
BA_ "GenSigSendType" SG_ 1169 EgyLvlElecDrvInfo 0;
BA_ "GenSigSendType" SG_ 1169 EgyMeas 0;
BA_ "GenSigSendType" SG_ 1169 EgyMeasIntlIntl1 0;
BA_ "GenSigSendType" SG_ 1169 EgyMeasIntlIntl2 0;
BA_ "GenSigSendType" SG_ 1169 EgyMeasIntlIntl3 0;
BA_ "GenSigSendType" SG_ 1169 EgyMeasIntlIntl4 0;
BA_ "GenSigSendType" SG_ 1169 EgyMeasSec 0;
BA_ "GenSigSendType" SG_ 666 EldtPmpPwrCns 0;
BA_ "GenSigSendType" SG_ 306 EmgyBrkLiIndcrTurn 0;
BA_ "GenSigStartValue" SG_ 306 EmgyBrkLiIndcrTurn 1;
BA_ "GenSigSendType" SG_ 306 ErsStrtApplSts 0;
BA_ "GenSigSendType" SG_ 666 FanPwrCns 0;
BA_ "GenSigSendType" SG_ 306 GlvBoxRelsReq 0;
BA_ "GenSigSendType" SG_ 306 HvBattHeatgReq 0;
BA_ "GenSigSendType" SG_ 369 HvConvPwrAct 0;
BA_ "GenSigSendType" SG_ 306 HvCooltWtrHeatrWtrTInIntk 0;
BA_ "GenSigStartValue" SG_ 306 HvCooltWtrHeatrWtrTInIntk 40;
BA_ "GenSigSendType" SG_ 306 HvCooltWtrHeatrWtrTInOutl 0;
BA_ "GenSigStartValue" SG_ 306 HvCooltWtrHeatrWtrTInOutl 40;
BA_ "GenSigSendType" SG_ 666 HvEgyCnsAllwdForClima 0;
BA_ "GenSigSendType" SG_ 666 HvEgyLoadFctReq 0;
BA_ "GenSigSendType" SG_ 666 HvPwrAvlForClimaEstimd 0;
BA_ "GenSigSendType" SG_ 666 HvPwrEgyPrio 0;
BA_ "GenSigSendType" SG_ 666 HvWtrHeatrPwrCnsAllwd 0;
BA_ "GenSigSendType" SG_ 666 HvahFltIndcnReq 0;
BA_ "GenSigSendType" SG_ 369 ImobRemMgrChkImobDataRemMgrChk0 0;
BA_ "GenSigSendType" SG_ 369 ImobRemMgrChkImobDataRemMgrChk1 0;
BA_ "GenSigSendType" SG_ 369 ImobRemMgrChkImobDataRemMgrChk2 0;
BA_ "GenSigSendType" SG_ 369 ImobRemMgrChkImobDataRemMgrChk3 0;
BA_ "GenSigSendType" SG_ 369 ImobRemMgrChkImobDataRemMgrChk4 0;
BA_ "GenSigSendType" SG_ 369 ImobRemMgrChkSts 0;
BA_ "GenSigSendType" SG_ 369 ImobVehRemMgrSts1ImobVehRemMgrSts 0;
BA_ "GenSigSendType" SG_ 369 ImobVehRemMgrSts1SpdLimRemMgrSts 0;
BA_ "GenSigSendType" SG_ 306 IndcrNoSeq 0;
BA_ "GenSigSendType" SG_ 306 KeyEnaStsKey0 0;
BA_ "GenSigSendType" SG_ 306 KeyEnaStsKey1 0;
BA_ "GenSigSendType" SG_ 306 KeyEnaStsKey10 0;
BA_ "GenSigSendType" SG_ 306 KeyEnaStsKey11 0;
BA_ "GenSigSendType" SG_ 306 KeyEnaStsKey2 0;
BA_ "GenSigSendType" SG_ 306 KeyEnaStsKey3 0;
BA_ "GenSigSendType" SG_ 306 KeyEnaStsKey4 0;
BA_ "GenSigSendType" SG_ 306 KeyEnaStsKey5 0;
BA_ "GenSigSendType" SG_ 306 KeyEnaStsKey6 0;
BA_ "GenSigSendType" SG_ 306 KeyEnaStsKey7 0;
BA_ "GenSigSendType" SG_ 306 KeyEnaStsKey8 0;
BA_ "GenSigSendType" SG_ 306 KeyEnaStsKey9 0;
BA_ "GenSigSendType" SG_ 336 KeyLostWarnIndcn 0;
BA_ "GenSigSendType" SG_ 336 KeyRmnIndcn 0;
BA_ "GenSigSendType" SG_ 306 KeyScanActv 0;
BA_ "GenSigSendType" SG_ 369 LnchModIndcnMsg 0;
BA_ "GenSigSendType" SG_ 369 LockgFbAcoustReq 0;
BA_ "GenSigSendType" SG_ 336 LockgFbAudioReq 0;
BA_ "GenSigSendType" SG_ 369 LockgFbToExtLi 0;
BA_ "GenSigSendType" SG_ 336 MemBtnPsdMemBtn1 1;
BA_ "GenSigSendType" SG_ 336 MemBtnPsdMemBtn2 1;
BA_ "GenSigSendType" SG_ 336 MemBtnPsdMemBtn3 1;
BA_ "GenSigSendType" SG_ 336 MemBtnPsdMemButM 1;
BA_ "GenSigSendType" SG_ 666 MirrActvBtn 0;
BA_ "GenSigSendType" SG_ 666 MirrCmdAtDrvrMirrDwnCmd 0;
BA_ "GenSigSendType" SG_ 666 MirrCmdAtDrvrMirrFoldCmd 0;
BA_ "GenSigSendType" SG_ 666 MirrCmdAtDrvrMirrPosAdjCmd 0;
BA_ "GenSigSendType" SG_ 666 MirrDefrstAtDrvSts 0;
BA_ "GenSigSendType" SG_ 306 MirrDefrstAtPassCmd 0;
BA_ "GenSigSendType" SG_ 666 MirrDirReq 0;
BA_ "GenSigSendType" SG_ 306 MirrDwnStsAtDrvr 0;
BA_ "GenSigSendType" SG_ 666 MirrPosnAdjFromSetTarPosnDrvrMirrPosnAdjCldLeRi 0;
BA_ "GenSigSendType" SG_ 666 MirrPosnAdjFromSetTarPosnDrvrMirrPosnAdjCldUpDwn 0;
BA_ "GenSigSendType" SG_ 306 MirrPosnAdjFromSetTarPosnPassMirrPosnAdjCldLeRi 0;
BA_ "GenSigSendType" SG_ 306 MirrPosnAdjFromSetTarPosnPassMirrPosnAdjCldUpDwn 0;
BA_ "GenSigSendType" SG_ 666 MirrSelnReq 0;
BA_ "GenSigSendType" SG_ 369 MobDevVentReq 0;
BA_ "GenSigSendType" SG_ 666 MotGenDrvCyc 0;
BA_ "GenSigSendType" SG_ 293 MusicInfoSeg11SegFftLiShow1 0;
BA_ "GenSigSendType" SG_ 293 MusicInfoSeg11SegFftLiShow10 0;
BA_ "GenSigSendType" SG_ 293 MusicInfoSeg11SegFftLiShow11 0;
BA_ "GenSigSendType" SG_ 293 MusicInfoSeg11SegFftLiShow12 0;
BA_ "GenSigSendType" SG_ 293 MusicInfoSeg11SegFftLiShow13 0;
BA_ "GenSigSendType" SG_ 293 MusicInfoSeg11SegFftLiShow14 0;
BA_ "GenSigSendType" SG_ 293 MusicInfoSeg11SegFftLiShow2 0;
BA_ "GenSigSendType" SG_ 293 MusicInfoSeg11SegFftLiShow3 0;
BA_ "GenSigSendType" SG_ 293 MusicInfoSeg11SegFftLiShow4 0;
BA_ "GenSigSendType" SG_ 293 MusicInfoSeg11SegFftLiShow5 0;
BA_ "GenSigSendType" SG_ 293 MusicInfoSeg11SegFftLiShow6 0;
BA_ "GenSigSendType" SG_ 293 MusicInfoSeg11SegFftLiShow7 0;
BA_ "GenSigSendType" SG_ 293 MusicInfoSeg11SegFftLiShow8 0;
BA_ "GenSigSendType" SG_ 293 MusicInfoSeg11SegFftLiShow9 0;
BA_ "GenSigSendType" SG_ 293 MusicInfoSeg11TimeFlagMessage 0;
BA_ "GenSigSendType" SG_ 293 MusicInfoSeg11TimeFlagMusicplay 0;
BA_ "GenSigSendType" SG_ 293 MusicInfoSeg12SegFftLiShow15 0;
BA_ "GenSigSendType" SG_ 293 MusicInfoSeg12SegFftLiShow16 0;
BA_ "GenSigSendType" SG_ 293 MusicInfoSeg12SegFftLiShow17 0;
BA_ "GenSigSendType" SG_ 293 MusicInfoSeg12SegFftLiShow18 0;
BA_ "GenSigSendType" SG_ 293 MusicInfoSeg12SegFftLiShow19 0;
BA_ "GenSigSendType" SG_ 293 MusicInfoSeg12SegFftLiShow20 0;
BA_ "GenSigSendType" SG_ 293 MusicInfoSeg12SegFftLiShow21 0;
BA_ "GenSigSendType" SG_ 293 MusicInfoSeg12SegFftLiShow22 0;
BA_ "GenSigSendType" SG_ 293 MusicInfoSeg12SegFftLiShow23 0;
BA_ "GenSigSendType" SG_ 293 MusicInfoSeg12SegFftLiShow24 0;
BA_ "GenSigSendType" SG_ 293 MusicInfoSeg12SegFftLiShow25 0;
BA_ "GenSigSendType" SG_ 293 MusicInfoSeg12SegFftLiShow26 0;
BA_ "GenSigSendType" SG_ 293 MusicInfoSeg12SegFftLiShow27 0;
BA_ "GenSigSendType" SG_ 293 MusicInfoSeg12SegFftLiShow28 0;
BA_ "GenSigSendType" SG_ 293 MusicInfoSeg12TimeFlagMessage 0;
BA_ "GenSigSendType" SG_ 293 MusicInfoSeg12TimeFlagMusicplay 0;
BA_ "GenSigSendType" SG_ 293 MusicInfoSeg13DownSamplingAmplitude 0;
BA_ "GenSigSendType" SG_ 293 MusicInfoSeg13MaxFFT100ms3kAmplitude 0;
BA_ "GenSigSendType" SG_ 293 MusicInfoSeg13MaxFFT100ms3kFrequency 0;
BA_ "GenSigSendType" SG_ 293 MusicInfoSeg13SegFftLiShow29 0;
BA_ "GenSigSendType" SG_ 293 MusicInfoSeg13SegFftLiShow30 0;
BA_ "GenSigSendType" SG_ 293 MusicInfoSeg13SegFftLiShow31 0;
BA_ "GenSigSendType" SG_ 293 MusicInfoSeg13StateFlagMusicPlay 0;
BA_ "GenSigSendType" SG_ 293 MusicInfoSeg13StateFlagNewMusic 0;
BA_ "GenSigSendType" SG_ 293 MusicInfoSeg13TimeFlagMessage 0;
BA_ "GenSigSendType" SG_ 293 MusicInfoSeg13TimeFlagMusicplay 0;
BA_ "GenSigSendType" SG_ 293 MusicInfoSeg21SegFftLiShow1 0;
BA_ "GenSigSendType" SG_ 293 MusicInfoSeg21SegFftLiShow10 0;
BA_ "GenSigSendType" SG_ 293 MusicInfoSeg21SegFftLiShow11 0;
BA_ "GenSigSendType" SG_ 293 MusicInfoSeg21SegFftLiShow12 0;
BA_ "GenSigSendType" SG_ 293 MusicInfoSeg21SegFftLiShow13 0;
BA_ "GenSigSendType" SG_ 293 MusicInfoSeg21SegFftLiShow14 0;
BA_ "GenSigSendType" SG_ 293 MusicInfoSeg21SegFftLiShow2 0;
BA_ "GenSigSendType" SG_ 293 MusicInfoSeg21SegFftLiShow3 0;
BA_ "GenSigSendType" SG_ 293 MusicInfoSeg21SegFftLiShow4 0;
BA_ "GenSigSendType" SG_ 293 MusicInfoSeg21SegFftLiShow5 0;
BA_ "GenSigSendType" SG_ 293 MusicInfoSeg21SegFftLiShow6 0;
BA_ "GenSigSendType" SG_ 293 MusicInfoSeg21SegFftLiShow7 0;
BA_ "GenSigSendType" SG_ 293 MusicInfoSeg21SegFftLiShow8 0;
BA_ "GenSigSendType" SG_ 293 MusicInfoSeg21SegFftLiShow9 0;
BA_ "GenSigSendType" SG_ 293 MusicInfoSeg21TimeFlagMessage 0;
BA_ "GenSigSendType" SG_ 293 MusicInfoSeg21TimeFlagMusicplay 0;
BA_ "GenSigSendType" SG_ 293 MusicInfoSeg22SegFftLiShow15 0;
BA_ "GenSigSendType" SG_ 293 MusicInfoSeg22SegFftLiShow16 0;
BA_ "GenSigSendType" SG_ 293 MusicInfoSeg22SegFftLiShow17 0;
BA_ "GenSigSendType" SG_ 293 MusicInfoSeg22SegFftLiShow18 0;
BA_ "GenSigSendType" SG_ 293 MusicInfoSeg22SegFftLiShow19 0;
BA_ "GenSigSendType" SG_ 293 MusicInfoSeg22SegFftLiShow20 0;
BA_ "GenSigSendType" SG_ 293 MusicInfoSeg22SegFftLiShow21 0;
BA_ "GenSigSendType" SG_ 293 MusicInfoSeg22SegFftLiShow22 0;
BA_ "GenSigSendType" SG_ 293 MusicInfoSeg22SegFftLiShow23 0;
BA_ "GenSigSendType" SG_ 293 MusicInfoSeg22SegFftLiShow24 0;
BA_ "GenSigSendType" SG_ 293 MusicInfoSeg22SegFftLiShow25 0;
BA_ "GenSigSendType" SG_ 293 MusicInfoSeg22SegFftLiShow26 0;
BA_ "GenSigSendType" SG_ 293 MusicInfoSeg22SegFftLiShow27 0;
BA_ "GenSigSendType" SG_ 293 MusicInfoSeg22SegFftLiShow28 0;
BA_ "GenSigSendType" SG_ 293 MusicInfoSeg22TimeFlagMessage 0;
BA_ "GenSigSendType" SG_ 293 MusicInfoSeg22TimeFlagMusicplay 0;
BA_ "GenSigSendType" SG_ 293 MusicInfoSeg23DownSamplingAmplitude 0;
BA_ "GenSigSendType" SG_ 293 MusicInfoSeg23MaxFFT100ms3kAmplitude 0;
BA_ "GenSigSendType" SG_ 293 MusicInfoSeg23MaxFFT100ms3kFrequency 0;
BA_ "GenSigSendType" SG_ 293 MusicInfoSeg23SegFftLiShow29 0;
BA_ "GenSigSendType" SG_ 293 MusicInfoSeg23SegFftLiShow30 0;
BA_ "GenSigSendType" SG_ 293 MusicInfoSeg23SegFftLiShow31 0;
BA_ "GenSigSendType" SG_ 293 MusicInfoSeg23StateFlagMusicPlay 0;
BA_ "GenSigSendType" SG_ 293 MusicInfoSeg23StateFlagNewMusic 0;
BA_ "GenSigSendType" SG_ 293 MusicInfoSeg23TimeFlagMessage 0;
BA_ "GenSigSendType" SG_ 293 MusicInfoSeg23TimeFlagMusicplay 0;
BA_ "GenSigSendType" SG_ 369 OpenClsCmftReqOpenClsCmftReq 0;
BA_ "GenSigSendType" SG_ 369 OpenClsCmftReqOpenClsCmftTrigSrc 0;
BA_ "GenSigSendType" SG_ 369 PassMidSeatSts 0;
BA_ "GenSigSendType" SG_ 306 PedProtnMsgReqForFlt 0;
BA_ "GenSigSendType" SG_ 306 PedProtnMsgReqForImpct 0;
BA_ "GenSigSendType" SG_ 293 PrkgLiShowSwt 0;
BA_ "GenSigSendType" SG_ 369 PwrCnsAvgIndcdPwrCns1 0;
BA_ "GenSigStartValue" SG_ 369 PwrCnsAvgIndcdPwrCns1 1023;
BA_ "GenSigSendType" SG_ 369 PwrCnsAvgIndcdPwrCns2 0;
BA_ "GenSigStartValue" SG_ 369 PwrCnsAvgIndcdPwrCns2 1023;
BA_ "GenSigSendType" SG_ 369 PwrCnsAvgIndcdPwrCns3 0;
BA_ "GenSigStartValue" SG_ 369 PwrCnsAvgIndcdPwrCns3 1023;
BA_ "GenSigSendType" SG_ 369 PwrCnsIndcdPwrCnsIn1 0;
BA_ "GenSigStartValue" SG_ 369 PwrCnsIndcdPwrCnsIn1 1000;
BA_ "GenSigSendType" SG_ 369 RainDetected 0;
BA_ "GenSigSendType" SG_ 306 RegenAutLvlNotAvlMsg 0;
BA_ "GenSigSendType" SG_ 369 RemAllowStrt 0;
BA_ "GenSigSendType" SG_ 306 RestrntSysLampReq 0;
BA_ "GenSigSendType" SG_ 306 RestrntSysMsgReq 0;
BA_ "GenSigStartValue" SG_ 306 RestrntSysMsgReq 1;
BA_ "GenSigStartValue" SG_ 666 RoadSlopeInst 10000;
BA_ "GenSigSendType" SG_ 369 SeatOccptAtRowFrthLe 0;
BA_ "GenSigSendType" SG_ 369 SeatOccptAtRowFrthMid 0;
BA_ "GenSigSendType" SG_ 369 SeatOccptAtRowFrthRi 0;
BA_ "GenSigSendType" SG_ 369 SeatOccptAtRowThrdMid 0;
BA_ "GenSigSendType" SG_ 369 ShortDropWinLeReDoor2 0;
BA_ "GenSigSendType" SG_ 369 ShortDropWinPassDoor2 0;
BA_ "GenSigSendType" SG_ 369 ShortDropWinRiReDoor2 0;
BA_ "GenSigSendType" SG_ 306 SnowFlg 0;
BA_ "GenSigSendType" SG_ 306 SteerServoSts 0;
BA_ "GenSigSendType" SG_ 369 SunCurtPosnSts 0;
BA_ "GenSigStartValue" SG_ 306 TCSTNowSts 255;
BA_ "GenSigSendType" SG_ 369 TankFlapLockgCmd 0;
BA_ "GenSigSendType" SG_ 369 ThmEgyDistbn 0;
BA_ "GenSigSendType" SG_ 306 TopPosHmiFeedBack 0;
BA_ "GenSigSendType" SG_ 306 TopPosHmiFeedBack2 0;
BA_ "GenSigStartValue" SG_ 306 TopPosHmiFeedBack2 95;
BA_ "GenSigSendType" SG_ 369 TotDrvPwrAct 0;
BA_ "GenSigStartValue" SG_ 369 TotDrvPwrAct 1000;
BA_ "GenSigSendType" SG_ 369 TrHndlOutdOpenSts 0;
BA_ "GenSigSendType" SG_ 306 TrOpenPosn 0;
BA_ "GenSigStartValue" SG_ 306 TrOpenPosn 101;
BA_ "GenSigSendType" SG_ 306 TrOpenerSts 0;
BA_ "GenSigSendType" SG_ 666 TrlrModPrpsnSts 0;
BA_ "GenSigSendType" SG_ 306 VehActvMsgToDrvr 0;
BA_ "GenSigSendType" SG_ 1288 WakeUpReasonsforDHU 0;
BA_ "GenSigSendType" SG_ 1378 ZCUDMDevpFrameForDebugFunctiondevpsignalgroup1 1;
BA_ "GenSigSendType" SG_ 1378 ZCUDMDevpFrameForDebugFunctiondevpsignalgroup2 1;
BA_ "GenSigSendType" SG_ 1378 ZCUDMDevpFrameForDebugFunctiondevpsignalgroup3 1;
BA_ "GenSigSendType" SG_ 1378 ZCUDMDevpFrameForDebugFunctiondevpsignalgroup4 1;
BA_ "GenSigSendType" SG_ 1378 ZCUDMDevpFrameForDebugFunctiondevpsignalgroup5 1;
BA_ "GenSigSendType" SG_ 1378 ZCUDMDevpFrameForDebugFunctiondevpsignalgroup6 1;
BA_ "GenSigSendType" SG_ 1378 ZCUDMDevpFrameForDebugFunctiondevpsignalgroup7 1;
BA_ "GenSigSendType" SG_ 1378 ZCUDMDevpFrameForDebugFunctiondevpsignalgroup8 1;
BA_ "GenSigSendType" SG_ 1377 ZCUDMdevelpsignalgroupReqFunctiondevpsignalgroup1 1;
BA_ "GenSigSendType" SG_ 1377 ZCUDMdevelpsignalgroupReqFunctiondevpsignalgroup2 1;
BA_ "GenSigSendType" SG_ 1377 ZCUDMdevelpsignalgroupReqFunctiondevpsignalgroup3 1;
BA_ "GenSigSendType" SG_ 1377 ZCUDMdevelpsignalgroupReqFunctiondevpsignalgroup4 1;
BA_ "GenSigSendType" SG_ 1377 ZCUDMdevelpsignalgroupReqFunctiondevpsignalgroup5 1;
BA_ "GenSigSendType" SG_ 1377 ZCUDMdevelpsignalgroupReqFunctiondevpsignalgroup6 1;
BA_ "GenSigSendType" SG_ 1377 ZCUDMdevelpsignalgroupReqFunctiondevpsignalgroup7 1;
BA_ "GenSigSendType" SG_ 1377 ZCUDMdevelpsignalgroupReqFunctiondevpsignalgroup8 1;
BA_ "GenSigSendType" SG_ 1378 ZCUDMdevelpsignalgroupRespFunctiondevpsignalgroup1 1;
BA_ "GenSigSendType" SG_ 1378 ZCUDMdevelpsignalgroupRespFunctiondevpsignalgroup2 1;
BA_ "GenSigSendType" SG_ 1378 ZCUDMdevelpsignalgroupRespFunctiondevpsignalgroup3 1;
BA_ "GenSigSendType" SG_ 1378 ZCUDMdevelpsignalgroupRespFunctiondevpsignalgroup4 1;
BA_ "GenSigSendType" SG_ 1378 ZCUDMdevelpsignalgroupRespFunctiondevpsignalgroup5 1;
BA_ "GenSigSendType" SG_ 1378 ZCUDMdevelpsignalgroupRespFunctiondevpsignalgroup6 1;
BA_ "GenSigSendType" SG_ 1378 ZCUDMdevelpsignalgroupRespFunctiondevpsignalgroup7 1;
BA_ "GenSigSendType" SG_ 1378 ZCUDMdevelpsignalgroupRespFunctiondevpsignalgroup8 1;
BA_ "GenSigSendType" SG_ 1377 ZCUPdevelpsignalgroupReqFunctiondevpsignalgroup1 1;
BA_ "GenSigSendType" SG_ 1377 ZCUPdevelpsignalgroupReqFunctiondevpsignalgroup2 1;
BA_ "GenSigSendType" SG_ 1377 ZCUPdevelpsignalgroupReqFunctiondevpsignalgroup3 1;
BA_ "GenSigSendType" SG_ 1377 ZCUPdevelpsignalgroupReqFunctiondevpsignalgroup4 1;
BA_ "GenSigSendType" SG_ 1377 ZCUPdevelpsignalgroupReqFunctiondevpsignalgroup5 1;
BA_ "GenSigSendType" SG_ 1377 ZCUPdevelpsignalgroupReqFunctiondevpsignalgroup6 1;
BA_ "GenSigSendType" SG_ 1377 ZCUPdevelpsignalgroupReqFunctiondevpsignalgroup7 1;
BA_ "GenSigSendType" SG_ 1377 ZCUPdevelpsignalgroupReqFunctiondevpsignalgroup8 1;
VAL_ 293 DrvModReqForChampnMod 0 "SteerMod_Ukwn" 1 "SteerMod_Mod1" 2 "SteerMod_Mod2" 3 "SteerMod_Mod3" 4 "SteerMod_Mod4" 5 "SteerMod_Resd5" 6 "SteerMod_Resd6" 7 "SteerMod_Resd7";
VAL_ 293 MusicInfoSeg13StateFlagMusicPlay 0 "Boolean_FALSE" 1 "Boolean_TRUE";
VAL_ 293 MusicInfoSeg13StateFlagNewMusic 0 "Boolean_FALSE" 1 "Boolean_TRUE";
VAL_ 293 MusicInfoSeg23StateFlagMusicPlay 0 "Boolean_FALSE" 1 "Boolean_TRUE";
VAL_ 293 MusicInfoSeg23StateFlagNewMusic 0 "Boolean_FALSE" 1 "Boolean_TRUE";
VAL_ 293 PrkgLiShowSwt 0 "PrkgLiShowSwt_NoReq" 1 "PrkgLiShowSwt_Static" 2 "PrkgLiShowSwt_Dynamic" 3 "PrkgLiShowSwt_Off";
VAL_ 1288 WakeUpReasonsforDHU 0 "WakeupReasons_667949" 1 "WakeupReasons_667950" 2 "WakeupReasons_169654" 3 "WakeupReasons_667951" 4 "WakeupReasons_168965" 5 "WakeupReasons_197643" 6 "WakeupReasons_264933" 7 "WakeupReasons_45654" 8 "WakeupReasons_22058" 9 "WakeupReasons_49446" 10 "WakeupReasons_22060" 11 "WakeupReasons_269740" 12 "WakeupReasons_269735" 13 "WakeupReasons_269739" 14 "WakeupReasons_658500" 15 "WakeupReasons_21901" 16 "WakeupReasons_45793" 17 "WakeupReasons_45794" 18 "WakeupReasons_22005" 19 "WakeupReasons_22013" 20 "WakeupReasons_22100" 21 "WakeupReasons_45659" 22 "WakeupReasons_45657" 23 "WakeupReasons_140084" 24 "WakeupReasons_21973" 25 "WakeupReasons_91253" 26 "WakeupReasons_88123" 27 "WakeupReasons_88125" 28 "WakeupReasons_321583" 29 "WakeupReasons_74188" 30 "WakeupReasons_667945" 31 "WakeupReasons_169655" 32 "WakeupReasons_667948" 33 "WakeupReasons_168966" 34 "WakeupReasons_170865" 35 "WakeupReasons_197642" 36 "WakeupReasons_264876" 37 "WakeupReasons_191050" 38 "WakeupReasons_182033" 39 "WakeupReasons_200937" 40 "WakeupReasons_170807" 41 "WakeupReasons_319139" 42 "WakeupReasons_100298" 43 "WakeupReasons_100275" 44 "WakeupReasons_100300" 45 "WakeupReasons_100278" 46 "WakeupReasons_100281" 47 "WakeupReasons_265333" 48 "WakeupReasons_108776" 49 "WakeupReasons_176921" 50 "WakeupReasons_197826" 51 "WakeupReasons_185670" 52 "WakeupReasons_161066" 53 "WakeupReasons_200156" 54 "WakeupReasons_225696" 55 "WakeupReasons_21997" 56 "WakeupReasons_45656" 57 "WakeupReasons_266860" 58 "WakeupReasons_169894" 59 "WakeupReasons_320282" 60 "WakeupReasons_319422" 61 "WakeupReasons_320277" 62 "WakeupReasons_355601" 63 "WakeupReasons_360904" 64 "WakeupReasons_361505" 65 "WakeupReasons_361509" 66 "WakeupReasons_645094" 67 "WakeupReasons_68676" 68 "WakeupReasons_360008" 69 "WakeupReasons_109382" 70 "WakeupReasons_119273" 71 "WakeupReasons_224065" 72 "WakeupReasons_68644" 73 "WakeupReasons_109364" 74 "WakeupReasons_68481" 75 "WakeupReasons_224061" 76 "WakeupReasons_360006" 77 "WakeupReasons_138997" 78 "WakeupReasons_634696" 79 "WakeupReasons_645810" 80 "WakeupReasons_297868" 81 "WakeupReasons_315364" 82 "WakeupReasons_109367" 83 "WakeupReasons_320126" 84 "WakeupReasons_109387" 85 "WakeupReasons_634710" 86 "WakeupReasons_338820" 87 "WakeupReasons_67182" 88 "WakeupReasons_152237" 89 "WakeupReasons_145707" 90 "WakeupReasons_199172" 91 "WakeupReasons_144897" 92 "WakeupReasons_186489" 93 "WakeupReasons_144970" 94 "WakeupReasons_152786" 95 "WakeupReasons_264932" 96 "WakeupReasons_264934" 97 "WakeupReasons_356190" 98 "WakeupReasons_145688" 99 "WakeupReasons_95444" 100 "WakeupReasons_169945" 101 "WakeupReasons_140678" 102 "WakeupReasons_222553" 103 "WakeupReasons_224831" 104 "WakeupReasons_201815" 105 "WakeupReasons_45864" 106 "WakeupReasons_659549" 107 "WakeupReasons_45866" 108 "WakeupReasons_45867" 109 "WakeupReasons_169884" 110 "WakeupReasons_264962" 111 "WakeupReasons_201348" 112 "WakeupReasons_320287" 113 "WakeupReasons_156412" 114 "WakeupReasons_133749" 115 "WakeupReasons_355409" 116 "WakeupReasons_636692" 117 "WakeupReasons_533044" 118 "WakeupReasons_106774" 119 "WakeupReasons_145311" 120 "WakeupReasons_145319" 121 "WakeupReasons_152774" 122 "WakeupReasons_145330" 123 "WakeupReasons_145388" 124 "WakeupReasons_145399" 125 "WakeupReasons_145362" 126 "WakeupReasons_145385" 127 "WakeupReasons_145373" 128 "WakeupReasons_145288" 129 "WakeupReasons_145419" 130 "WakeupReasons_145454" 131 "WakeupReasons_145462" 132 "WakeupReasons_269156" 133 "WakeupReasons_300427" 134 "WakeupReasons_220322" 135 "WakeupReasons_224617" 136 "WakeupReasons_224634" 137 "WakeupReasons_300682" 138 "WakeupReasons_264958" 139 "WakeupReasons_160597" 140 "WakeupReasons_160602" 141 "WakeupReasons_108841" 142 "WakeupReasons_265569" 143 "WakeupReasons_526429" 144 "WakeupReasons_514545" 145 "WakeupReasons_265232" 146 "WakeupReasons_644550" 147 "WakeupReasons_317616" 148 "WakeupReasons_354791" 149 "WakeupReasons_320631" 150 "WakeupReasons_337565" 151 "WakeupReasons_532007" 152 "WakeupReasons_514503" 153 "WakeupReasons_299117" 154 "WakeupReasons_340667" 155 "WakeupReasons_321845" 156 "WakeupReasons_179103" 157 "WakeupReasons_108810" 158 "WakeupReasons_322857" 159 "WakeupReasons_658603" 160 "WakeupReasons_197648" 161 "WakeupReasons_160596" 162 "WakeupReasons_361272" 163 "WakeupReasons_361279" 164 "WakeupReasons_265305" 165 "WakeupReasons_265328" 166 "WakeupReasons_265330" 167 "WakeupReasons_298808" 168 "WakeupReasons_515804" 169 "WakeupReasons_514502" 170 "WakeupReasons_645753" 171 "WakeupReasons_646109" 172 "WakeupReasons_299547" 173 "WakeupReasons_318342" 174 "WakeupReasons_360543" 175 "WakeupReasons_356549" 176 "WakeupReasons_198484" 177 "WakeupReasons_300681" 178 "WakeupReasons_359211" 179 "WakeupReasons_534077" 180 "WakeupReasons_525705" 181 "WakeupReasons_360299" 182 "WakeupReasons_526445" 183 "WakeupReasons_534145" 184 "WakeupReasons_192030" 185 "WakeupReasons_652361" 186 "WakeupReasons_355214" 187 "WakeupReasons_321317" 188 "WakeupReasons_359187" 189 "WakeupReasons_321057" 190 "WakeupReasons_321319" 191 "WakeupReasons_321323" 192 "WakeupReasons_321077" 193 "WakeupReasons_320895" 194 "WakeupReasons_655340" 195 "WakeupReasons_636556" 196 "WakeupReasons_108834" 197 "WakeupReasons_265937" 198 "WakeupReasons_533050" 199 "WakeupReasons_526426" 200 "WakeupReasons_264712" 201 "WakeupReasons_319401" 202 "WakeupReasons_643973" 203 "WakeupReasons_223715" 204 "WakeupReasons_199159" 205 "WakeupReasons_318382" 206 "WakeupReasons_226967" 207 "WakeupReasons_531743" 208 "WakeupReasons_360542" 209 "WakeupReasons_264726" 210 "WakeupReasons_535214" 211 "WakeupReasons_335068" 212 "WakeupReasons_316796" 213 "WakeupReasons_526438" 214 "WakeupReasons_198433" 215 "WakeupReasons_225961" 216 "WakeupReasons_197665" 217 "WakeupReasons_224550" 218 "WakeupReasons_667962" 219 "WakeupReasons_667953" 220 "WakeupReasons_110885" 221 "WakeupReasons_224552" 222 "WakeupReasons_224553" 223 "WakeupReasons_652546" 224 "WakeupReasons_331194" 225 "WakeupReasons_667820" 226 "WakeupReasons_659350" 227 "WakeupReasons_101706" 228 "WakeupReasons_101725" 229 "WakeupReasons_101728" 230 "WakeupReasons_101727" 231 "WakeupReasons_166267" 232 "WakeupReasons_156440" 233 "WakeupReasons_95949" 234 "WakeupReasons_112799" 235 "WakeupReasons_146470" 236 "WakeupReasons_176748" 237 "WakeupReasons_223920" 238 "WakeupReasons_668531" 239 "WakeupReasons_670087" 240 "WakeupReasons_668529" 241 "WakeupReasons_45858" 242 "WakeupReasons_315981" 243 "WakeupReasons_533370" 244 "WakeupReasons_533371" 245 "WakeupReasons_533372" 246 "WakeupReasons_241902" 247 "WakeupReasons_359559" 248 "WakeupReasons_516327" 249 "WakeupReasons_533872" 250 "WakeupReasons_45856" 251 "WakeupReasons_45853" 252 "WakeupReasons_45854" 253 "WakeupReasons_45852" 254 "WakeupReasons_45851" 255 "WakeupReasons_45850" 256 "WakeupReasons_45849" 257 "WakeupReasons_636801" 258 "WakeupReasons_109466" 259 "WakeupReasons_109467" 260 "WakeupReasons_670345" 261 "WakeupReasons_NMPDUReceived" 262 "WakeupReasons_358832" 263 "WakeupReasons_200683" 264 "WakeupReasons_198452" 265 "WakeupReasons_185457" 266 "WakeupReasons_185490" 267 "WakeupReasons_4471" 268 "WakeupReasons_269034" 269 "WakeupReasons_215560" 270 "WakeupReasons_312881" 271 "WakeupReasons_269140" 272 "WakeupReasons_197653" 273 "WakeupReasons_337991" 274 "WakeupReasons_658188" 275 "WakeupReasons_674953" 276 "WakeupReasons_675064" 277 "WakeupReasons_674958" 278 "WakeupReasons_675494" 279 "WakeupReasons_675837" 280 "WakeupReasons_667879" 281 "WakeupReasons_667947" 282 "WakeupReasons_676265" 283 "WakeupReasons_669465" 284 "WakeupReasons_670928" 285 "WakeupReasons_669447" 286 "WakeupReasons_667922" 287 "WakeupReasons_670753" 288 "WakeupReasons_668395" 289 "WakeupReasons_668393" 290 "WakeupReasons_667850" 291 "WakeupReasons_667848" 292 "WakeupReasons_311279" 293 "WakeupReasons_182918" 294 "WakeupReasons_667988" 295 "WakeupReasons_532555" 296 "WakeupReasons_532556" 297 "WakeupReasons_113348" 298 "WakeupReasons_193474" 299 "WakeupReasons_667871" 300 "WakeupReasons_670966" 301 "WakeupReasons_667985" 302 "WakeupReasons_670354" 303 "WakeupReasons_46017" 304 "WakeupReasons_675742" 305 "WakeupReasons_106669" 306 "WakeupReasons_80609" 307 "WakeupReasons_199714" 308 "WakeupReasons_200090" 309 "WakeupReasons_139075" 310 "WakeupReasons_268983" 311 "WakeupReasons_265131" 312 "WakeupReasons_263473" 313 "WakeupReasons_45887" 314 "WakeupReasons_69678" 315 "WakeupReasons_69679" 316 "WakeupReasons_45897" 317 "WakeupReasons_45898" 318 "WakeupReasons_80608" 319 "WakeupReasons_45869" 320 "WakeupReasons_45870" 321 "WakeupReasons_45872" 322 "WakeupReasons_45875" 323 "WakeupReasons_45871" 324 "WakeupReasons_45876" 325 "WakeupReasons_667980" 326 "WakeupReasons_45877" 327 "WakeupReasons_667973" 328 "WakeupReasons_670962" 329 "WakeupReasons_45888" 330 "WakeupReasons_45890" 331 "WakeupReasons_667869" 332 "WakeupReasons_45846" 333 "WakeupReasons_45847" 334 "WakeupReasons_45848" 335 "WakeupReasons_262872" 336 "WakeupReasons_127924" 337 "WakeupReasons_127926" 338 "WakeupReasons_674223" 339 "WakeupReasons_667982" 340 "WakeupReasons_657121" 341 "WakeupReasons_265745" 342 "WakeupReasons_657120" 343 "WakeupReasons_675564" 344 "WakeupReasons_197644" 345 "WakeupReasons_264943" 346 "WakeupReasons_264697" 347 "WakeupReasons_69216" 348 "WakeupReasons_128671" 349 "WakeupReasons_356598" 350 "WakeupReasons_675745" 351 "WakeupReasons_667983" 352 "WakeupReasons_667987" 353 "WakeupReasons_75103" 354 "WakeupReasons_305818" 355 "WakeupReasons_670942" 356 "WakeupReasons_532932" 357 "WakeupReasons_532933" 358 "WakeupReasons_83199" 359 "WakeupReasons_45900" 360 "WakeupReasons_88458" 361 "WakeupReasons_329457" 362 "WakeupReasons_45902" 363 "WakeupReasons_224211" 364 "WakeupReasons_667981" 365 "WakeupReasons_667874" 366 "WakeupReasons_46020" 367 "WakeupReasons_667842" 368 "WakeupReasons_145161" 369 "WakeupReasons_233755" 370 "WakeupReasons_297056" 371 "WakeupReasons_264691" 372 "WakeupReasons_262871" 373 "WakeupReasons_264964" 374 "WakeupReasons_667872" 375 "WakeupReasons_45655" 376 "WakeupReasons_177214" 377 "WakeupReasons_671005" 378 "WakeupReasons_680712" 379 "WakeupReasons_669822" 380 "WakeupReasons_668523" 381 "WakeupReasons_680974" 382 "WakeupReasons_680975" 383 "WakeupReasons_681028" 384 "WakeupReasons_670462" 385 "WakeupReasons_681134" 386 "WakeupReasons_681031" 387 "WakeupReasons_681711" 388 "WakeupReasons_682034" 389 "WakeupReasons_674839" 390 "WakeupReasons_681915" 391 "WakeupReasons_682032" 392 "WakeupReasons_682037" 393 "WakeupReasons_682688" 394 "WakeupReasons_681789" 395 "WakeupReasons_682023" 396 "WakeupReasons_681023" 397 "WakeupReasons_676285" 398 "WakeupReasons_682077" 399 "WakeupReasons_682076" 400 "WakeupReasons_682078" 401 "WakeupReasons_682153" 402 "WakeupReasons_682155" 403 "WakeupReasons_682152" 404 "WakeupReasons_682154" 405 "WakeupReasons_682074";
VAL_ 1169 AccrpedlStsFltSts 0 "Flt_NoFault" 1 "Flt_Fault";
VAL_ 1169 ActnOfLedHiBeam 0 "OnOff1_Off" 1 "OnOff1_On";
VAL_ 1169 ActnOfLedLoBeamActnOfLedLoBeam 0 "OnOff1_Off" 1 "OnOff1_On";
VAL_ 1169 ActvnOfWiprRe 0 "OnOff1_Off" 1 "OnOff1_On";
VAL_ 1169 AsySftyStandStillReq 0 "OnOff1_Off" 1 "OnOff1_On";
VAL_ 1169 BattSnsrCalcnNotVldRaw 0 "DevErrSts2_NoFlt" 1 "DevErrSts2_Flt";
VAL_ 1169 BattSnsrHwFltRaw 0 "DevErrSts2_NoFlt" 1 "DevErrSts2_Flt";
VAL_ 1169 CarModDispdWdDispd 0 "CarModDisp1_NoDisp" 1 "CarModDisp1_Facy" 2 "CarModDisp1_FacyStop" 3 "CarModDisp1_Trnsp" 4 "CarModDisp1_TrnspStop" 5 "CarModDisp1_Dyno" 6 "CarModDisp1_Norm" 7 "CarModDisp1_Crash";
VAL_ 1169 CarModDynoReq 1 "CarModDynoReq_Cnfrm1" 2 "CarModDynoReq_Cnfrm2" 3 "CarModDynoReq_Confg" 4 "CarModDynoReq_Dyno";
VAL_ 1169 CnvnAllwd 0 "OkNotOk_NotOk" 1 "OkNotOk_Ok";
VAL_ 1169 CnvnReq 0 "CnvnReq_NotReqd" 1 "CnvnReq_Chrgn" 2 "CnvnReq_Resd1" 3 "CnvnReq_Resd2" 4 "CnvnReq_Resd3" 5 "CnvnReq_Resd4" 6 "CnvnReq_Resd5" 7 "CnvnReq_Resd6";
VAL_ 1169 DoorDrvrSwtIntrLockgReq 0 "LockgCenReq2_Idle" 1 "LockgCenReq2_Unlck" 2 "LockgCenReq2_Lock";
VAL_ 1169 DrvrSteerWhlHldGroupDrvrSteerWhlHld 0 "OnOffDetd1_NoInfo" 1 "OnOffDetd1_OffDetd" 2 "OnOffDetd1_NotOnOrOffDetd" 3 "OnOffDetd1_OnDetd";
VAL_ 1169 ElecMot2ModReq 0 "IsgModTyp1_Inin" 1 "IsgModTyp1_Stb" 2 "IsgModTyp1_TqCtrl" 3 "IsgModTyp1_SpdCtrl" 4 "IsgModTyp1_UDcCtrl" 5 "IsgModTyp1_PreChrg" 6 "IsgModTyp1_PwrDwn" 7 "IsgModTyp1_Flt" 8 "IsgModTyp1_TcsCtrl" 9 "IsgModTyp1_Reserved1" 10 "IsgModTyp1_Reserved2" 11 "IsgModTyp1_Reserved3" 12 "IsgModTyp1_Reserved4" 13 "IsgModTyp1_Reserved5" 14 "IsgModTyp1_Reserved6" 15 "IsgModTyp1_Reserved7";
VAL_ 306 ActnOfDaytiRunngLampPass 0 "OnOff1_Off" 1 "OnOff1_On";
VAL_ 306 ActnOfFrntFogLampPass 0 "OnOff1_Off" 1 "OnOff1_On";
VAL_ 306 ActnOfFrntPosnLampPass 0 "OnOff1_Off" 1 "OnOff1_On";
VAL_ 306 ActnOfHiBeamPass 0 "OnOff1_Off" 1 "OnOff1_On";
VAL_ 306 ActnOfLoBeamPassOnOff 0 "OnOff1_Off" 1 "OnOff1_On";
VAL_ 306 ActnOfReFogLampDrv 0 "OnOff1_Off" 1 "OnOff1_On";
VAL_ 306 ActnOfRePosnLampPass 0 "OnOff1_Off" 1 "OnOff1_On";
VAL_ 306 ActnOfReRegPlateLamp 0 "OnOff1_Off" 1 "OnOff1_On";
VAL_ 306 ActnOfRvsgLampPass 0 "OnOff1_Off" 1 "OnOff1_On";
VAL_ 306 ActvnOfApproach 0 "OnOff1_Off" 1 "OnOff1_On";
VAL_ 306 ActvnOfCarLoctr 0 "OnOff1_Off" 1 "OnOff1_On";
VAL_ 306 ActvnOfGoodByeLi 0 "OnOff1_Off" 1 "OnOff1_On";
VAL_ 306 ActvnOfHndlDoorLi1HndlDoorLiDrvr 0 "ApproachLiSetReq_Off" 1 "ApproachLiSetReq_ONStatic" 2 "ApproachLiSetReq_ONDynamic";
VAL_ 306 ActvnOfHndlDoorLi1HndlDoorLiDrvrRe 0 "ApproachLiSetReq_Off" 1 "ApproachLiSetReq_ONStatic" 2 "ApproachLiSetReq_ONDynamic";
VAL_ 306 ActvnOfHndlDoorLi1HndlDoorLiPass 0 "ApproachLiSetReq_Off" 1 "ApproachLiSetReq_ONStatic" 2 "ApproachLiSetReq_ONDynamic";
VAL_ 306 ActvnOfHndlDoorLi1HndlDoorLiPassRe 0 "ApproachLiSetReq_Off" 1 "ApproachLiSetReq_ONStatic" 2 "ApproachLiSetReq_ONDynamic";
VAL_ 306 ActvnOfHomeSafe 0 "OnOff1_Off" 1 "OnOff1_On";
VAL_ 306 ActvnOfLiForComity 0 "OnOff1_Off" 1 "OnOff1_On";
VAL_ 306 ActvnOfLiForSpkr 0 "OnOff1_Off" 1 "OnOff1_On";
VAL_ 306 ActvnOfLiForWait 0 "OnOff1_Off" 1 "OnOff1_On";
VAL_ 306 ActvnOfPudLi 0 "OnOff1_Off" 1 "OnOff1_On";
VAL_ 306 ActvnOfWaitMode 0 "OnOff1_Off" 1 "OnOff1_On";
VAL_ 306 BattFltStsPrimBattFltStsPrm 0 "BattFltStsPrm_NoFlt_Default" 1 "BattFltStsPrm_QCFlt_QuiescCurrtanomaly" 2 "BattFltStsPrm_LSocFlt_LowSocfault" 3 "BattFltStsPrm_OvFlt_Overvoltagefault" 4 "BattFltStsPrm_UvFlt_Undervoltagefault" 5 "BattFltStsPrm_HiTFlt_Hightemperaturefault" 6 "BattFltStsPrm_OcFlt_Overcurrentfault" 7 "BattFltStsPrm_ScFlt_shortcircuitfault" 11 "BattFltStsPrm_ThermRunawayFlt" 13 "BattFltStsPrm_ResetActvFlg" 14 "BattFltStsPrm_WakeupActvFlg" 15 "BattFltStsPrm_RlyOpenSoonIndcn";
VAL_ 306 ChdLockLeftSts 0 "OnOffSafe1_OnOffSafeInvld1" 1 "OnOffSafe1_OnOffSafeOn" 2 "OnOffSafe1_OnOffSafeOff" 3 "OnOffSafe1_OnOffSafeInvld2";
VAL_ 306 ChdLockRightStsToHmi 0 "OnOffSafe1_OnOffSafeInvld1" 1 "OnOffSafe1_OnOffSafeOn" 2 "OnOffSafe1_OnOffSafeOff" 3 "OnOffSafe1_OnOffSafeInvld2";
VAL_ 306 ChdPrtnLeftStsToHmi 0 "OnOffSafe1_OnOffSafeInvld1" 1 "OnOffSafe1_OnOffSafeOn" 2 "OnOffSafe1_OnOffSafeOff" 3 "OnOffSafe1_OnOffSafeInvld2";
VAL_ 306 ChrgLidCombLockCmd 0 "LockActvn2_LockActvnOff" 1 "LockActvn2_LockActvnUnlck" 2 "LockActvn2_LockActvnLock" 3 "LockActvn2_LockActvnSafe" 4 "LockActvn2_LockActvnUnlckByCrash";
VAL_ 306 ChrgnLtgSts 0 "DevSts4_Off" 1 "DevSts4_On" 2 "DevSts4_Err" 3 "DevSts4_Resd";
VAL_ 306 CinhDrvrReSts 0 "PsdNotPsd1_NotPsd" 1 "PsdNotPsd1_Psd";
VAL_ 306 CinhDrvrReSwt 0 "PsdNotPsd1_NotPsd" 1 "PsdNotPsd1_Psd";
VAL_ 306 CinhDrvrSts 0 "Boolean_FALSE" 1 "Boolean_TRUE";
VAL_ 306 CinhDrvrSwt 0 "PsdNotPsd1_NotPsd" 1 "PsdNotPsd1_Psd";
VAL_ 306 DigKeyPasEntryDiSts 0 "OnOff1_Off" 1 "OnOff1_On";
VAL_ 306 DlyClsActv 0 "Boolean_FALSE" 1 "Boolean_TRUE";
VAL_ 306 DoorLeReHndlCmd 0 "DoorHndlCmd_Idle" 1 "DoorHndlCmd_Deploy" 2 "DoorHndlCmd_Retract";
VAL_ 306 DrvrGearLvrInfoIndcn 0 "BrkMsgWarn1_NoReq" 1 "BrkMsgWarn1_Msg1" 2 "BrkMsgWarn1_Msg2" 3 "BrkMsgWarn1_Msg3" 4 "BrkMsgWarn1_Msg4" 5 "BrkMsgWarn1_Msg5" 6 "BrkMsgWarn1_Msg6" 7 "BrkMsgWarn1_Msg7";
VAL_ 306 DrvrGearLvrLockIndcn 0 "DrvrGearLvrLockIndcn3_NoIndcn" 1 "DrvrGearLvrLockIndcn3_GearLvrRelsByBrkPedl" 2 "DrvrGearLvrLockIndcn3_GearLvrMovmtToManNotAllwd" 3 "DrvrGearLvrLockIndcn3_EngStrtNoPsbl" 4 "DrvrGearLvrLockIndcn3_ChgOfVehMovmtDirNotPsbl" 5 "DrvrGearLvrLockIndcn3_GearShiftSrvRqrd" 6 "DrvrGearLvrLockIndcn3_ManModActvd" 7 "DrvrGearLvrLockIndcn3_ReleaseLockButton" 8 "DrvrGearLvrLockIndcn3_GearLvrRelsByBrkPedlAndLockButton" 9 "DrvrGearLvrLockIndcn3_RetuenShifterToInitialState" 10 "DrvrGearLvrLockIndcn3_ShiftToDOrMToAllowManualMode" 11 "DrvrGearLvrLockIndcn3_StopPushingPButton" 12 "DrvrGearLvrLockIndcn3_StopPushingLockButton" 13 "DrvrGearLvrLockIndcn3_ReturnPaddleToInitialState" 14 "DrvrGearLvrLockIndcn3_PLockUnavailable";
VAL_ 306 DstTrvldVldFromSftyBkp 0 "InvldVld1_Invld" 1 "InvldVld1_Vld";
VAL_ 306 EmgyBrkLiIndcrTurn 0 "OnOffCrit1_NotVld1" 1 "OnOffCrit1_Off" 2 "OnOffCrit1_On" 3 "OnOffCrit1_NotVld2";
VAL_ 306 ErsStrtApplSts 0 "ErsStrtApplSts_ErsStsOff" 1 "ErsStrtApplSts_ErsStsStrtg" 2 "ErsStrtApplSts_ErsStsRunng";
VAL_ 306 ExtrLiShowStoreStsFrntLe 0 "OnOff1_Off" 1 "OnOff1_On";
VAL_ 306 ExtrLiShowStoreStsFrntRi 0 "OnOff1_Off" 1 "OnOff1_On";
VAL_ 306 GlvBoxRelsReq 0 "OnOff1_Off" 1 "OnOff1_On";
VAL_ 306 HvBattHeatgReq 0 "HvBattCoolgReq_NotReqd" 1 "HvBattCoolgReq_LoReq" 2 "HvBattCoolgReq_MedReq" 3 "HvBattCoolgReq_HiReq";
VAL_ 306 IndcrNoSeq 0 "OnOff1_Off" 1 "OnOff1_On";
VAL_ 306 KeyEnaStsKey0 0 "KeySts1_KeyStsIdle" 1 "KeySts1_KeyStsDi" 2 "KeySts1_KeyStsEna" 3 "KeySts1_KeyStsLimd";
VAL_ 306 KeyEnaStsKey1 0 "KeySts1_KeyStsIdle" 1 "KeySts1_KeyStsDi" 2 "KeySts1_KeyStsEna" 3 "KeySts1_KeyStsLimd";
VAL_ 306 KeyEnaStsKey10 0 "KeySts1_KeyStsIdle" 1 "KeySts1_KeyStsDi" 2 "KeySts1_KeyStsEna" 3 "KeySts1_KeyStsLimd";
VAL_ 306 KeyEnaStsKey11 0 "KeySts1_KeyStsIdle" 1 "KeySts1_KeyStsDi" 2 "KeySts1_KeyStsEna" 3 "KeySts1_KeyStsLimd";
VAL_ 306 KeyEnaStsKey2 0 "KeySts1_KeyStsIdle" 1 "KeySts1_KeyStsDi" 2 "KeySts1_KeyStsEna" 3 "KeySts1_KeyStsLimd";
VAL_ 306 KeyEnaStsKey3 0 "KeySts1_KeyStsIdle" 1 "KeySts1_KeyStsDi" 2 "KeySts1_KeyStsEna" 3 "KeySts1_KeyStsLimd";
VAL_ 306 KeyEnaStsKey4 0 "KeySts1_KeyStsIdle" 1 "KeySts1_KeyStsDi" 2 "KeySts1_KeyStsEna" 3 "KeySts1_KeyStsLimd";
VAL_ 306 KeyEnaStsKey5 0 "KeySts1_KeyStsIdle" 1 "KeySts1_KeyStsDi" 2 "KeySts1_KeyStsEna" 3 "KeySts1_KeyStsLimd";
VAL_ 306 KeyEnaStsKey6 0 "KeySts1_KeyStsIdle" 1 "KeySts1_KeyStsDi" 2 "KeySts1_KeyStsEna" 3 "KeySts1_KeyStsLimd";
VAL_ 306 KeyEnaStsKey7 0 "KeySts1_KeyStsIdle" 1 "KeySts1_KeyStsDi" 2 "KeySts1_KeyStsEna" 3 "KeySts1_KeyStsLimd";
VAL_ 306 KeyEnaStsKey8 0 "KeySts1_KeyStsIdle" 1 "KeySts1_KeyStsDi" 2 "KeySts1_KeyStsEna" 3 "KeySts1_KeyStsLimd";
VAL_ 306 KeyEnaStsKey9 0 "KeySts1_KeyStsIdle" 1 "KeySts1_KeyStsDi" 2 "KeySts1_KeyStsEna" 3 "KeySts1_KeyStsLimd";
VAL_ 306 KeyScanActv 0 "Boolean_FALSE" 1 "Boolean_TRUE";
VAL_ 306 MirrDefrstAtPassCmd 0 "OnOff1_Off" 1 "OnOff1_On";
VAL_ 306 MirrDwnStsAtDrvr 0 "MirrDwnStsTyp_MirrTiltUndefd" 1 "MirrDwnStsTyp_MirrUpPosn" 2 "MirrDwnStsTyp_MirrTiltPosn" 3 "MirrDwnStsTyp_MirrMovgToUpPosn" 4 "MirrDwnStsTyp_MirrMovgToTiltPosn";
VAL_ 306 PedProtnMsgReqForFlt 0 "OnOffCrit1_NotVld1" 1 "OnOffCrit1_Off" 2 "OnOffCrit1_On" 3 "OnOffCrit1_NotVld2";
VAL_ 306 PedProtnMsgReqForImpct 0 "OnOff1_Off" 1 "OnOff1_On";
VAL_ 306 PrpsnHvBattUsgOfChrgBlkd2 0 "HvBattUsgBlkdTyp_NotBlkd" 1 "HvBattUsgBlkdTyp_BlkdByBattLvl" 2 "HvBattUsgBlkdTyp_BlkdBySysFlt" 3 "HvBattUsgBlkdTyp_NotOfUse";
VAL_ 306 PrpsnHvBattUsgOfHldBlkd2 0 "HvBattUsgBlkdTyp_NotBlkd" 1 "HvBattUsgBlkdTyp_BlkdByBattLvl" 2 "HvBattUsgBlkdTyp_BlkdBySysFlt" 3 "HvBattUsgBlkdTyp_NotOfUse";
VAL_ 306 RegenAutLvlNotAvlMsg 0 "OnOff1_Off" 1 "OnOff1_On";
VAL_ 306 RestrntSysLampReq 0 "RestrntSysLampReq_LampOff" 1 "RestrntSysLampReq_Ukwn" 2 "RestrntSysLampReq_LampFlash" 3 "RestrntSysLampReq_LampOn";
VAL_ 306 RestrntSysMsgReq 0 "OnOffCrit1_NotVld1" 1 "OnOffCrit1_Off" 2 "OnOffCrit1_On" 3 "OnOffCrit1_NotVld2";
VAL_ 306 SeatHeatgLvlStsRowSecLe 0 "SeatClimaLvl_Off" 1 "SeatClimaLvl_Lvl1" 2 "SeatClimaLvl_Lvl2" 3 "SeatClimaLvl_Lvl3";
VAL_ 306 SeatHeatgLvlStsRowSecRi 0 "SeatClimaLvl_Off" 1 "SeatClimaLvl_Lvl1" 2 "SeatClimaLvl_Lvl2" 3 "SeatClimaLvl_Lvl3";
VAL_ 306 SeatHeatgLvlStsRowThrdLe 0 "SeatClimaLvl_Off" 1 "SeatClimaLvl_Lvl1" 2 "SeatClimaLvl_Lvl2" 3 "SeatClimaLvl_Lvl3";
VAL_ 306 SeatHeatgLvlStsRowThrdRi 0 "SeatClimaLvl_Off" 1 "SeatClimaLvl_Lvl1" 2 "SeatClimaLvl_Lvl2" 3 "SeatClimaLvl_Lvl3";
VAL_ 306 SeatRowSecLeSwtStsPassSeatSwtAdjmtOfSpplFctHozlSts 0 "SwtHozlSts1_Idle" 1 "SwtHozlSts1_Fwd" 2 "SwtHozlSts1_Backw";
VAL_ 306 SeatRowSecLeSwtStsPassSeatSwtAdjmtOfSpplFctVerSts 0 "SwtVertSts1_Idle" 1 "SwtVertSts1_Up" 2 "SwtVertSts1_Dwn";
VAL_ 306 SeatRowSecLeSwtStsPassSeatSwtHdrstHozlSts 0 "SwtHozlSts1_Idle" 1 "SwtHozlSts1_Fwd" 2 "SwtHozlSts1_Backw";
VAL_ 306 SeatRowSecLeSwtStsPassSeatSwtHdrstVertSts 0 "SwtVertSts1_Idle" 1 "SwtVertSts1_Up" 2 "SwtVertSts1_Dwn";
VAL_ 306 SeatRowSecLeSwtStsPassSeatSwtHeiFrntSts 0 "SwtVertSts1_Idle" 1 "SwtVertSts1_Up" 2 "SwtVertSts1_Dwn";
VAL_ 306 SeatRowSecLeSwtStsPassSeatSwtHeiSts 0 "SwtVertSts1_Idle" 1 "SwtVertSts1_Up" 2 "SwtVertSts1_Dwn";
VAL_ 306 SeatRowSecLeSwtStsPassSeatSwtInclSts 0 "SwtHozlSts1_Idle" 1 "SwtHozlSts1_Fwd" 2 "SwtHozlSts1_Backw";
VAL_ 306 SeatRowSecLeSwtStsPassSeatSwtSelnOfSpplFctStsSts 0 "SwtVertSts1_Idle" 1 "SwtVertSts1_Up" 2 "SwtVertSts1_Dwn";
VAL_ 306 SeatRowSecLeSwtStsPassSeatSwtSldSts 0 "SwtHozlSts1_Idle" 1 "SwtHozlSts1_Fwd" 2 "SwtHozlSts1_Backw";
VAL_ 306 SeatRowSecRiSwtStsPassSeatSwtAdjmtOfSpplFctHozlSts 0 "SwtHozlSts1_Idle" 1 "SwtHozlSts1_Fwd" 2 "SwtHozlSts1_Backw";
VAL_ 306 SeatRowSecRiSwtStsPassSeatSwtAdjmtOfSpplFctVerSts 0 "SwtVertSts1_Idle" 1 "SwtVertSts1_Up" 2 "SwtVertSts1_Dwn";
VAL_ 306 SeatRowSecRiSwtStsPassSeatSwtHdrstHozlSts 0 "SwtHozlSts1_Idle" 1 "SwtHozlSts1_Fwd" 2 "SwtHozlSts1_Backw";
VAL_ 306 SeatRowSecRiSwtStsPassSeatSwtHdrstVertSts 0 "SwtVertSts1_Idle" 1 "SwtVertSts1_Up" 2 "SwtVertSts1_Dwn";
VAL_ 306 SeatRowSecRiSwtStsPassSeatSwtHeiFrntSts 0 "SwtVertSts1_Idle" 1 "SwtVertSts1_Up" 2 "SwtVertSts1_Dwn";
VAL_ 306 SeatRowSecRiSwtStsPassSeatSwtHeiSts 0 "SwtVertSts1_Idle" 1 "SwtVertSts1_Up" 2 "SwtVertSts1_Dwn";
VAL_ 306 SeatRowSecRiSwtStsPassSeatSwtInclSts 0 "SwtHozlSts1_Idle" 1 "SwtHozlSts1_Fwd" 2 "SwtHozlSts1_Backw";
VAL_ 306 SeatRowSecRiSwtStsPassSeatSwtSelnOfSpplFctStsSts 0 "SwtVertSts1_Idle" 1 "SwtVertSts1_Up" 2 "SwtVertSts1_Dwn";
VAL_ 306 SeatRowSecRiSwtStsPassSeatSwtSldSts 0 "SwtHozlSts1_Idle" 1 "SwtHozlSts1_Fwd" 2 "SwtHozlSts1_Backw";
VAL_ 306 SeatRowThrdRiFoldRaiseWarn 0 "Boolean_FALSE" 1 "Boolean_TRUE";
VAL_ 306 SeatRowThrdRiFoldStsSeatFoldRaiseFlt 0 "Flt_NoFault" 1 "Flt_Fault";
VAL_ 306 SeatRowThrdRiFoldStsSeatFoldRaiseMovmt 0 "FoldRaiseMovmt_Uknwn" 1 "FoldRaiseMovmt_Fld" 2 "FoldRaiseMovmt_Rsd" 3 "FoldRaiseMovmt_MovmtToFld" 4 "FoldRaiseMovmt_MovmtToRsd" 5 "FoldRaiseMovmt_BtwnFldAndRsd";
VAL_ 306 SeatVentnLvlStsRowSecLe 0 "SeatClimaLvl_Off" 1 "SeatClimaLvl_Lvl1" 2 "SeatClimaLvl_Lvl2" 3 "SeatClimaLvl_Lvl3";
VAL_ 306 SeatVentnLvlStsRowSecRi 0 "SeatClimaLvl_Off" 1 "SeatClimaLvl_Lvl1" 2 "SeatClimaLvl_Lvl2" 3 "SeatClimaLvl_Lvl3";
VAL_ 306 SeatVentnLvlStsRowThrdLe 0 "SeatClimaLvl_Off" 1 "SeatClimaLvl_Lvl1" 2 "SeatClimaLvl_Lvl2" 3 "SeatClimaLvl_Lvl3";
VAL_ 306 SeatVentnLvlStsRowThrdRi 0 "SeatClimaLvl_Off" 1 "SeatClimaLvl_Lvl1" 2 "SeatClimaLvl_Lvl2" 3 "SeatClimaLvl_Lvl3";
VAL_ 306 SecRowLeHeatgAutoSts 0 "OffOnErrInvalid_Off" 1 "OffOnErrInvalid_On" 2 "OffOnErrInvalid_Err" 3 "OffOnErrInvalid_Invalid";
VAL_ 306 SecRowLeVentnAutoSts 0 "OffOnErrInvalid_Off" 1 "OffOnErrInvalid_On" 2 "OffOnErrInvalid_Err" 3 "OffOnErrInvalid_Invalid";
VAL_ 306 SecRowRiHeatgAutoSts 0 "OffOnErrInvalid_Off" 1 "OffOnErrInvalid_On" 2 "OffOnErrInvalid_Err" 3 "OffOnErrInvalid_Invalid";
VAL_ 306 SecRowRiVentnAutoSts 0 "OffOnErrInvalid_Off" 1 "OffOnErrInvalid_On" 2 "OffOnErrInvalid_Err" 3 "OffOnErrInvalid_Invalid";
VAL_ 306 SnowFlg 0 "OnOff1_Off" 1 "OnOff1_On";
VAL_ 306 SteerServoSts 0 "SteerServoSts1_SteerPwrAssidElecFullFct" 1 "SteerServoSts1_SteerPwrAssidElecCritErr";
VAL_ 306 ThrdRowLeHeatgAutoSts 0 "OffOnErrInvalid_Off" 1 "OffOnErrInvalid_On" 2 "OffOnErrInvalid_Err" 3 "OffOnErrInvalid_Invalid";
VAL_ 306 ThrdRowRiHeatgAutoSts 0 "OffOnErrInvalid_Off" 1 "OffOnErrInvalid_On" 2 "OffOnErrInvalid_Err" 3 "OffOnErrInvalid_Invalid";
VAL_ 306 TopPosHmiFeedBack 0 "TailgatePos_Unknown" 1 "TailgatePos_Fail" 2 "TailgatePos_0to20PercTopPos" 3 "TailgatePos_21to40PercTopPos" 4 "TailgatePos_41to60PercTopPos" 5 "TailgatePos_61to80PercTopPos" 6 "TailgatePos_81to100PercTopPos";
VAL_ 306 TrOpenerSts 0 "TrOpenerSts1_Ukwn" 1 "TrOpenerSts1_FullClsd" 2 "TrOpenerSts1_MovgUp" 3 "TrOpenerSts1_MovgUpBrkg" 4 "TrOpenerSts1_StopDurgOpen" 5 "TrOpenerSts1_FullOpend" 6 "TrOpenerSts1_MovgDwn" 7 "TrOpenerSts1_MovgDwnBrkg" 8 "TrOpenerSts1_StopDurgCls" 9 "TrOpenerSts1_HalfClsd" 10 "TrOpenerSts1_StopMinPntForCls";
VAL_ 306 VehActvMsgToDrvr 0 "VehActv1_NoMsg" 1 "VehActv1_Msg1" 2 "VehActv1_Msg2" 3 "VehActv1_Msg3";
VAL_ 306 VehEgyCoornDataReq 0 "ReqSts1_NotReqd" 1 "ReqSts1_Reqd";
VAL_ 369 AudWarn 0 "Boolean_FALSE" 1 "Boolean_TRUE";
VAL_ 369 AutoShowModPrpsnEna 0 "OkNotOk_NotOk" 1 "OkNotOk_Ok";
VAL_ 369 BltLockStAtPassMidBltLockEquid 0 "CptEquid_Equid" 1 "CptEquid_NotEquid";
VAL_ 369 BltLockStAtPassMidBltLockSt1 0 "BltLockSt1_Unlock" 1 "BltLockSt1_Lock";
VAL_ 369 BltLockStAtPassMidBltLockSts 0 "DevErrSts2_NoFlt" 1 "DevErrSts2_Flt";
VAL_ 369 BltLockStAtRowFrthLeBltLockEquid 0 "CptEquid_Equid" 1 "CptEquid_NotEquid";
VAL_ 369 BltLockStAtRowFrthLeBltLockSt1 0 "BltLockSt1_Unlock" 1 "BltLockSt1_Lock";
VAL_ 369 BltLockStAtRowFrthLeBltLockSts 0 "DevErrSts2_NoFlt" 1 "DevErrSts2_Flt";
VAL_ 369 BltLockStAtRowFrthMidBltLockEquid 0 "CptEquid_Equid" 1 "CptEquid_NotEquid";
VAL_ 369 BltLockStAtRowFrthMidBltLockSt1 0 "BltLockSt1_Unlock" 1 "BltLockSt1_Lock";
VAL_ 369 BltLockStAtRowFrthMidBltLockSts 0 "DevErrSts2_NoFlt" 1 "DevErrSts2_Flt";
VAL_ 369 BltLockStAtRowFrthRiBltLockEquid 0 "CptEquid_Equid" 1 "CptEquid_NotEquid";
VAL_ 369 BltLockStAtRowFrthRiBltLockSt1 0 "BltLockSt1_Unlock" 1 "BltLockSt1_Lock";
VAL_ 369 BltLockStAtRowFrthRiBltLockSts 0 "DevErrSts2_NoFlt" 1 "DevErrSts2_Flt";
VAL_ 369 BltLockStAtRowThrdMidBltLockEquid 0 "CptEquid_Equid" 1 "CptEquid_NotEquid";
VAL_ 369 BltLockStAtRowThrdMidBltLockSt1 0 "BltLockSt1_Unlock" 1 "BltLockSt1_Lock";
VAL_ 369 BltLockStAtRowThrdMidBltLockSts 0 "DevErrSts2_NoFlt" 1 "DevErrSts2_Flt";
VAL_ 369 BtnLockStsAndKeyIdBtnSts 0 "PsdNotPsd1_NotPsd" 1 "PsdNotPsd1_Psd";
VAL_ 369 BtnLockStsAndKeyIdKeyId 0 "KeyId1_Key0" 1 "KeyId1_Key1" 2 "KeyId1_Key2" 3 "KeyId1_Key3" 4 "KeyId1_Key4" 5 "KeyId1_Key5" 6 "KeyId1_Key6" 7 "KeyId1_Key7" 8 "KeyId1_Key8" 9 "KeyId1_Key9" 10 "KeyId1_Key10" 11 "KeyId1_Key11";
VAL_ 369 BtnUnlckStsAndKeyIdBtnSts 0 "PsdNotPsd1_NotPsd" 1 "PsdNotPsd1_Psd";
VAL_ 369 BtnUnlckStsAndKeyIdKeyId 0 "KeyId1_Key0" 1 "KeyId1_Key1" 2 "KeyId1_Key2" 3 "KeyId1_Key3" 4 "KeyId1_Key4" 5 "KeyId1_Key5" 6 "KeyId1_Key6" 7 "KeyId1_Key7" 8 "KeyId1_Key8" 9 "KeyId1_Key9" 10 "KeyId1_Key10" 11 "KeyId1_Key11";
VAL_ 369 CoolgLoadGroupCoolgLimd 0 "Flg1_Rst" 1 "Flg1_Set";
VAL_ 369 DigKeyApproachReqDigKeyApproaReq 0 "DigKeyApproaReq_Idle" 1 "DigKeyApproaReq_ApproachLightRequest" 2 "DigKeyApproaReq_ApproachUnlockRequest" 3 "DigKeyApproaReq_ApproachLockRequest" 4 "DigKeyApproaReq_ApproachTrunkRequest1" 5 "DigKeyApproaReq_ApproachTrunkRequest2" 6 "DigKeyApproaReq_ApproachTrunkRequest3" 7 "DigKeyApproaReq_ApproachUnlckReqFromDrvr";
VAL_ 369 DigKeyApproachReqKeyId3 0 "KeyId3_Key0" 1 "KeyId3_Key1" 2 "KeyId3_Key2" 3 "KeyId3_Key3" 4 "KeyId3_Key4" 5 "KeyId3_Key5" 6 "KeyId3_Key6" 7 "KeyId3_Key7" 8 "KeyId3_Key8" 9 "KeyId3_Key9" 10 "KeyId3_Key10" 11 "KeyId3_Key11" 12 "KeyId3_Key12" 13 "KeyId3_Key13" 14 "KeyId3_Key14" 15 "KeyId3_Key15";
VAL_ 369 DoorLockUnlockCmdNFCKeyId3 0 "KeyId3_Key0" 1 "KeyId3_Key1" 2 "KeyId3_Key2" 3 "KeyId3_Key3" 4 "KeyId3_Key4" 5 "KeyId3_Key5" 6 "KeyId3_Key6" 7 "KeyId3_Key7" 8 "KeyId3_Key8" 9 "KeyId3_Key9" 10 "KeyId3_Key10" 11 "KeyId3_Key11" 12 "KeyId3_Key12" 13 "KeyId3_Key13" 14 "KeyId3_Key14" 15 "KeyId3_Key15";
VAL_ 369 DoorLockUnlockCmdNFCKeyPrsntSts1 0 "KeyPrsntSts1_KeyPrsntStsIdle" 1 "KeyPrsntSts1_KeyPrsntStsInProgs" 2 "KeyPrsntSts1_KeyPrsntStsNotPrsnt" 3 "KeyPrsntSts1_KeyPrsntStsPrsnt";
VAL_ 369 DoorLockUnlockCmdNFCPsdNotPsd 0 "PsdNotPsd_NotPsd" 1 "PsdNotPsd_Psd";
VAL_ 369 DoorPassHndlCmd 0 "DoorHndlCmd_Idle" 1 "DoorHndlCmd_Deploy" 2 "DoorHndlCmd_Retract";
VAL_ 369 DoorRiReHndlCmd 0 "DoorHndlCmd_Idle" 1 "DoorHndlCmd_Deploy" 2 "DoorHndlCmd_Retract";
VAL_ 369 DrvrSeatPosPercSeatPosFrntHeiQF 0 "Qf1_DevOfDataUndefd" 1 "Qf1_DataTmpUndefdAndEvlnInProgs" 2 "Qf1_DevOfDataNotWithinRngAllwd" 3 "Qf1_DataCalcdWithDevDefd";
VAL_ 369 DrvrSeatPosPercSeatPosHeiQF 0 "Qf1_DevOfDataUndefd" 1 "Qf1_DataTmpUndefdAndEvlnInProgs" 2 "Qf1_DevOfDataNotWithinRngAllwd" 3 "Qf1_DataCalcdWithDevDefd";
VAL_ 369 DrvrSeatPosPercSeatPosSldQF 0 "Qf1_DevOfDataUndefd" 1 "Qf1_DataTmpUndefdAndEvlnInProgs" 2 "Qf1_DevOfDataNotWithinRngAllwd" 3 "Qf1_DataCalcdWithDevDefd";
VAL_ 369 EgyAvgCnsDstSg 0 "Boolean_FALSE" 1 "Boolean_TRUE";
VAL_ 369 GearIndcnRecGearIndcn 0 "GearIndcnTyp2_NoIndcn" 1 "GearIndcnTyp2_Gear1" 2 "GearIndcnTyp2_Gear2" 3 "GearIndcnTyp2_Gear3" 4 "GearIndcnTyp2_Gear4" 5 "GearIndcnTyp2_Gear5" 6 "GearIndcnTyp2_Gear6" 7 "GearIndcnTyp2_Gear7" 8 "GearIndcnTyp2_Gear8" 9 "GearIndcnTyp2_Gear9" 10 "GearIndcnTyp2_Gear10" 11 "GearIndcnTyp2_Gear11" 12 "GearIndcnTyp2_Gear2468" 13 "GearIndcnTyp2_Gear13579" 14 "GearIndcnTyp2_Neut" 15 "GearIndcnTyp2_Rvs";
VAL_ 369 GearIndcnRecGearShiftIndcn 0 "GearShiftIndcn_NoShiftIndcn" 1 "GearShiftIndcn_ShiftUpIndcn" 2 "GearShiftIndcn_CoolShiftIndcn" 3 "GearShiftIndcn_ShiftDwnIndcn";
VAL_ 369 GearIndcnRecGearTarIndcn 0 "GearIndcnTyp2_NoIndcn" 1 "GearIndcnTyp2_Gear1" 2 "GearIndcnTyp2_Gear2" 3 "GearIndcnTyp2_Gear3" 4 "GearIndcnTyp2_Gear4" 5 "GearIndcnTyp2_Gear5" 6 "GearIndcnTyp2_Gear6" 7 "GearIndcnTyp2_Gear7" 8 "GearIndcnTyp2_Gear8" 9 "GearIndcnTyp2_Gear9" 10 "GearIndcnTyp2_Gear10" 11 "GearIndcnTyp2_Gear11" 12 "GearIndcnTyp2_Gear2468" 13 "GearIndcnTyp2_Gear13579" 14 "GearIndcnTyp2_Neut" 15 "GearIndcnTyp2_Rvs";
VAL_ 369 ImobRemMgrChkSts 0 "AvlSts1_TmpNotAvl" 1 "AvlSts1_PrmntNotAvl" 2 "AvlSts1_Avl";
VAL_ 369 ImobVehRemMgrSts1ImobVehRemMgrSts 0 "ImobVehRemMgrSts_IdleRemMgrSts" 1 "ImobVehRemMgrSts_ImobnRemMgrSts" 2 "ImobVehRemMgrSts_NoImobnRemMgrSts" 3 "ImobVehRemMgrSts_ImobnStrtDiRemMgrSts";
VAL_ 369 LnchModIndcnMsg 0 "LaunchModeIndcn_NoIndcn" 1 "LaunchModeIndcn_BattLow" 2 "LaunchModeIndcn_TempTooHigh" 3 "LaunchModeIndcn_TempTooLow" 4 "LaunchModeIndcn_EscNotOff" 5 "LaunchModeIndcn_TrlrPrsnt" 6 "LaunchModeIndcn_SteerWhlNotStraight" 7 "LaunchModeIndcn_EpbNotRels" 8 "LaunchModeIndcn_BltNotRels" 9 "LaunchModeIndcn_DoorNotClsd" 10 "LaunchModeIndcn_FctNotTrigTiOut" 11 "LaunchModeIndcn_BrkPedlPsdTiOut" 12 "LaunchModeIndcn_FctReqTooFrequent" 13 "LaunchModeIndcn_Reserved1" 14 "LaunchModeIndcn_Reserved2" 15 "LaunchModeIndcn_Reserved3";
VAL_ 369 LockgFbAcoustReq 0 "LockActvn2_LockActvnOff" 1 "LockActvn2_LockActvnUnlck" 2 "LockActvn2_LockActvnLock" 3 "LockActvn2_LockActvnSafe" 4 "LockActvn2_LockActvnUnlckByCrash";
VAL_ 369 LockgFbToExtLi 0 "LockActvn2_LockActvnOff" 1 "LockActvn2_LockActvnUnlck" 2 "LockActvn2_LockActvnLock" 3 "LockActvn2_LockActvnSafe" 4 "LockActvn2_LockActvnUnlckByCrash";
VAL_ 369 MobDevVentReq 0 "PsdNotPsd1_NotPsd" 1 "PsdNotPsd1_Psd";
VAL_ 369 OpenClsCmftReqOpenClsCmftReq 0 "OpenClsCmftReq1_NoCmftReq" 1 "OpenClsCmftReq1_OpenCmft" 2 "OpenClsCmftReq1_ClsCmft" 3 "OpenClsCmftReq1_StopCmft";
VAL_ 369 OpenClsCmftReqOpenClsCmftTrigSrc 0 "OpenClsCmftTrigSrc1_OpenClsCmftNoTrigSrc" 1 "OpenClsCmftTrigSrc1_OpenClsCmftFromSwtInt" 2 "OpenClsCmftTrigSrc1_OpenClsCmfFromKeyRem" 3 "OpenClsCmftTrigSrc1_OpenClsCmftFromKeyls";
VAL_ 369 PassMidSeatSts 0 "PassSeatSts1_Empty" 1 "PassSeatSts1_Fmale" 2 "PassSeatSts1_OccptLrg" 3 "PassSeatSts1_Ukwn";
VAL_ 369 RainDetected 0 "Boolean_FALSE" 1 "Boolean_TRUE";
VAL_ 369 RemAllowStrt 0 "Validity_NotValid" 1 "Validity_Valid";
VAL_ 369 SeatOccptAtRowFrthLe 0 "PassSeatSts1_Empty" 1 "PassSeatSts1_Fmale" 2 "PassSeatSts1_OccptLrg" 3 "PassSeatSts1_Ukwn";
VAL_ 369 SeatOccptAtRowFrthMid 0 "PassSeatSts1_Empty" 1 "PassSeatSts1_Fmale" 2 "PassSeatSts1_OccptLrg" 3 "PassSeatSts1_Ukwn";
VAL_ 369 SeatOccptAtRowFrthRi 0 "PassSeatSts1_Empty" 1 "PassSeatSts1_Fmale" 2 "PassSeatSts1_OccptLrg" 3 "PassSeatSts1_Ukwn";
VAL_ 369 SeatOccptAtRowThrdMid 0 "PassSeatSts1_Empty" 1 "PassSeatSts1_Fmale" 2 "PassSeatSts1_OccptLrg" 3 "PassSeatSts1_Ukwn";
VAL_ 369 ShortDropWinLeReDoor2 0 "ShortDrop_Idle" 1 "ShortDrop_Close" 2 "ShortDrop_Open";
VAL_ 369 ShortDropWinPassDoor2 0 "ShortDrop_Idle" 1 "ShortDrop_Close" 2 "ShortDrop_Open";
VAL_ 369 ShortDropWinRiReDoor2 0 "ShortDrop_Idle" 1 "ShortDrop_Close" 2 "ShortDrop_Open";
VAL_ 369 SunCurtPosnSts 0 "WinAndRoofAndCurtPosnTyp_PosnUkwn" 1 "WinAndRoofAndCurtPosnTyp_ClsFull" 2 "WinAndRoofAndCurtPosnTyp_PercOpen4" 3 "WinAndRoofAndCurtPosnTyp_PercOpen8" 4 "WinAndRoofAndCurtPosnTyp_PercOpen12" 5 "WinAndRoofAndCurtPosnTyp_PercOpen16" 6 "WinAndRoofAndCurtPosnTyp_PercOpen20" 7 "WinAndRoofAndCurtPosnTyp_PercOpen24" 8 "WinAndRoofAndCurtPosnTyp_PercOpen28" 9 "WinAndRoofAndCurtPosnTyp_PercOpen32" 10 "WinAndRoofAndCurtPosnTyp_PercOpen36" 11 "WinAndRoofAndCurtPosnTyp_PercOpen40" 12 "WinAndRoofAndCurtPosnTyp_PercOpen44" 13 "WinAndRoofAndCurtPosnTyp_PercOpen48" 14 "WinAndRoofAndCurtPosnTyp_PercOpen52" 15 "WinAndRoofAndCurtPosnTyp_PercOpen56" 16 "WinAndRoofAndCurtPosnTyp_PercOpen60" 17 "WinAndRoofAndCurtPosnTyp_PercOpen64" 18 "WinAndRoofAndCurtPosnTyp_PercOpen68" 19 "WinAndRoofAndCurtPosnTyp_PercOpen72" 20 "WinAndRoofAndCurtPosnTyp_PercOpen76" 21 "WinAndRoofAndCurtPosnTyp_PercOpen80" 22 "WinAndRoofAndCurtPosnTyp_PercOpen84" 23 "WinAndRoofAndCurtPosnTyp_PercOpen88" 24 "WinAndRoofAndCurtPosnTyp_PercOpen92" 25 "WinAndRoofAndCurtPosnTyp_PercOpen96" 26 "WinAndRoofAndCurtPosnTyp_OpenFull" 27 "WinAndRoofAndCurtPosnTyp_Resd1" 28 "WinAndRoofAndCurtPosnTyp_Resd2" 29 "WinAndRoofAndCurtPosnTyp_Resd3" 30 "WinAndRoofAndCurtPosnTyp_Resd4" 31 "WinAndRoofAndCurtPosnTyp_Movg";
VAL_ 369 TankFlapLockgCmd 0 "LockActvn2_LockActvnOff" 1 "LockActvn2_LockActvnUnlck" 2 "LockActvn2_LockActvnLock" 3 "LockActvn2_LockActvnSafe" 4 "LockActvn2_LockActvnUnlckByCrash";
VAL_ 369 TrHndlOutdOpenSts 0 "PsdNotPsd1_NotPsd" 1 "PsdNotPsd1_Psd";
VAL_ 369 TrsmFltIndcn 0 "TrsmFltIndcn1_TrsmFltIndcnNoReq" 1 "TrsmFltIndcn1_TrsmFltIndcn1" 2 "TrsmFltIndcn1_TrsmFltIndcn2" 3 "TrsmFltIndcn1_TrsmFltIndcn3" 4 "TrsmFltIndcn1_TrsmFltIndcn4" 5 "TrsmFltIndcn1_TrsmFltIndcn5" 6 "TrsmFltIndcn1_TrsmFltIndcn6" 7 "TrsmFltIndcn1_TrsmFltIndcn7" 8 "TrsmFltIndcn1_TrsmFltIndcn8" 9 "TrsmFltIndcn1_TrsmFltIndcn9" 10 "TrsmFltIndcn1_TrsmFltIndcn10" 11 "TrsmFltIndcn1_TrsmFltIndcn11" 12 "TrsmFltIndcn1_TrsmFltIndcn12" 13 "TrsmFltIndcn1_TrsmFltIndcn13" 14 "TrsmFltIndcn1_TrsmFltIndcn14" 15 "TrsmFltIndcn1_TrsmFltIndcn15" 16 "TrsmFltIndcn1_TrsmFltIndcn16" 17 "TrsmFltIndcn1_TrsmFltIndcn17" 18 "TrsmFltIndcn1_TrsmFltIndcn18" 19 "TrsmFltIndcn1_TrsmFltIndcn19" 20 "TrsmFltIndcn1_TrsmFltIndcn20" 21 "TrsmFltIndcn1_TrsmFltIndcn21" 22 "TrsmFltIndcn1_TrsmFltIndcn22" 23 "TrsmFltIndcn1_TrsmFltIndcn23" 24 "TrsmFltIndcn1_TrsmFltIndcn24" 25 "TrsmFltIndcn1_TrsmFltIndcn25" 26 "TrsmFltIndcn1_TrsmFltIndcn26" 27 "TrsmFltIndcn1_TrsmFltIndcn27" 28 "TrsmFltIndcn1_TrsmFltIndcn28" 29 "TrsmFltIndcn1_TrsmFltIndcn29" 30 "TrsmFltIndcn1_TrsmFltIndcn30" 31 "TrsmFltIndcn1_TrsmFltIndcn31";
VAL_ 666 ActvnOfWshrFrntSafe 0 "OnOffCrit1_NotVld1" 1 "OnOffCrit1_Off" 2 "OnOffCrit1_On" 3 "OnOffCrit1_NotVld2";
VAL_ 666 ActvOfHorn 0 "OnOff1_Off" 1 "OnOff1_On";
VAL_ 666 DChrgStrtEngRes 0 "DChrgStrt_NotSet" 1 "DChrgStrt_Start" 2 "DChrgStrt_Finished" 3 "DChrgStrt_MaxNoStart" 4 "DChrgStrt_HoodOpen" 5 "DChrgStrt_CarUnlocked" 6 "DChrgStrt_ValidKeyInCar" 7 "DChrgStrt_PwrSplyErr" 8 "DChrgStrt_FuelLow" 9 "DChrgStrt_PropFlt" 10 "DChrgStrt_MaxTi" 11 "DChrgStrt_NoValidKeyInCar";
VAL_ 666 EngCooltInhbFlow 0 "CooltInhb_CoolntFlowReqToEngAllwd" 1 "CooltInhb_CoolntFlowReqToEngNotAllwd";
VAL_ 666 HvahFltIndcnReq 0 "Flg1_Rst" 1 "Flg1_Set";
VAL_ 666 HvEgyLoadFctReq 0 "Boolean_FALSE" 1 "Boolean_TRUE";
VAL_ 666 HvPwrEgyPrio 0 "HvPwrEgyPrio_Standby" 1 "HvPwrEgyPrio_Dischrgning" 2 "HvPwrEgyPrio_Chrgning" 3 "HvPwrEgyPrio_ClimaWithAc" 4 "HvPwrEgyPrio_ClimaWithoutAc" 5 "HvPwrEgyPrio_RemoteClimatisaiton";
VAL_ 666 HwRowRearLeLegRstHeiMotCtrl 0 "SwtVertSts1_Idle" 1 "SwtVertSts1_Up" 2 "SwtVertSts1_Dwn";
VAL_ 666 HwRowRearLeLegRstLenMotCtrl 0 "SwtHozlSts1_Idle" 1 "SwtHozlSts1_Fwd" 2 "SwtHozlSts1_Backw";
VAL_ 666 HwRowRearRiLegRstHeiMotCtrl 0 "SwtVertSts1_Idle" 1 "SwtVertSts1_Up" 2 "SwtVertSts1_Dwn";
VAL_ 666 HwRowRearRiLegRstLenMotCtrl 0 "SwtHozlSts1_Idle" 1 "SwtHozlSts1_Fwd" 2 "SwtHozlSts1_Backw";
VAL_ 666 HwRowSecLeInclMotCtrl 0 "SwtHozlSts1_Idle" 1 "SwtHozlSts1_Fwd" 2 "SwtHozlSts1_Backw";
VAL_ 666 HwRowSecLeSldMotCtrl 0 "SwtHozlSts1_Idle" 1 "SwtHozlSts1_Fwd" 2 "SwtHozlSts1_Backw";
VAL_ 666 HwRowSecRiInclMotCtrl 0 "SwtHozlSts1_Idle" 1 "SwtHozlSts1_Fwd" 2 "SwtHozlSts1_Backw";
VAL_ 666 HwRowSecRiSldMotCtrl 0 "SwtHozlSts1_Idle" 1 "SwtHozlSts1_Fwd" 2 "SwtHozlSts1_Backw";
VAL_ 666 HwRowThrdLeInclMotCtrl 0 "SwtHozlSts1_Idle" 1 "SwtHozlSts1_Fwd" 2 "SwtHozlSts1_Backw";
VAL_ 666 HwRowThrdRiInclMotCtrl 0 "SwtHozlSts1_Idle" 1 "SwtHozlSts1_Fwd" 2 "SwtHozlSts1_Backw";
VAL_ 666 MirrActvBtn 0 "PsdNotPsd_NotPsd" 1 "PsdNotPsd_Psd";
VAL_ 666 MirrCmdAtDrvrMirrDwnCmd 0 "MirrDwnCmdTyp_Idle" 1 "MirrDwnCmdTyp_MirrUp" 2 "MirrDwnCmdTyp_MirrDwn";
VAL_ 666 MirrCmdAtDrvrMirrFoldCmd 0 "MirrFoldCmdTyp_Idle" 1 "MirrFoldCmdTyp_FoldIn" 2 "MirrFoldCmdTyp_FoldOut";
VAL_ 666 MirrCmdAtDrvrMirrPosAdjCmd 0 "MirrAdjCmdTyp_Idle" 1 "MirrAdjCmdTyp_Up" 2 "MirrAdjCmdTyp_Dwn" 3 "MirrAdjCmdTyp_Le" 4 "MirrAdjCmdTyp_Ri";
VAL_ 666 MirrDefrstAtDrvSts 0 "OnOff1_Off" 1 "OnOff1_On";
VAL_ 666 MirrDirReq 0 "MirrDirReqTyp_Idle" 1 "MirrDirReqTyp_Up" 2 "MirrDirReqTyp_Down" 3 "MirrDirReqTyp_Left" 4 "MirrDirReqTyp_Right";
VAL_ 666 MirrSelnReq 0 "MirrSelnReqTyp_Idle" 1 "MirrSelnReqTyp_Le" 2 "MirrSelnReqTyp_Ri" 3 "MirrSelnReqTyp_LeAndRi";
VAL_ 666 TrlrModPrpsnSts 0 "VehActv1_NoMsg" 1 "VehActv1_Msg1" 2 "VehActv1_Msg2" 3 "VehActv1_Msg3";
VAL_ 336 ChrgLidRearLockCmd 0 "LockActvn2_LockActvnOff" 1 "LockActvn2_LockActvnUnlck" 2 "LockActvn2_LockActvnLock" 3 "LockActvn2_LockActvnSafe" 4 "LockActvn2_LockActvnUnlckByCrash";
VAL_ 336 ChrgnOrDisChrgnStsFb 0 "ChrgnSts2_Default" 1 "ChrgnSts2_NoCharging" 2 "ChrgnSts2_ACCharging" 3 "ChrgnSts2_ChargingEnd" 4 "ChrgnSts2_ChargingCmpl" 5 "ChrgnSts2_Heating" 6 "ChrgnSts2_Booking" 7 "ChrgnSts2_NoDischaring" 8 "ChrgnSts2_Discharging" 9 "ChrgnSts2_DischargingEnd" 10 "ChrgnSts2_DischargingCmpl" 11 "ChrgnSts2_Chargingfalut" 12 "ChrgnSts2_DischargingFalut" 14 "ChrgnSts2_ACChrgnFltChrgrSide" 15 "ChrgnSts2_DCCharging" 18 "ChrgnSts2_DCChrgnFltVehSide" 19 "ChrgnSts2_DCChrgnFltChrgrSideTempFlt" 20 "ChrgnSts2_DCChrgnFltChrgrSideConFlt" 21 "ChrgnSts2_DCChrgnFltChrgrSideHwFlt" 22 "ChrgnSts2_DCChrgnFltChrgrSideEmgyFlt" 23 "ChrgnSts2_DCChrgnFltChrgrSideComFlt" 24 "ChrgnSts2_SuperCharging" 25 "ChrgnSts2_ACChargingSuspend" 26 "ChrgnSts2_DCChargingEnd" 27 "ChrgnSts2_ACChrgnFltVehSide" 28 "ChrgnSts2_Boostcharging" 29 "ChrgnSts2_BoostchargingFlt" 30 "ChrgnSts2_WirelessCharging";
VAL_ 336 DispOfPrpsnMod 0 "DispOfPrpsnMod4_NotRdy" 1 "DispOfPrpsnMod4_ChrgnWithOnBdChrgr" 2 "DispOfPrpsnMod4_PrpsnMotElecAndPrpsnEng" 3 "DispOfPrpsnMod4_PrpsnMotElecAndPrpsnEngAndChrgn" 4 "DispOfPrpsnMod4_OnlyEngPrpsn" 5 "DispOfPrpsnMod4_OnlyEngPrpsnAndChrgn" 6 "DispOfPrpsnMod4_OnlyPrpsnMotElec" 7 "DispOfPrpsnMod4_NoPrpsnMotElecAndEngOff" 8 "DispOfPrpsnMod4_NoPrpsnMotElecAndOnEng" 9 "DispOfPrpsnMod4_NoPrpsnMotElecAndOnEngAndChrgn" 10 "DispOfPrpsnMod4_BrkgRgnAndEngOff" 11 "DispOfPrpsnMod4_BrkgRgnAndOnEng" 12 "DispOfPrpsnMod4_BrkgRgnAndEngOnAndChrgn" 13 "DispOfPrpsnMod4_Abnormal" 14 "DispOfPrpsnMod4_PrpsnMotElecAndEngChrgn" 15 "DispOfPrpsnMod4_PrpsnMotElecAndEngOn";
VAL_ 336 DstFromDestinationFb 0 "DstFromDestinationResp_Default" 1 "DstFromDestinationResp_Success" 2 "DstFromDestinationResp_Fault" 3 "DstFromDestinationResp_EndOfDischarge" 4 "DstFromDestinationResp_Reserved0" 5 "DstFromDestinationResp_Reserved1" 6 "DstFromDestinationResp_Reserved2" 7 "DstFromDestinationResp_Reserved3";
VAL_ 336 KeyLostWarnIndcn 0 "KeyLostWarnIndcn_KeyLostNoMsg" 1 "KeyLostWarnIndcn_KeyMsgAndSoundLost" 2 "KeyLostWarnIndcn_KeyMsgLost";
VAL_ 336 KeyRmnIndcn 0 "OnOff1_Off" 1 "OnOff1_On";
VAL_ 336 LockgFbAudioReq 0 "LockActvn2_LockActvnOff" 1 "LockActvn2_LockActvnUnlck" 2 "LockActvn2_LockActvnLock" 3 "LockActvn2_LockActvnSafe" 4 "LockActvn2_LockActvnUnlckByCrash";
VAL_ 336 MemBtnPsdMemBtn1 0 "Boolean_FALSE" 1 "Boolean_TRUE";
VAL_ 336 MemBtnPsdMemBtn2 0 "Boolean_FALSE" 1 "Boolean_TRUE";
VAL_ 336 MemBtnPsdMemBtn3 0 "Boolean_FALSE" 1 "Boolean_TRUE";
VAL_ 336 MemBtnPsdMemButM 0 "Boolean_FALSE" 1 "Boolean_TRUE";
VAL_ 336 RowSecLeSeatInAutMovmt 0 "Boolean_FALSE" 1 "Boolean_TRUE";
VAL_ 336 RowSecRiSeatInAutMovmt 0 "Boolean_FALSE" 1 "Boolean_TRUE";
VAL_ 336 WadeProtnIndcn 0 "WadeProtnIndcn_Default" 1 "WadeProtnIndcn_OFF" 2 "WadeProtnIndcn_ON" 3 "WadeProtnIndcn_CdnNotMet" 4 "WadeProtnIndcn_LowLvSoc" 5 "WadeProtnIndcn_EngStall" 6 "WadeProtnIndcn_LowHvBattSoc" 7 "WadeProtnIndcn_Reserved";
SIG_GROUP_ 1169 AccrpedlSts 1 : AccrpedlStsChks AccrpedlStsCntr AccrpedlStsFltSts;
SIG_GROUP_ 1169 ActnOfLedLoBeam 1 : ActnOfLedLoBeamActnOfLedLoBeam ActnOfLedLoBeamChks ActnOfLedLoBeamCntr;
SIG_GROUP_ 306 ActnOfLoBeamPass 1 : ActnOfLoBeamPassChks ActnOfLoBeamPassCntr ActnOfLoBeamPassOnOff;
SIG_GROUP_ 306 ActvnOfHndlDoorLi1 1 : ActvnOfHndlDoorLi1HndlDoorLiDrvr ActvnOfHndlDoorLi1HndlDoorLiDrvrRe ActvnOfHndlDoorLi1HndlDoorLiPass ActvnOfHndlDoorLi1HndlDoorLiPassRe;
SIG_GROUP_ 306 BattFltStsPrim 1 : BattFltStsPrimBattFltStsPrm BattFltStsPrimChks BattFltStsPrimCntr;
SIG_GROUP_ 369 BltLockStAtPassMid 1 : BltLockStAtPassMidBltLockEquid BltLockStAtPassMidBltLockSt1 BltLockStAtPassMidBltLockSts;
SIG_GROUP_ 369 BltLockStAtRowFrthLe 1 : BltLockStAtRowFrthLeBltLockEquid BltLockStAtRowFrthLeBltLockSt1 BltLockStAtRowFrthLeBltLockSts;
SIG_GROUP_ 369 BltLockStAtRowFrthMid 1 : BltLockStAtRowFrthMidBltLockEquid BltLockStAtRowFrthMidBltLockSt1 BltLockStAtRowFrthMidBltLockSts;
SIG_GROUP_ 369 BltLockStAtRowFrthRi 1 : BltLockStAtRowFrthRiBltLockEquid BltLockStAtRowFrthRiBltLockSt1 BltLockStAtRowFrthRiBltLockSts;
SIG_GROUP_ 369 BltLockStAtRowThrdMid 1 : BltLockStAtRowThrdMidBltLockEquid BltLockStAtRowThrdMidBltLockSt1 BltLockStAtRowThrdMidBltLockSts;
SIG_GROUP_ 369 BtnLockStsAndKeyId 1 : BtnLockStsAndKeyIdBtnSts BtnLockStsAndKeyIdKeyId;
SIG_GROUP_ 369 BtnUnlckStsAndKeyId 1 : BtnUnlckStsAndKeyIdBtnSts BtnUnlckStsAndKeyIdKeyId;
SIG_GROUP_ 369 CchForFuEco 1 : CchForFuEcoBarForFuEco CchForFuEcoGrdForFuEco;
SIG_GROUP_ 369 CchForPwrEco 1 : CchForPwrEcoBarForPwrEco CchForPwrEcoGrdForPwrEco;
SIG_GROUP_ 1169 CEMdevelpsignalgroupVMM1 1 : CEMdevelpsignalgroupVMM1Functiondevpsignalgroup1 CEMdevelpsignalgroupVMM1Functiondevpsignalgroup2 CEMdevelpsignalgroupVMM1Functiondevpsignalgroup3 CEMdevelpsignalgroupVMM1Functiondevpsignalgroup4 CEMdevelpsignalgroupVMM1Functiondevpsignalgroup5 CEMdevelpsignalgroupVMM1Functiondevpsignalgroup6 CEMdevelpsignalgroupVMM1Functiondevpsignalgroup7 CEMdevelpsignalgroupVMM1Functiondevpsignalgroup8;
SIG_GROUP_ 369 CoolgLoadGroup 1 : CoolgLoadGroupCoolgLimd CoolgLoadGroupCoolgLoad2;
SIG_GROUP_ 369 DigKeyApproachReq 1 : DigKeyApproachReqDigKeyApproaReq DigKeyApproachReqKeyId3;
SIG_GROUP_ 369 DoorLockUnlockCmdNFC 1 : DoorLockUnlockCmdNFCKeyId3 DoorLockUnlockCmdNFCKeyPrsntSts1 DoorLockUnlockCmdNFCPsdNotPsd;
SIG_GROUP_ 369 DrvrSeatPosPerc 1 : DrvrSeatPosPercSeatPosFrntHeiPerc DrvrSeatPosPercSeatPosFrntHeiQF DrvrSeatPosPercSeatPosHeiPerc DrvrSeatPosPercSeatPosHeiQF DrvrSeatPosPercSeatPosSldPerc DrvrSeatPosPercSeatPosSldQF;
SIG_GROUP_ 1169 DrvrSteerWhlHldGroup 1 : DrvrSteerWhlHldGroupDrvrSteerWhlHld DrvrSteerWhlHldGroupDrvrSteerWhlHldQly;
SIG_GROUP_ 1169 EgyMeasIntl 1 : EgyMeasIntlIntl1 EgyMeasIntlIntl2 EgyMeasIntlIntl3 EgyMeasIntlIntl4;
SIG_GROUP_ 369 GearIndcnRec 1 : GearIndcnRecGearIndcn GearIndcnRecGearShiftIndcn GearIndcnRecGearTarIndcn;
SIG_GROUP_ 369 ImobRemMgrChk 1 : ImobRemMgrChkImobDataRemMgrChk0 ImobRemMgrChkImobDataRemMgrChk1 ImobRemMgrChkImobDataRemMgrChk2 ImobRemMgrChkImobDataRemMgrChk3 ImobRemMgrChkImobDataRemMgrChk4 ImobRemMgrChkSts;
SIG_GROUP_ 369 ImobVehRemMgrSts1 1 : ImobVehRemMgrSts1ImobVehRemMgrSts ImobVehRemMgrSts1SpdLimRemMgrSts;
SIG_GROUP_ 306 KeyEnaSts 1 : KeyEnaStsKey0 KeyEnaStsKey1 KeyEnaStsKey10 KeyEnaStsKey11 KeyEnaStsKey2 KeyEnaStsKey3 KeyEnaStsKey4 KeyEnaStsKey5 KeyEnaStsKey6 KeyEnaStsKey7 KeyEnaStsKey8 KeyEnaStsKey9;
SIG_GROUP_ 336 MemBtnPsd 1 : MemBtnPsdMemBtn1 MemBtnPsdMemBtn2 MemBtnPsdMemBtn3 MemBtnPsdMemButM;
SIG_GROUP_ 666 MirrCmdAtDrvr 1 : MirrCmdAtDrvrMirrDwnCmd MirrCmdAtDrvrMirrFoldCmd MirrCmdAtDrvrMirrPosAdjCmd;
SIG_GROUP_ 666 MirrPosnAdjFromSetTarPosnDrvr 1 : MirrPosnAdjFromSetTarPosnDrvrMirrPosnAdjCldLeRi MirrPosnAdjFromSetTarPosnDrvrMirrPosnAdjCldUpDwn;
SIG_GROUP_ 306 MirrPosnAdjFromSetTarPosnPass 1 : MirrPosnAdjFromSetTarPosnPassMirrPosnAdjCldLeRi MirrPosnAdjFromSetTarPosnPassMirrPosnAdjCldUpDwn;
SIG_GROUP_ 293 MusicInfoSeg11 1 : MusicInfoSeg11SegFftLiShow1 MusicInfoSeg11SegFftLiShow10 MusicInfoSeg11SegFftLiShow11 MusicInfoSeg11SegFftLiShow12 MusicInfoSeg11SegFftLiShow13 MusicInfoSeg11SegFftLiShow14 MusicInfoSeg11SegFftLiShow2 MusicInfoSeg11SegFftLiShow3 MusicInfoSeg11SegFftLiShow4 MusicInfoSeg11SegFftLiShow5 MusicInfoSeg11SegFftLiShow6 MusicInfoSeg11SegFftLiShow7 MusicInfoSeg11SegFftLiShow8 MusicInfoSeg11SegFftLiShow9 MusicInfoSeg11TimeFlagMessage MusicInfoSeg11TimeFlagMusicplay;
SIG_GROUP_ 293 MusicInfoSeg12 1 : MusicInfoSeg12SegFftLiShow15 MusicInfoSeg12SegFftLiShow16 MusicInfoSeg12SegFftLiShow17 MusicInfoSeg12SegFftLiShow18 MusicInfoSeg12SegFftLiShow19 MusicInfoSeg12SegFftLiShow20 MusicInfoSeg12SegFftLiShow21 MusicInfoSeg12SegFftLiShow22 MusicInfoSeg12SegFftLiShow23 MusicInfoSeg12SegFftLiShow24 MusicInfoSeg12SegFftLiShow25 MusicInfoSeg12SegFftLiShow26 MusicInfoSeg12SegFftLiShow27 MusicInfoSeg12SegFftLiShow28 MusicInfoSeg12TimeFlagMessage MusicInfoSeg12TimeFlagMusicplay;
SIG_GROUP_ 293 MusicInfoSeg13 1 : MusicInfoSeg13DownSamplingAmplitude MusicInfoSeg13MaxFFT100ms3kAmplitude MusicInfoSeg13MaxFFT100ms3kFrequency MusicInfoSeg13SegFftLiShow29 MusicInfoSeg13SegFftLiShow30 MusicInfoSeg13SegFftLiShow31 MusicInfoSeg13StateFlagMusicPlay MusicInfoSeg13StateFlagNewMusic MusicInfoSeg13TimeFlagMessage MusicInfoSeg13TimeFlagMusicplay;
SIG_GROUP_ 293 MusicInfoSeg21 1 : MusicInfoSeg21SegFftLiShow1 MusicInfoSeg21SegFftLiShow10 MusicInfoSeg21SegFftLiShow11 MusicInfoSeg21SegFftLiShow12 MusicInfoSeg21SegFftLiShow13 MusicInfoSeg21SegFftLiShow14 MusicInfoSeg21SegFftLiShow2 MusicInfoSeg21SegFftLiShow3 MusicInfoSeg21SegFftLiShow4 MusicInfoSeg21SegFftLiShow5 MusicInfoSeg21SegFftLiShow6 MusicInfoSeg21SegFftLiShow7 MusicInfoSeg21SegFftLiShow8 MusicInfoSeg21SegFftLiShow9 MusicInfoSeg21TimeFlagMessage MusicInfoSeg21TimeFlagMusicplay;
SIG_GROUP_ 293 MusicInfoSeg22 1 : MusicInfoSeg22SegFftLiShow15 MusicInfoSeg22SegFftLiShow16 MusicInfoSeg22SegFftLiShow17 MusicInfoSeg22SegFftLiShow18 MusicInfoSeg22SegFftLiShow19 MusicInfoSeg22SegFftLiShow20 MusicInfoSeg22SegFftLiShow21 MusicInfoSeg22SegFftLiShow22 MusicInfoSeg22SegFftLiShow23 MusicInfoSeg22SegFftLiShow24 MusicInfoSeg22SegFftLiShow25 MusicInfoSeg22SegFftLiShow26 MusicInfoSeg22SegFftLiShow27 MusicInfoSeg22SegFftLiShow28 MusicInfoSeg22TimeFlagMessage MusicInfoSeg22TimeFlagMusicplay;
SIG_GROUP_ 293 MusicInfoSeg23 1 : MusicInfoSeg23DownSamplingAmplitude MusicInfoSeg23MaxFFT100ms3kAmplitude MusicInfoSeg23MaxFFT100ms3kFrequency MusicInfoSeg23SegFftLiShow29 MusicInfoSeg23SegFftLiShow30 MusicInfoSeg23SegFftLiShow31 MusicInfoSeg23StateFlagMusicPlay MusicInfoSeg23StateFlagNewMusic MusicInfoSeg23TimeFlagMessage MusicInfoSeg23TimeFlagMusicplay;
SIG_GROUP_ 369 OpenClsCmftReq 1 : OpenClsCmftReqOpenClsCmftReq OpenClsCmftReqOpenClsCmftTrigSrc;
SIG_GROUP_ 306 SeatRowSecLeSwtSts 1 : SeatRowSecLeSwtStsPassSeatSwtAdjmtOfSpplFctHozlSts SeatRowSecLeSwtStsPassSeatSwtAdjmtOfSpplFctVerSts SeatRowSecLeSwtStsPassSeatSwtHdrstHozlSts SeatRowSecLeSwtStsPassSeatSwtHdrstVertSts SeatRowSecLeSwtStsPassSeatSwtHeiFrntSts SeatRowSecLeSwtStsPassSeatSwtHeiSts SeatRowSecLeSwtStsPassSeatSwtInclSts SeatRowSecLeSwtStsPassSeatSwtSelnOfSpplFctStsSts SeatRowSecLeSwtStsPassSeatSwtSldSts;
SIG_GROUP_ 306 SeatRowSecRiSwtSts 1 : SeatRowSecRiSwtStsPassSeatSwtAdjmtOfSpplFctHozlSts SeatRowSecRiSwtStsPassSeatSwtAdjmtOfSpplFctVerSts SeatRowSecRiSwtStsPassSeatSwtHdrstHozlSts SeatRowSecRiSwtStsPassSeatSwtHdrstVertSts SeatRowSecRiSwtStsPassSeatSwtHeiFrntSts SeatRowSecRiSwtStsPassSeatSwtHeiSts SeatRowSecRiSwtStsPassSeatSwtInclSts SeatRowSecRiSwtStsPassSeatSwtSelnOfSpplFctStsSts SeatRowSecRiSwtStsPassSeatSwtSldSts;
SIG_GROUP_ 306 SeatRowThrdRiFoldSts 1 : SeatRowThrdRiFoldStsSeatFoldRaiseFlt SeatRowThrdRiFoldStsSeatFoldRaiseMovmt;
SIG_GROUP_ 1377 ZCUDMdevelpsignalgroupReq 1 : ZCUDMdevelpsignalgroupReqFunctiondevpsignalgroup1 ZCUDMdevelpsignalgroupReqFunctiondevpsignalgroup2 ZCUDMdevelpsignalgroupReqFunctiondevpsignalgroup3 ZCUDMdevelpsignalgroupReqFunctiondevpsignalgroup4 ZCUDMdevelpsignalgroupReqFunctiondevpsignalgroup5 ZCUDMdevelpsignalgroupReqFunctiondevpsignalgroup6 ZCUDMdevelpsignalgroupReqFunctiondevpsignalgroup7 ZCUDMdevelpsignalgroupReqFunctiondevpsignalgroup8;
SIG_GROUP_ 1378 ZCUDMdevelpsignalgroupResp 1 : ZCUDMdevelpsignalgroupRespFunctiondevpsignalgroup1 ZCUDMdevelpsignalgroupRespFunctiondevpsignalgroup2 ZCUDMdevelpsignalgroupRespFunctiondevpsignalgroup3 ZCUDMdevelpsignalgroupRespFunctiondevpsignalgroup4 ZCUDMdevelpsignalgroupRespFunctiondevpsignalgroup5 ZCUDMdevelpsignalgroupRespFunctiondevpsignalgroup6 ZCUDMdevelpsignalgroupRespFunctiondevpsignalgroup7 ZCUDMdevelpsignalgroupRespFunctiondevpsignalgroup8;
SIG_GROUP_ 1378 ZCUDMDevpFrameForDebug 1 : ZCUDMDevpFrameForDebugFunctiondevpsignalgroup1 ZCUDMDevpFrameForDebugFunctiondevpsignalgroup2 ZCUDMDevpFrameForDebugFunctiondevpsignalgroup3 ZCUDMDevpFrameForDebugFunctiondevpsignalgroup4 ZCUDMDevpFrameForDebugFunctiondevpsignalgroup5 ZCUDMDevpFrameForDebugFunctiondevpsignalgroup6 ZCUDMDevpFrameForDebugFunctiondevpsignalgroup7 ZCUDMDevpFrameForDebugFunctiondevpsignalgroup8;
SIG_GROUP_ 1377 ZCUPdevelpsignalgroupReq 1 : ZCUPdevelpsignalgroupReqFunctiondevpsignalgroup1 ZCUPdevelpsignalgroupReqFunctiondevpsignalgroup2 ZCUPdevelpsignalgroupReqFunctiondevpsignalgroup3 ZCUPdevelpsignalgroupReqFunctiondevpsignalgroup4 ZCUPdevelpsignalgroupReqFunctiondevpsignalgroup5 ZCUPdevelpsignalgroupReqFunctiondevpsignalgroup6 ZCUPdevelpsignalgroupReqFunctiondevpsignalgroup7 ZCUPdevelpsignalgroupReqFunctiondevpsignalgroup8;
